VERSION ""

NS_ :

BS_:

BU_: PowertrainControlModule AtmosphericSensor SafetyRestraintSystem2 Aftertreatment_2_GasOutlet Aftertreatment_2_GasIntake DieselParticulateFilterControl Turbocharger SafetyRestraintSystem1 CabDisplay2 Aftertreatment_1_GasOutlet Aftertreatment_1_GasIntake OnBoardDataLogger OffBoardDiagnosticTool2 OffBoardDiagnosticTool1 FileServer ParkingBrakeController SeatController2 FanDriveController SteeringColumnUnit CommunicationUnitRadio CommunicationUnitSatellite CommunicationUnitCellular PropulsionBatteryCharger ChassisController2 ChassisController1 EngineValveControl AuxiliaryHeater2 AuxiliaryHeater1 ClutchUnit RampControl InformationSystem1 SuspensionSystemController2 OilSensor VehicleDynamicStability ExhaustEmissionController TransmissionDisplay2 TransmissionDisplay1 ClimateControl2 WaterPumpController RearAxleSteeringController LightingOperatorControl SeatController1 IgnitionController2 IgnitionController1 TirePressureController CabController2 CabController1 PneumaticSystemController SuspensionSystemController1 HydraulicPumpController EnduranceBrakingSystem RetarderExhaustEngine2 OnBoardDiagnosticUnit HeadwayController RetarderExhaustEngine1 CabDisplay1 ManagementComputer VirtualTerminal OffVehicleGateway PowerTakeOffFront HitchControl AuxiliaryValveControl BodyController TractorTrailerBridge1 StarterSystem ElectricalSystem VehicleSecurity VehicleNavigation AerodynamicControl ElectricalChargingSystem ClimateControl1 TripRecorder InstrumentCluster SuspensionDriveAxle2 SuspensionDriveAxle1 SuspensionSteerAxle SteeringController FuelSystem CruiseControl RetarderDriveline RetarderEngine BrakesDriveAxle2 BrakesDriveAxle1 BrakesSystemController BrakesSteerAxle AxleDrive2 AxleDrive1 AxleSteering PowerTakeOff ShiftConsoleSecondary ShiftConsolePrimary Transmission2 Transmission1 Engine2 Engine1

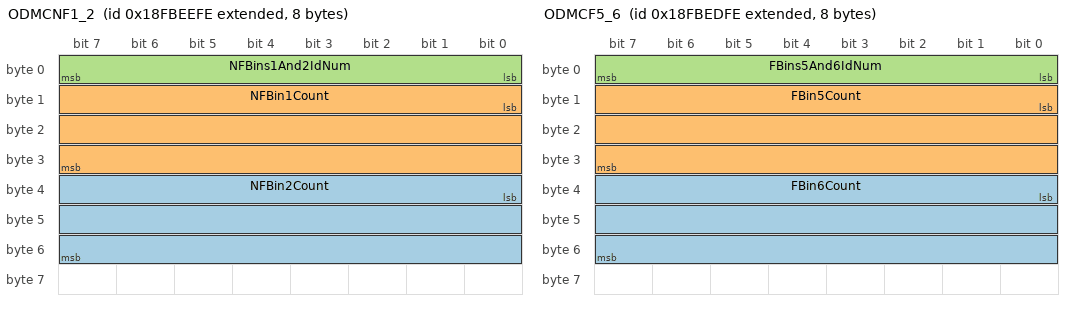
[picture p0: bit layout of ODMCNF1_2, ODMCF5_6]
BO_ 2566647550 ODMCNF1_2: 8 Vector__XXX
 SG_ NFBin2Count : 32|24@1+ (1,0) [0|16449535] "" Vector__XXX
 SG_ NFBin1Count : 8|24@1+ (1,0) [0|16449535] "" Vector__XXX
 SG_ NFBins1And2IdNum : 0|8@1+ (1,0) [0|250] "" Vector__XXX

BO_ 2566647294 ODMCF5_6: 8 Vector__XXX
 SG_ FBin6Count : 32|24@1+ (1,0) [0|16449535] "" Vector__XXX
 SG_ FBin5Count : 8|24@1+ (1,0) [0|16449535] "" Vector__XXX
 SG_ FBins5And6IdNum : 0|8@1+ (1,0) [0|250] "" Vector__XXX

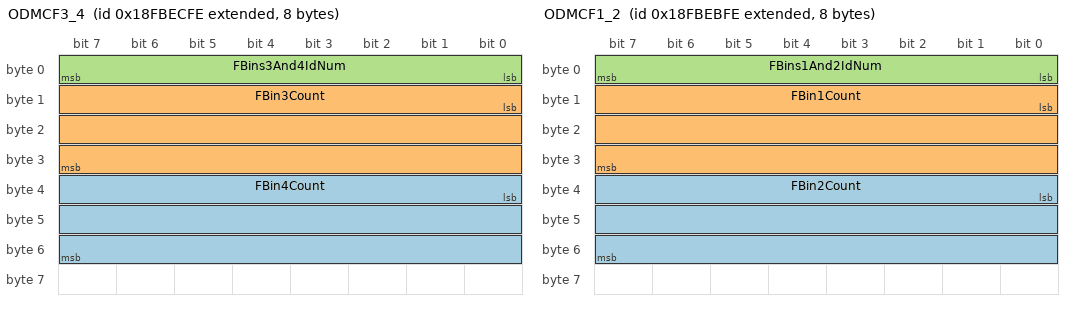
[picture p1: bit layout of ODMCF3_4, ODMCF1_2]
BO_ 2566647038 ODMCF3_4: 8 Vector__XXX
 SG_ FBin4Count : 32|24@1+ (1,0) [0|16449535] "" Vector__XXX
 SG_ FBin3Count : 8|24@1+ (1,0) [0|16449535] "" Vector__XXX
 SG_ FBins3And4IdNum : 0|8@1+ (1,0) [0|250] "" Vector__XXX

BO_ 2566646782 ODMCF1_2: 8 Vector__XXX
 SG_ FBin2Count : 32|24@1+ (1,0) [0|16449535] "" Vector__XXX
 SG_ FBin1Count : 8|24@1+ (1,0) [0|16449535] "" Vector__XXX
 SG_ FBins1And2IdNum : 0|8@1+ (1,0) [0|250] "" Vector__XXX

BO_ 2633755390 E1NET1: 8 Vector__XXX
 SG_ MACAddressOctet6 : 144|8@1+ (1,0) [0|255] "" Vector__XXX
 SG_ MACAddressOctet5 : 136|8@1+ (1,0) [0|255] "" Vector__XXX
 SG_ MACAddressOctet4 : 128|8@1+ (1,0) [0|255] "" Vector__XXX
 SG_ MACAddressOctet3 : 120|8@1+ (1,0) [0|255] "" Vector__XXX
 SG_ MACAddressOctet2 : 112|8@1+ (1,0) [0|255] "" Vector__XXX
 SG_ MACAddressOctet1 : 104|8@1+ (1,0) [0|255] "" Vector__XXX
 SG_ DefaultGatewayOctet4 : 96|8@1+ (1,0) [0|255] "" Vector__XXX
 SG_ DefaultGatewayOctet3 : 88|8@1+ (1,0) [0|255] "" Vector__XXX
 SG_ DefaultGatewayOctet2 : 80|8@1+ (1,0) [0|255] "" Vector__XXX
 SG_ DefaultGatewayOctet1 : 72|8@1+ (1,0) [0|255] "" Vector__XXX
 SG_ SubnetMaskOctet4 : 64|8@1+ (1,0) [0|255] "" Vector__XXX
 SG_ SubnetMaskOctet3 : 56|8@1+ (1,0) [0|255] "" Vector__XXX
 SG_ SubnetMaskOctet2 : 48|8@1+ (1,0) [0|255] "" Vector__XXX
 SG_ SubnetMaskOctet1 : 40|8@1+ (1,0) [0|255] "" Vector__XXX
 SG_ IPv4AddressOctet4 : 32|8@1+ (1,0) [0|255] "" Vector__XXX
 SG_ IPv4AddressOctet3 : 24|8@1+ (1,0) [0|255] "" Vector__XXX
 SG_ IPv4AddressOctet2 : 16|8@1+ (1,0) [0|255] "" Vector__XXX
 SG_ IPv4AddressOctet1 : 8|8@1+ (1,0) [0|255] "" Vector__XXX
 SG_ LinkStatus : 4|2@1+ (1,0) [0|3] "" Vector__XXX
 SG_ DHCPStatus : 0|4@1+ (1,0) [0|15] "" Vector__XXX

BO_ 2633755134 E1NET2: 8 Vector__XXX
 SG_ HostName : 0|8@1+ (1,0) [0|255] "" Vector__XXX

BO_ 2633754878 ASI2: 8 Vector__XXX
 SG_ TotalDEFUsed : 0|32@1+ (0.5,0) [0|2105540607.5] "l" Vector__XXX

BO_ 2633754622 SCROII5: 8 Vector__XXX
 SG_ EmergOvrdTotalActivationTime : 32|32@1+ (1,0) [0|4211081215] "s" Vector__XXX
 SG_ AFT1SCRInHiTempTime : 0|32@1+ (1,0) [0|4211081215] "s" Vector__XXX

BO_ 2365318910 HVESFC: 8 Vector__XXX
 SG_ HVESFanInstance15 : 46|1@1+ (1,0) [0|1] "" Vector__XXX
 SG_ HVESFanInstance14 : 45|1@1+ (1,0) [0|1] "" Vector__XXX
 SG_ HVESFanInstance13 : 44|1@1+ (1,0) [0|1] "" Vector__XXX
 SG_ HVESFanInstance12 : 43|1@1+ (1,0) [0|1] "" Vector__XXX
 SG_ HVESFanInstance11 : 42|1@1+ (1,0) [0|1] "" Vector__XXX
 SG_ HVESFanInstance10 : 41|1@1+ (1,0) [0|1] "" Vector__XXX
 SG_ HVESFanInstance9 : 40|1@1+ (1,0) [0|1] "" Vector__XXX
 SG_ HVESFanInstance8 : 39|1@1+ (1,0) [0|1] "" Vector__XXX
 SG_ HVESFanInstance7 : 38|1@1+ (1,0) [0|1] "" Vector__XXX
 SG_ HVESFanInstance6 : 37|1@1+ (1,0) [0|1] "" Vector__XXX
 SG_ HVESFanInstance5 : 36|1@1+ (1,0) [0|1] "" Vector__XXX
 SG_ HVESFanInstance4 : 35|1@1+ (1,0) [0|1] "" Vector__XXX
 SG_ HVESFanInstance3 : 34|1@1+ (1,0) [0|1] "" Vector__XXX
 SG_ HVESFanInstance2 : 33|1@1+ (1,0) [0|1] "" Vector__XXX
 SG_ HVESFanInstance1 : 32|1@1+ (1,0) [0|1] "" Vector__XXX
 SG_ HVESFanPercentSpdCmd : 24|8@1+ (0.4,0) [0|100] "%" Vector__XXX
 SG_ HVESFanSpdCmd : 8|16@1+ (0.5,0) [0|32127.5] "rpm" Vector__XXX
 SG_ HVESFanPwrHold : 2|2@1+ (1,0) [0|3] "" Vector__XXX
 SG_ HVESFanEnableCmd : 0|2@1+ (1,0) [0|3] "" Vector__XXX

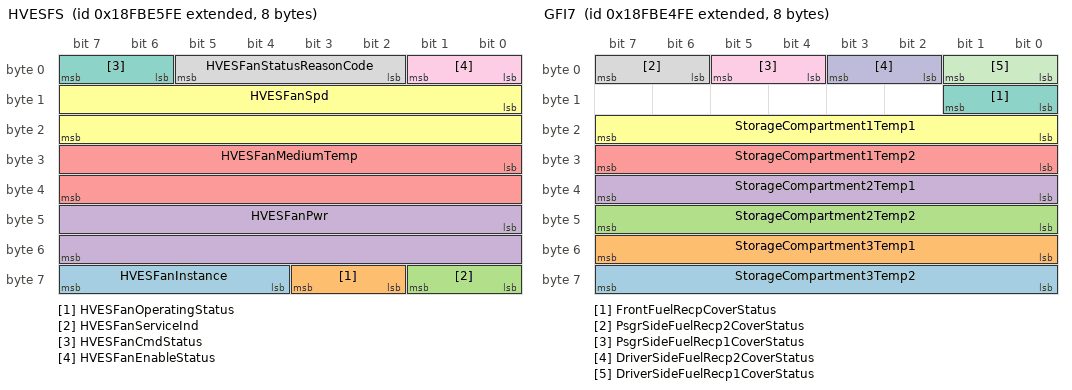
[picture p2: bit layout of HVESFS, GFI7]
BO_ 2566645246 HVESFS: 8 Vector__XXX
 SG_ HVESFanInstance : 60|4@1+ (1,0) [0|15] "" Vector__XXX
 SG_ HVESFanOperatingStatus : 58|2@1+ (1,0) [0|3] "" Vector__XXX
 SG_ HVESFanServiceInd : 56|2@1+ (1,0) [0|3] "" Vector__XXX
 SG_ HVESFanPwr : 40|16@1+ (0.5,0) [0|32127.5] "W" Vector__XXX
 SG_ HVESFanMediumTemp : 24|16@1+ (0.03125,-273) [-273|1734.96875] "캜" Vector__XXX
 SG_ HVESFanSpd : 8|16@1+ (0.5,0) [0|32127.5] "rpm" Vector__XXX
 SG_ HVESFanCmdStatus : 6|2@1+ (1,0) [0|3] "" Vector__XXX
 SG_ HVESFanStatusReasonCode : 2|4@1+ (1,0) [0|15] "" Vector__XXX
 SG_ HVESFanEnableStatus : 0|2@1+ (1,0) [0|3] "" Vector__XXX

BO_ 2566644990 GFI7: 8 Vector__XXX
 SG_ StorageCompartment3Temp2 : 56|8@1+ (1,-40) [-40|210] "캜" Vector__XXX
 SG_ StorageCompartment3Temp1 : 48|8@1+ (1,-40) [-40|210] "캜" Vector__XXX
 SG_ StorageCompartment2Temp2 : 40|8@1+ (1,-40) [-40|210] "캜" Vector__XXX
 SG_ StorageCompartment2Temp1 : 32|8@1+ (1,-40) [-40|210] "캜" Vector__XXX
 SG_ StorageCompartment1Temp2 : 24|8@1+ (1,-40) [-40|210] "캜" Vector__XXX
 SG_ StorageCompartment1Temp1 : 16|8@1+ (1,-40) [-40|210] "캜" Vector__XXX
 SG_ FrontFuelRecpCoverStatus : 8|2@1+ (1,0) [0|3] "" Vector__XXX
 SG_ PsgrSideFuelRecp2CoverStatus : 6|2@1+ (1,0) [0|3] "" Vector__XXX
 SG_ PsgrSideFuelRecp1CoverStatus : 4|2@1+ (1,0) [0|3] "" Vector__XXX
 SG_ DriverSideFuelRecp2CoverStatus : 2|2@1+ (1,0) [0|3] "" Vector__XXX
 SG_ DriverSideFuelRecp1CoverStatus : 0|2@1+ (1,0) [0|3] "" Vector__XXX

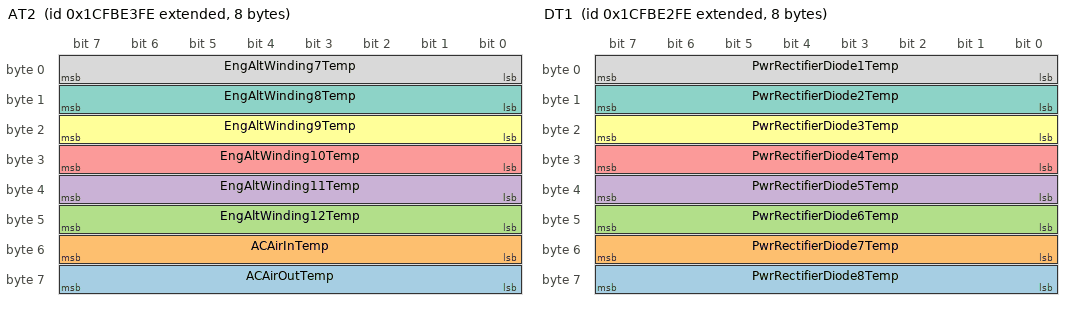
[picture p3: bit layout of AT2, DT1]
BO_ 2633753598 AT2: 8 Vector__XXX
 SG_ ACAirOutTemp : 56|8@1+ (1,-40) [-40|210] "캜" Vector__XXX
 SG_ ACAirInTemp : 48|8@1+ (1,-40) [-40|210] "캜" Vector__XXX
 SG_ EngAltWinding12Temp : 40|8@1+ (1,-40) [-40|210] "캜" Vector__XXX
 SG_ EngAltWinding11Temp : 32|8@1+ (1,-40) [-40|210] "캜" Vector__XXX
 SG_ EngAltWinding10Temp : 24|8@1+ (1,-40) [-40|210] "캜" Vector__XXX
 SG_ EngAltWinding9Temp : 16|8@1+ (1,-40) [-40|210] "캜" Vector__XXX
 SG_ EngAltWinding8Temp : 8|8@1+ (1,-40) [-40|210] "캜" Vector__XXX
 SG_ EngAltWinding7Temp : 0|8@1+ (1,-40) [-40|210] "캜" Vector__XXX

BO_ 2633753342 DT1: 8 Vector__XXX
 SG_ PwrRectifierDiode8Temp : 56|8@1+ (1,-40) [-40|210] "캜" Vector__XXX
 SG_ PwrRectifierDiode7Temp : 48|8@1+ (1,-40) [-40|210] "캜" Vector__XXX
 SG_ PwrRectifierDiode6Temp : 40|8@1+ (1,-40) [-40|210] "캜" Vector__XXX
 SG_ PwrRectifierDiode5Temp : 32|8@1+ (1,-40) [-40|210] "캜" Vector__XXX
 SG_ PwrRectifierDiode4Temp : 24|8@1+ (1,-40) [-40|210] "캜" Vector__XXX
 SG_ PwrRectifierDiode3Temp : 16|8@1+ (1,-40) [-40|210] "캜" Vector__XXX
 SG_ PwrRectifierDiode2Temp : 8|8@1+ (1,-40) [-40|210] "캜" Vector__XXX
 SG_ PwrRectifierDiode1Temp : 0|8@1+ (1,-40) [-40|210] "캜" Vector__XXX

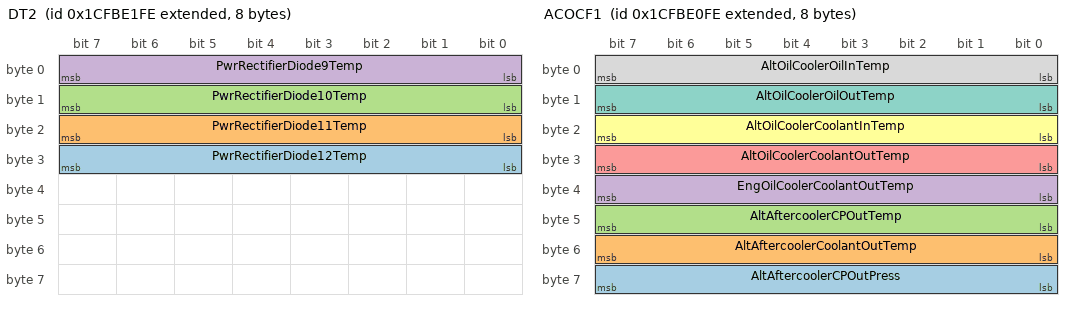
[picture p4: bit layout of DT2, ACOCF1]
BO_ 2633753086 DT2: 8 Vector__XXX
 SG_ PwrRectifierDiode12Temp : 24|8@1+ (1,-40) [-40|210] "캜" Vector__XXX
 SG_ PwrRectifierDiode11Temp : 16|8@1+ (1,-40) [-40|210] "캜" Vector__XXX
 SG_ PwrRectifierDiode10Temp : 8|8@1+ (1,-40) [-40|210] "캜" Vector__XXX
 SG_ PwrRectifierDiode9Temp : 0|8@1+ (1,-40) [-40|210] "캜" Vector__XXX

BO_ 2633752830 ACOCF1: 8 Vector__XXX
 SG_ AltAftercoolerCPOutPress : 56|8@1+ (2,0) [0|500] "kPa" Vector__XXX
 SG_ AltAftercoolerCoolantOutTemp : 48|8@1+ (1,-40) [-40|210] "캜" Vector__XXX
 SG_ AltAftercoolerCPOutTemp : 40|8@1+ (1,-40) [-40|210] "캜" Vector__XXX
 SG_ EngOilCoolerCoolantOutTemp : 32|8@1+ (1,-40) [-40|210] "캜" Vector__XXX
 SG_ AltOilCoolerCoolantOutTemp : 24|8@1+ (1,-40) [-40|210] "캜" Vector__XXX
 SG_ AltOilCoolerCoolantInTemp : 16|8@1+ (1,-40) [-40|210] "캜" Vector__XXX
 SG_ AltOilCoolerOilOutTemp : 8|8@1+ (1,-40) [-40|210] "캜" Vector__XXX
 SG_ AltOilCoolerOilInTemp : 0|8@1+ (1,-40) [-40|210] "캜" Vector__XXX

BO_ 2566643710 IC3: 8 Vector__XXX
 SG_ EngMixer2InPress : 16|16@1+ (0.1,0) [0|6425.5] "kPa" Vector__XXX
 SG_ EngMixer1InPress : 0|16@1+ (0.1,0) [0|6425.5] "kPa" Vector__XXX

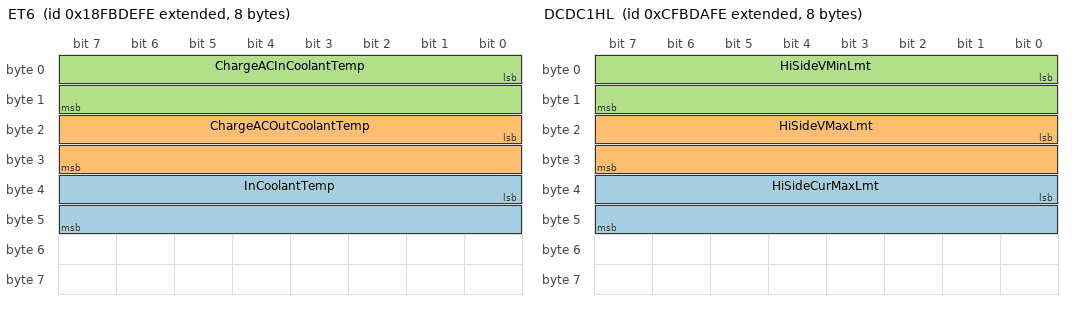
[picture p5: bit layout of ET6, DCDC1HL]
BO_ 2566643454 ET6: 8 Vector__XXX
 SG_ InCoolantTemp : 32|16@1+ (0.03125,-273) [-273|1734.96875] "캜" Vector__XXX
 SG_ ChargeACOutCoolantTemp : 16|16@1+ (0.03125,-273) [-273|1734.96875] "캜" Vector__XXX
 SG_ ChargeACInCoolantTemp : 0|16@1+ (0.03125,-273) [-273|1734.96875] "캜" Vector__XXX

BO_ 2566643198 DC3: 8 Vector__XXX
 SG_ EnableStatusOfDoor20 : 58|2@1+ (1,0) [0|3] "" Vector__XXX
 SG_ OpenStatusOfDoor20 : 56|2@1+ (1,0) [0|3] "" Vector__XXX
 SG_ LockStatusOfDoor20 : 54|2@1+ (1,0) [0|3] "" Vector__XXX
 SG_ EnableStatusOfDoor19 : 52|2@1+ (1,0) [0|3] "" Vector__XXX
 SG_ OpenStatusOfDoor19 : 50|2@1+ (1,0) [0|3] "" Vector__XXX
 SG_ LockStatusOfDoor19 : 48|2@1+ (1,0) [0|3] "" Vector__XXX
 SG_ EnableStatusOfDoor18 : 46|2@1+ (1,0) [0|3] "" Vector__XXX
 SG_ OpenStatusOfDoor18 : 44|2@1+ (1,0) [0|3] "" Vector__XXX
 SG_ LockStatusOfDoor18 : 42|2@1+ (1,0) [0|3] "" Vector__XXX
 SG_ EnableStatusOfDoor17 : 40|2@1+ (1,0) [0|3] "" Vector__XXX
 SG_ OpenStatusOfDoor17 : 38|2@1+ (1,0) [0|3] "" Vector__XXX
 SG_ LockStatusOfDoor17 : 36|2@1+ (1,0) [0|3] "" Vector__XXX
 SG_ EnableStatusOfDoor16 : 34|2@1+ (1,0) [0|3] "" Vector__XXX
 SG_ OpenStatusOfDoor16 : 32|2@1+ (1,0) [0|3] "" Vector__XXX
 SG_ LockStatusOfDoor16 : 30|2@1+ (1,0) [0|3] "" Vector__XXX
 SG_ EnableStatusOfDoor15 : 28|2@1+ (1,0) [0|3] "" Vector__XXX
 SG_ OpenStatusOfDoor15 : 26|2@1+ (1,0) [0|3] "" Vector__XXX
 SG_ LockStatusOfDoor15 : 24|2@1+ (1,0) [0|3] "" Vector__XXX
 SG_ EnableStatusOfDoor14 : 22|2@1+ (1,0) [0|3] "" Vector__XXX
 SG_ OpenStatusOfDoor14 : 20|2@1+ (1,0) [0|3] "" Vector__XXX
 SG_ LockStatusOfDoor14 : 18|2@1+ (1,0) [0|3] "" Vector__XXX
 SG_ EnableStatusOfDoor13 : 16|2@1+ (1,0) [0|3] "" Vector__XXX
 SG_ OpenStatusOfDoor13 : 14|2@1+ (1,0) [0|3] "" Vector__XXX
 SG_ LockStatusOfDoor13 : 12|2@1+ (1,0) [0|3] "" Vector__XXX
 SG_ EnableStatusOfDoor12 : 10|2@1+ (1,0) [0|3] "" Vector__XXX
 SG_ OpenStatusOfDoor12 : 8|2@1+ (1,0) [0|3] "" Vector__XXX
 SG_ LockStatusOfDoor12 : 6|2@1+ (1,0) [0|3] "" Vector__XXX
 SG_ EnableStatusOfDoor11 : 4|2@1+ (1,0) [0|3] "" Vector__XXX
 SG_ OpenStatusOfDoor11 : 2|2@1+ (1,0) [0|3] "" Vector__XXX
 SG_ LockStatusOfDoor11 : 0|2@1+ (1,0) [0|3] "" Vector__XXX

BO_ 2566642942 DC4: 8 Vector__XXX
 SG_ EnableStatusOfDoor30 : 58|2@1+ (1,0) [0|3] "" Vector__XXX
 SG_ OpenStatusOfDoor30 : 56|2@1+ (1,0) [0|3] "" Vector__XXX
 SG_ LockStatusOfDoor30 : 54|2@1+ (1,0) [0|3] "" Vector__XXX
 SG_ EnableStatusOfDoor29 : 52|2@1+ (1,0) [0|3] "" Vector__XXX
 SG_ OpenStatusOfDoor29 : 50|2@1+ (1,0) [0|3] "" Vector__XXX
 SG_ LockStatusOfDoor29 : 48|2@1+ (1,0) [0|3] "" Vector__XXX
 SG_ EnableStatusOfDoor28 : 46|2@1+ (1,0) [0|3] "" Vector__XXX
 SG_ OpenStatusOfDoor28 : 44|2@1+ (1,0) [0|3] "" Vector__XXX
 SG_ LockStatusOfDoor28 : 42|2@1+ (1,0) [0|3] "" Vector__XXX
 SG_ EnableStatusOfDoor27 : 40|2@1+ (1,0) [0|3] "" Vector__XXX
 SG_ OpenStatusOfDoor27 : 38|2@1+ (1,0) [0|3] "" Vector__XXX
 SG_ LockStatusOfDoor27 : 36|2@1+ (1,0) [0|3] "" Vector__XXX
 SG_ EnableStatusOfDoor26 : 34|2@1+ (1,0) [0|3] "" Vector__XXX
 SG_ OpenStatusOfDoor26 : 32|2@1+ (1,0) [0|3] "" Vector__XXX
 SG_ LockStatusOfDoor26 : 30|2@1+ (1,0) [0|3] "" Vector__XXX
 SG_ EnableStatusOfDoor25 : 28|2@1+ (1,0) [0|3] "" Vector__XXX
 SG_ OpenStatusOfDoor25 : 26|2@1+ (1,0) [0|3] "" Vector__XXX
 SG_ LockStatusOfDoor25 : 24|2@1+ (1,0) [0|3] "" Vector__XXX
 SG_ EnableStatusOfDoor24 : 22|2@1+ (1,0) [0|3] "" Vector__XXX
 SG_ OpenStatusOfDoor24 : 20|2@1+ (1,0) [0|3] "" Vector__XXX
 SG_ LockStatusOfDoor24 : 18|2@1+ (1,0) [0|3] "" Vector__XXX
 SG_ EnableStatusOfDoor23 : 16|2@1+ (1,0) [0|3] "" Vector__XXX
 SG_ OpenStatusOfDoor23 : 14|2@1+ (1,0) [0|3] "" Vector__XXX
 SG_ LockStatusOfDoor23 : 12|2@1+ (1,0) [0|3] "" Vector__XXX
 SG_ EnableStatusOfDoor22 : 10|2@1+ (1,0) [0|3] "" Vector__XXX
 SG_ OpenStatusOfDoor22 : 8|2@1+ (1,0) [0|3] "" Vector__XXX
 SG_ LockStatusOfDoor22 : 6|2@1+ (1,0) [0|3] "" Vector__XXX
 SG_ EnableStatusOfDoor21 : 4|2@1+ (1,0) [0|3] "" Vector__XXX
 SG_ OpenStatusOfDoor21 : 2|2@1+ (1,0) [0|3] "" Vector__XXX
 SG_ LockStatusOfDoor21 : 0|2@1+ (1,0) [0|3] "" Vector__XXX

BO_ 2365315838 DCDC1HL: 8 Vector__XXX
 SG_ HiSideCurMaxLmt : 32|16@1+ (0.05,0) [0|3212.75] "A" Vector__XXX
 SG_ HiSideVMaxLmt : 16|16@1+ (0.05,0) [0|3212.75] "V" Vector__XXX
 SG_ HiSideVMinLmt : 0|16@1+ (0.05,0) [0|3212.75] "V" Vector__XXX

BO_ 2365315582 DCDC1LL: 8 Vector__XXX
 SG_ LowSideCurMaxLmt : 32|16@1+ (0.05,0) [0|3212.75] "A" Vector__XXX
 SG_ LowSideVMaxLmt : 16|16@1+ (0.01,0) [0|642.55] "V" Vector__XXX
 SG_ LowSideVMinLmt : 0|16@1+ (0.01,0) [0|642.55] "V" Vector__XXX

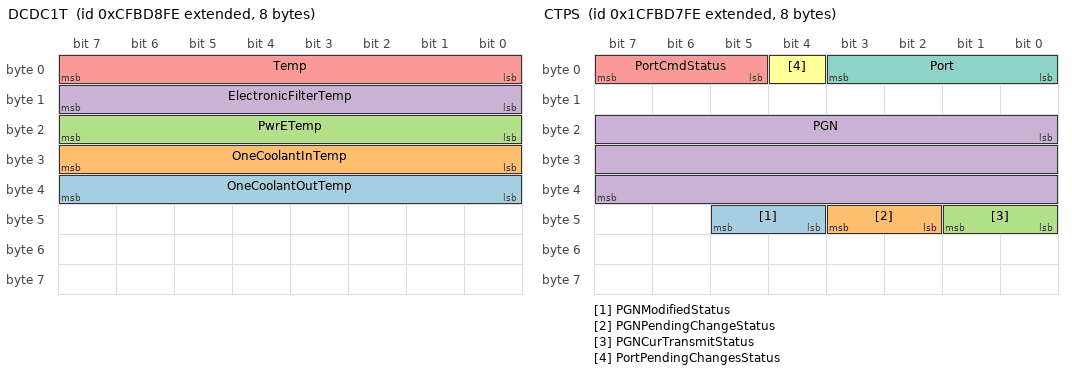
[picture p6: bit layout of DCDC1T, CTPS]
BO_ 2365315326 DCDC1T: 8 Vector__XXX
 SG_ OneCoolantOutTemp : 32|8@1+ (1,-40) [-40|210] "캜" Vector__XXX
 SG_ OneCoolantInTemp : 24|8@1+ (1,-40) [-40|210] "캜" Vector__XXX
 SG_ PwrETemp : 16|8@1+ (1,-40) [-40|210] "캜" Vector__XXX
 SG_ ElectronicFilterTemp : 8|8@1+ (1,-40) [-40|210] "캜" Vector__XXX
 SG_ Temp : 0|8@1+ (1,-40) [-40|210] "캜" Vector__XXX

BO_ 2633750526 CTPS: 8 Vector__XXX
 SG_ PGNModifiedStatus : 44|2@1+ (1,0) [0|3] "" Vector__XXX
 SG_ PGNPendingChangeStatus : 42|2@1+ (1,0) [0|3] "" Vector__XXX
 SG_ PGNCurTransmitStatus : 40|2@1+ (1,0) [0|3] "" Vector__XXX
 SG_ PGN : 16|24@1+ (1,0) [0|16777215] "" Vector__XXX
 SG_ PortCmdStatus : 5|3@1+ (1,0) [0|7] "" Vector__XXX
 SG_ PortPendingChangesStatus : 4|1@1+ (1,0) [0|1] "" Vector__XXX
 SG_ Port : 0|4@1+ (1,0) [0|15] "" Vector__XXX

BO_ 2566641406 EEC21: 8 Vector__XXX
 SG_ ExhManifoldPress2 : 16|16@1+ (0.1,0) [0|6425.5] "kPa" Vector__XXX
 SG_ ExhManifoldPress1 : 0|16@1+ (0.1,0) [0|6425.5] "kPa" Vector__XXX

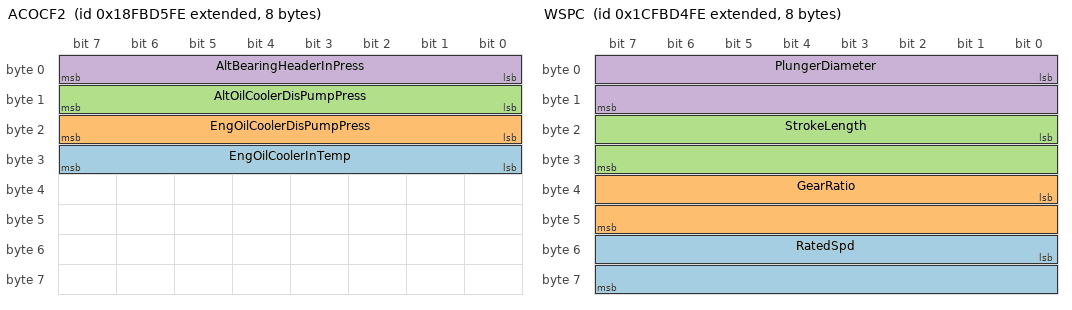
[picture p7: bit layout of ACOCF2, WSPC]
BO_ 2566641150 ACOCF2: 8 Vector__XXX
 SG_ EngOilCoolerInTemp : 24|8@1+ (1,-40) [-40|210] "캜" Vector__XXX
 SG_ EngOilCoolerDisPumpPress : 16|8@1+ (2,0) [0|500] "kPa" Vector__XXX
 SG_ AltOilCoolerDisPumpPress : 8|8@1+ (2,0) [0|500] "kPa" Vector__XXX
 SG_ AltBearingHeaderInPress : 0|8@1+ (2,0) [0|500] "kPa" Vector__XXX

BO_ 2633749758 WSPC: 8 Vector__XXX
 SG_ RatedSpd : 48|16@1+ (0.125,0) [0|8031.875] "rpm" Vector__XXX
 SG_ GearRatio : 32|16@1+ (0.001,0) [0|64.255] "" Vector__XXX
 SG_ StrokeLength : 16|16@1+ (1,0) [0|64255] "mm" Vector__XXX
 SG_ PlungerDiameter : 0|16@1+ (1,0) [0|64255] "mm" Vector__XXX

BO_ 2633749502 WSPT: 8 Vector__XXX
 SG_ CycleCount : 96|32@1+ (1,0) [0|4211081215] "" Vector__XXX
 SG_ WorkingHours : 64|32@1+ (1,0) [0|4211081215] "s" Vector__XXX
 SG_ PwrEndWorkingHours : 32|32@1+ (1,0) [0|4211081215] "s" Vector__XXX
 SG_ FluidEndWorkingHours : 0|32@1+ (1,0) [0|4211081215] "s" Vector__XXX

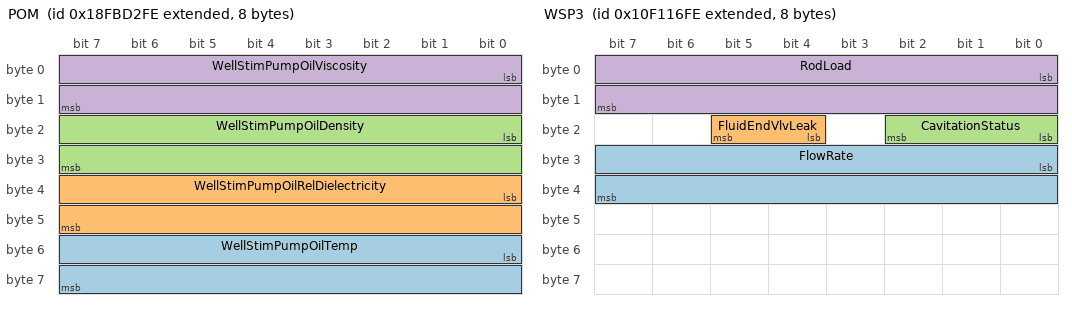
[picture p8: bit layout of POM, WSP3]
BO_ 2566640382 POM: 8 Vector__XXX
 SG_ WellStimPumpOilTemp : 48|16@1+ (0.03125,-273) [-273|1734.96875] "캜" Vector__XXX
 SG_ WellStimPumpOilRelDielectricity : 32|16@1+ (0.0001220703125,0) [0|7.844] "" Vector__XXX
 SG_ WellStimPumpOilDensity : 16|16@1+ (3.052E-005,0) [0|1.961] "g/cc" Vector__XXX
 SG_ WellStimPumpOilViscosity : 0|16@1+ (0.015625,0) [0|1003.984375] "Cp" Vector__XXX

BO_ 2431719166 WSP3: 8 Vector__XXX
 SG_ FlowRate : 24|16@1+ (0.5,0) [0|32127.5] "l/min" Vector__XXX
 SG_ FluidEndVlvLeak : 20|2@1+ (1,0) [0|3] "" Vector__XXX
 SG_ CavitationStatus : 16|3@1+ (1,0) [0|7] "" Vector__XXX
 SG_ RodLoad : 0|16@1+ (5,0) [0|321275] "kN" Vector__XXX

BO_ 2364610046 DCDC1SBS: 8 Vector__XXX
 SG_ SLIBatTermTemp : 32|8@1+ (1,-40) [-40|210] "캜" Vector__XXX
 SG_ SLIBatTermCur : 16|16@1+ (0.1,-3212.7) [-3212.7|3212.8] "A" Vector__XXX
 SG_ SLIBatTermV : 0|16@1+ (0.01,0) [0|642.55] "V" Vector__XXX

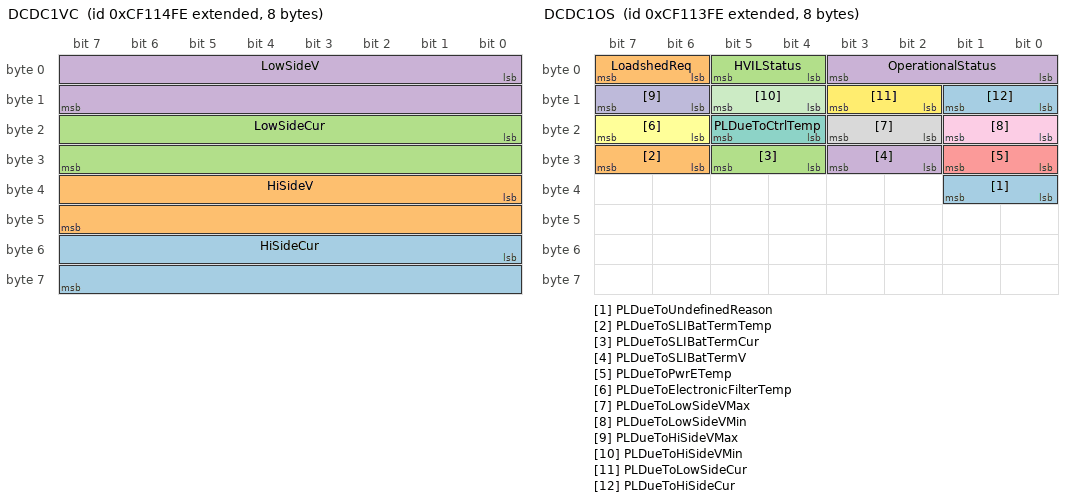
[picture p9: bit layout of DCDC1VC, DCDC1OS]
BO_ 2364609790 DCDC1VC: 8 Vector__XXX
 SG_ HiSideCur : 48|16@1+ (0.1,-3212.7) [-3212.7|3212.8] "A" Vector__XXX
 SG_ HiSideV : 32|16@1+ (0.05,0) [0|3212.75] "V" Vector__XXX
 SG_ LowSideCur : 16|16@1+ (0.1,-3212.7) [-3212.7|3212.8] "A" Vector__XXX
 SG_ LowSideV : 0|16@1+ (0.01,0) [0|642.55] "V" Vector__XXX

BO_ 2364609534 DCDC1OS: 8 Vector__XXX
 SG_ PLDueToUndefinedReason : 32|2@1+ (1,0) [0|3] "" Vector__XXX
 SG_ PLDueToSLIBatTermTemp : 30|2@1+ (1,0) [0|3] "" Vector__XXX
 SG_ PLDueToSLIBatTermCur : 28|2@1+ (1,0) [0|3] "" Vector__XXX
 SG_ PLDueToSLIBatTermV : 26|2@1+ (1,0) [0|3] "" Vector__XXX
 SG_ PLDueToPwrETemp : 24|2@1+ (1,0) [0|3] "" Vector__XXX
 SG_ PLDueToElectronicFilterTemp : 22|2@1+ (1,0) [0|3] "" Vector__XXX
 SG_ PLDueToCtrlTemp : 20|2@1+ (1,0) [0|3] "" Vector__XXX
 SG_ PLDueToLowSideVMax : 18|2@1+ (1,0) [0|3] "" Vector__XXX
 SG_ PLDueToLowSideVMin : 16|2@1+ (1,0) [0|3] "" Vector__XXX
 SG_ PLDueToHiSideVMax : 14|2@1+ (1,0) [0|3] "" Vector__XXX
 SG_ PLDueToHiSideVMin : 12|2@1+ (1,0) [0|3] "" Vector__XXX
 SG_ PLDueToLowSideCur : 10|2@1+ (1,0) [0|3] "" Vector__XXX
 SG_ PLDueToHiSideCur : 8|2@1+ (1,0) [0|3] "" Vector__XXX
 SG_ LoadshedReq : 6|2@1+ (1,0) [0|3] "" Vector__XXX
 SG_ HVILStatus : 4|2@1+ (1,0) [0|3] "" Vector__XXX
 SG_ OperationalStatus : 0|4@1+ (1,0) [0|15] "" Vector__XXX

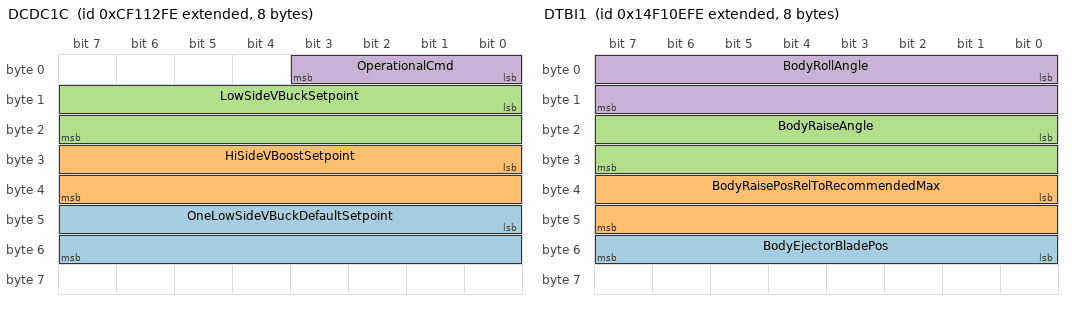
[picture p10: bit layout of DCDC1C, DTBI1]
BO_ 2364609278 DCDC1C: 8 Vector__XXX
 SG_ OneLowSideVBuckDefaultSetpoint : 40|16@1+ (0.01,0) [0|642.55] "V" Vector__XXX
 SG_ HiSideVBoostSetpoint : 24|16@1+ (0.05,0) [0|3212.75] "V" Vector__XXX
 SG_ LowSideVBuckSetpoint : 8|16@1+ (0.01,0) [0|642.55] "V" Vector__XXX
 SG_ OperationalCmd : 0|4@1+ (1,0) [0|15] "" Vector__XXX

BO_ 2431717886 GFP3: 8 Vector__XXX
 SG_ EngFuelVlv1DiffPress : 0|16@1+ (0.0078125,-100) [-100|401.99] "kPa" Vector__XXX

BO_ 2297499902 B2: 8 Vector__XXX
 SG_ BrkPedalSw2 : 16|2@1+ (1,0) [0|3] "" Vector__XXX
 SG_ DemandedBrkAppPress : 0|16@1+ (0.1,0) [0|6425.5] "kPa" Vector__XXX

BO_ 2364608510 EOI2: 8 Vector__XXX
 SG_ PwrDerateReq : 16|16@1+ (0.5,0) [0|32127.5] "kW" Vector__XXX
 SG_ SelfInducedDerateLoad : 0|16@1+ (0.5,0) [0|32127.5] "kW" Vector__XXX

BO_ 2498825982 DTBI1: 8 Vector__XXX
 SG_ BodyEjectorBladePos : 48|8@1+ (0.4,0) [0|100] "%" Vector__XXX
 SG_ BodyRaisePosRelToRecommendedMax : 32|16@1+ (0.005,-150) [-150|171.275] "%" Vector__XXX
 SG_ BodyRaiseAngle : 16|16@1+ (0.0078125,-200) [-200|301.99] "deg" Vector__XXX
 SG_ BodyRollAngle : 0|16@1+ (0.0078125,-200) [-200|301.99] "deg" Vector__XXX

BO_ 2565934590 GFI6: 8 Vector__XXX
 SG_ EngFuelVlv2DiffPress : 0|16@1+ (0.1,0) [0|6425.5] "kPa" Vector__XXX

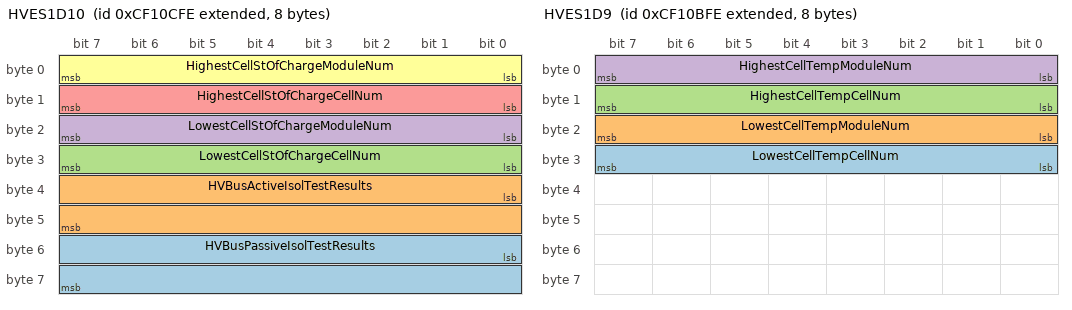
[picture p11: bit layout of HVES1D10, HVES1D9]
BO_ 2364607742 HVES1D10: 8 Vector__XXX
 SG_ HVBusPassiveIsolTestResults : 48|16@1+ (0.1,0) [0|6425.5] "ohm/V" Vector__XXX
 SG_ HVBusActiveIsolTestResults : 32|16@1+ (0.1,0) [0|6425.5] "ohm/V" Vector__XXX
 SG_ LowestCellStOfChargeCellNum : 24|8@1+ (1,0) [0|250] "" Vector__XXX
 SG_ LowestCellStOfChargeModuleNum : 16|8@1+ (1,0) [0|250] "" Vector__XXX
 SG_ HighestCellStOfChargeCellNum : 8|8@1+ (1,0) [0|250] "" Vector__XXX
 SG_ HighestCellStOfChargeModuleNum : 0|8@1+ (1,0) [0|250] "" Vector__XXX

BO_ 2364607486 HVES1D9: 8 Vector__XXX
 SG_ LowestCellTempCellNum : 24|8@1+ (1,0) [0|250] "" Vector__XXX
 SG_ LowestCellTempModuleNum : 16|8@1+ (1,0) [0|250] "" Vector__XXX
 SG_ HighestCellTempCellNum : 8|8@1+ (1,0) [0|250] "" Vector__XXX
 SG_ HighestCellTempModuleNum : 0|8@1+ (1,0) [0|250] "" Vector__XXX

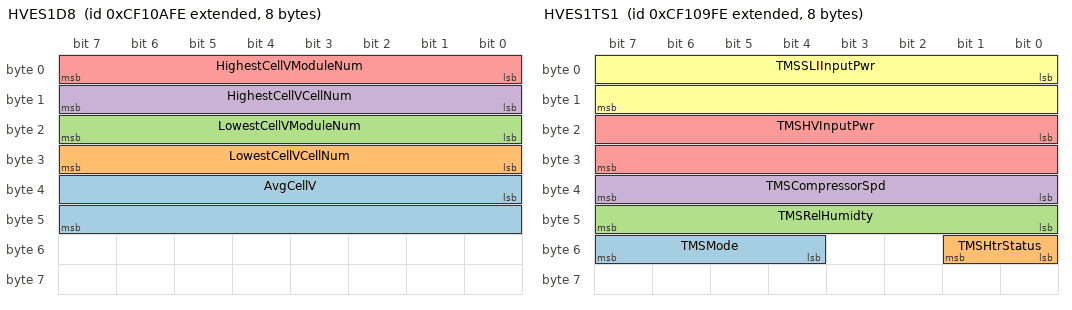
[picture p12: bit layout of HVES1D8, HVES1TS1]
BO_ 2364607230 HVES1D8: 8 Vector__XXX
 SG_ AvgCellV : 32|16@1+ (0.001,0) [0|64.255] "V" Vector__XXX
 SG_ LowestCellVCellNum : 24|8@1+ (1,0) [0|250] "" Vector__XXX
 SG_ LowestCellVModuleNum : 16|8@1+ (1,0) [0|250] "" Vector__XXX
 SG_ HighestCellVCellNum : 8|8@1+ (1,0) [0|250] "" Vector__XXX
 SG_ HighestCellVModuleNum : 0|8@1+ (1,0) [0|250] "" Vector__XXX

BO_ 2364606974 HVES1TS1: 8 Vector__XXX
 SG_ TMSMode : 52|4@1+ (1,0) [0|15] "" Vector__XXX
 SG_ TMSHtrStatus : 48|2@1+ (1,0) [0|3] "" Vector__XXX
 SG_ TMSRelHumidty : 40|8@1+ (0.4,0) [0|100] "%" Vector__XXX
 SG_ TMSCompressorSpd : 32|8@1+ (32,0) [0|8000] "rpm" Vector__XXX
 SG_ TMSHVInputPwr : 16|16@1+ (0.5,0) [0|32127.5] "W" Vector__XXX
 SG_ TMSSLIInputPwr : 0|16@1+ (0.5,0) [0|32127.5] "W" Vector__XXX

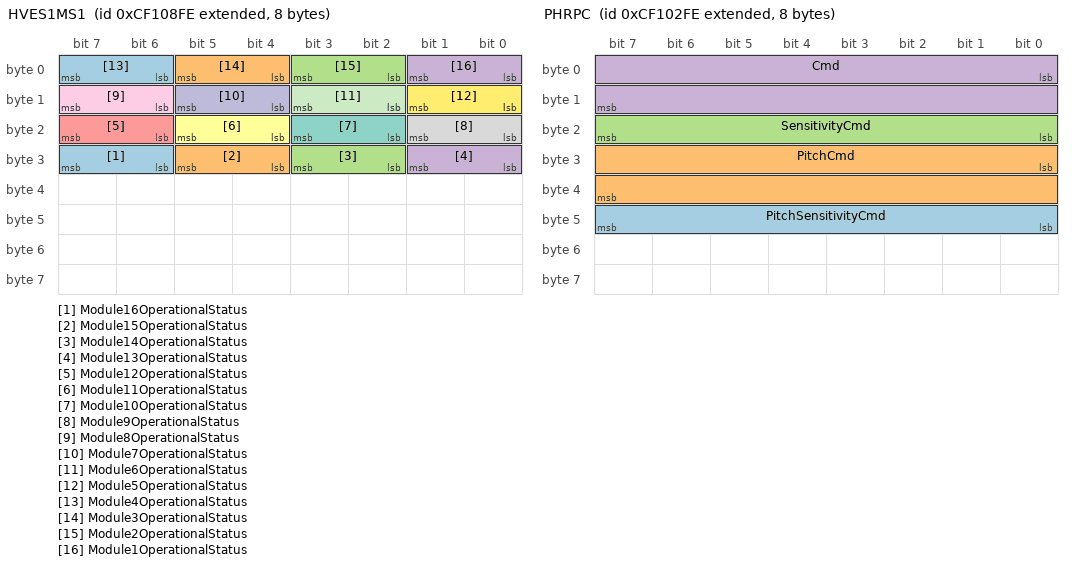
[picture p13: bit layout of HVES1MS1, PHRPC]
BO_ 2364606718 HVES1MS1: 8 Vector__XXX
 SG_ Module16OperationalStatus : 30|2@1+ (1,0) [0|3] "" Vector__XXX
 SG_ Module15OperationalStatus : 28|2@1+ (1,0) [0|3] "" Vector__XXX
 SG_ Module14OperationalStatus : 26|2@1+ (1,0) [0|3] "" Vector__XXX
 SG_ Module13OperationalStatus : 24|2@1+ (1,0) [0|3] "" Vector__XXX
 SG_ Module12OperationalStatus : 22|2@1+ (1,0) [0|3] "" Vector__XXX
 SG_ Module11OperationalStatus : 20|2@1+ (1,0) [0|3] "" Vector__XXX
 SG_ Module10OperationalStatus : 18|2@1+ (1,0) [0|3] "" Vector__XXX
 SG_ Module9OperationalStatus : 16|2@1+ (1,0) [0|3] "" Vector__XXX
 SG_ Module8OperationalStatus : 14|2@1+ (1,0) [0|3] "" Vector__XXX
 SG_ Module7OperationalStatus : 12|2@1+ (1,0) [0|3] "" Vector__XXX
 SG_ Module6OperationalStatus : 10|2@1+ (1,0) [0|3] "" Vector__XXX
 SG_ Module5OperationalStatus : 8|2@1+ (1,0) [0|3] "" Vector__XXX
 SG_ Module4OperationalStatus : 6|2@1+ (1,0) [0|3] "" Vector__XXX
 SG_ Module3OperationalStatus : 4|2@1+ (1,0) [0|3] "" Vector__XXX
 SG_ Module2OperationalStatus : 2|2@1+ (1,0) [0|3] "" Vector__XXX
 SG_ Module1OperationalStatus : 0|2@1+ (1,0) [0|3] "" Vector__XXX

BO_ 2565933054 WSP2: 8 Vector__XXX
 SG_ Spd : 24|16@1+ (0.125,0) [0|8031.875] "rpm" Vector__XXX
 SG_ GearBoxOilTemp : 16|8@1+ (1,-40) [-40|210] "캜" Vector__XXX
 SG_ GearBoxOilPress : 0|16@1+ (0.1,0) [0|6425.5] "kPa" Vector__XXX

BO_ 2565932798 WSP1: 8 Vector__XXX
 SG_ DisPress : 16|16@1+ (5,0) [0|321275] "kPa" Vector__XXX
 SG_ SuctionPress : 0|16@1+ (0.1,-3212.7) [-3212.7|3212.8] "kPa" Vector__XXX

BO_ 2364605950 HPD: 8 Vector__XXX
 SG_ MechMovementAngle : 16|16@1+ (0.0078125,0) [0|359.99] "deg" Vector__XXX
 SG_ LinePress : 0|16@1+ (1,0) [0|64255] "kPa" Vector__XXX

BO_ 2565932286 ESSI2: 8 Vector__XXX
 SG_ Vour : 0|16@1+ (0.5,0) [0|32127.5] "rpm" Vector__XXX

BO_ 2364605438 GTRACE: 8 Vector__XXX
 SG_ KVArHoursExport : 32|32@1+ (1,0) [0|4211081215] "kVArh" Vector__XXX
 SG_ KWHoursExport : 0|32@1+ (1,0) [0|4211081215] "kWh" Vector__XXX

BO_ 2364605182 PHRPC: 8 Vector__XXX
 SG_ PitchSensitivityCmd : 40|8@1+ (0.4,0) [0|100] "%" Vector__XXX
 SG_ PitchCmd : 24|16@1+ (0.002,-64) [-64|64.51] "deg" Vector__XXX
 SG_ SensitivityCmd : 16|8@1+ (0.4,0) [0|100] "%" Vector__XXX
 SG_ Cmd : 0|16@1+ (0.002,-64) [-64|64.51] "deg" Vector__XXX

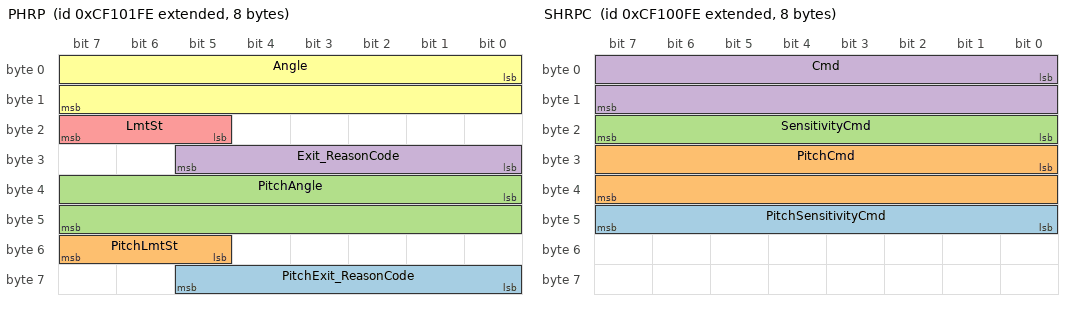
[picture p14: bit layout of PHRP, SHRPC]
BO_ 2364604926 PHRP: 8 Vector__XXX
 SG_ PitchExit_ReasonCode : 56|6@1+ (1,0) [0|63] "" Vector__XXX
 SG_ PitchLmtSt : 53|3@1+ (1,0) [0|7] "" Vector__XXX
 SG_ PitchAngle : 32|16@1+ (0.002,-64) [-64|64.51] "deg" Vector__XXX
 SG_ Exit_ReasonCode : 24|6@1+ (1,0) [0|63] "" Vector__XXX
 SG_ LmtSt : 21|3@1+ (1,0) [0|7] "" Vector__XXX
 SG_ Angle : 0|16@1+ (0.002,-64) [-64|64.51] "deg" Vector__XXX

BO_ 2364604670 SHRPC: 8 Vector__XXX
 SG_ PitchSensitivityCmd : 40|8@1+ (0.4,0) [0|100] "%" Vector__XXX
 SG_ PitchCmd : 24|16@1+ (0.002,-64) [-64|64.51] "deg" Vector__XXX
 SG_ SensitivityCmd : 16|8@1+ (0.4,0) [0|100] "%" Vector__XXX
 SG_ Cmd : 0|16@1+ (0.002,-64) [-64|64.51] "deg" Vector__XXX

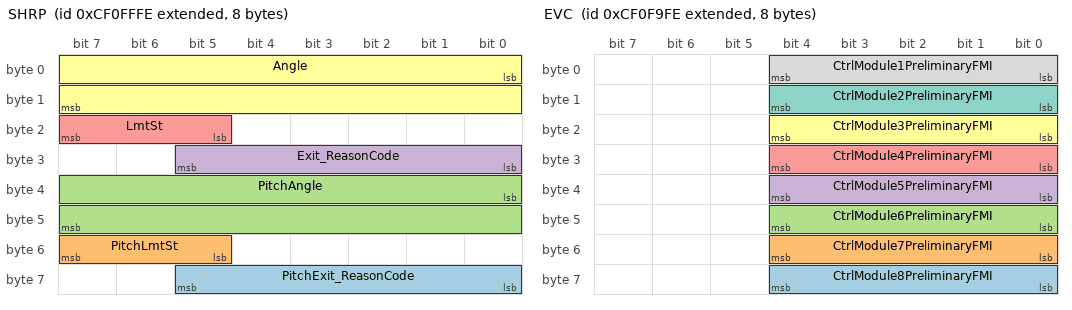
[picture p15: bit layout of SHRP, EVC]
BO_ 2364604414 SHRP: 8 Vector__XXX
 SG_ PitchExit_ReasonCode : 56|6@1+ (1,0) [0|63] "" Vector__XXX
 SG_ PitchLmtSt : 53|3@1+ (1,0) [0|7] "" Vector__XXX
 SG_ PitchAngle : 32|16@1+ (0.002,-64) [-64|64.51] "deg" Vector__XXX
 SG_ Exit_ReasonCode : 24|6@1+ (1,0) [0|63] "" Vector__XXX
 SG_ LmtSt : 21|3@1+ (1,0) [0|7] "" Vector__XXX
 SG_ Angle : 0|16@1+ (0.002,-64) [-64|64.51] "deg" Vector__XXX

BO_ 2364604158 A2SCRDSI4: 8 Vector__XXX
 SG_ DEFActualQuantityOfIntegrator : 0|16@1+ (0.001,0) [0|64.255] "g" Vector__XXX

BO_ 2364603902 A1SCRDSI4: 8 Vector__XXX
 SG_ DEFActualQuantityOfIntegrator : 0|16@1+ (0.001,0) [0|64.255] "g" Vector__XXX

BO_ 2364603646 A2SCRDSR3: 8 Vector__XXX
 SG_ DEFReqQuantityOfIntegrator : 0|16@1+ (0.001,0) [0|64.255] "g" Vector__XXX

BO_ 2364603390 A1SCRDSR3: 8 Vector__XXX
 SG_ DEFDoserVlv1Cmd : 16|16@1+ (0.0025,0) [0|100] "%" Vector__XXX
 SG_ DEFReqQuantityOfIntegrator : 0|16@1+ (0.001,0) [0|64.255] "g" Vector__XXX

BO_ 2364603134 ETC13: 8 Vector__XXX
 SG_ SAOfActiveOrPendingTransReqGear : 32|8@1+ (1,0) [0|253] "" Vector__XXX
 SG_ MaxReverseTransOSS : 16|16@1+ (0.125,0) [0|8031.875] "rpm" Vector__XXX
 SG_ MaxForwardTransOSS : 0|16@1+ (0.125,0) [0|8031.875] "rpm" Vector__XXX

BO_ 2364602878 EVC: 8 Vector__XXX
 SG_ CtrlModule8PreliminaryFMI : 56|5@1+ (1,0) [0|31] "" Vector__XXX
 SG_ CtrlModule7PreliminaryFMI : 48|5@1+ (1,0) [0|31] "" Vector__XXX
 SG_ CtrlModule6PreliminaryFMI : 40|5@1+ (1,0) [0|31] "" Vector__XXX
 SG_ CtrlModule5PreliminaryFMI : 32|5@1+ (1,0) [0|31] "" Vector__XXX
 SG_ CtrlModule4PreliminaryFMI : 24|5@1+ (1,0) [0|31] "" Vector__XXX
 SG_ CtrlModule3PreliminaryFMI : 16|5@1+ (1,0) [0|31] "" Vector__XXX
 SG_ CtrlModule2PreliminaryFMI : 8|5@1+ (1,0) [0|31] "" Vector__XXX
 SG_ CtrlModule1PreliminaryFMI : 0|5@1+ (1,0) [0|31] "" Vector__XXX

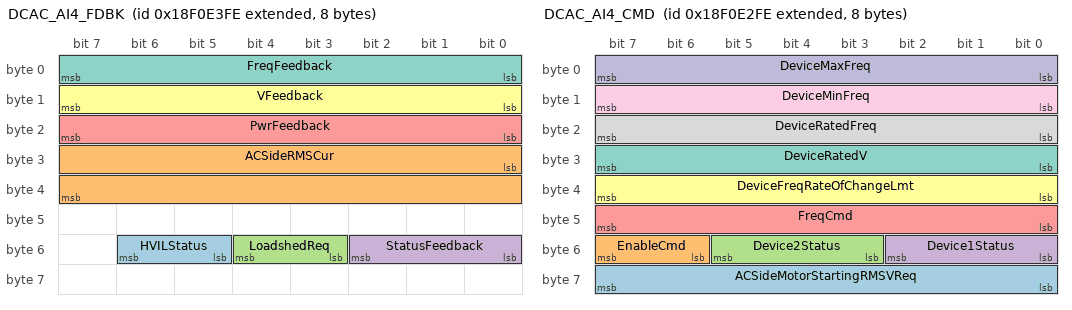
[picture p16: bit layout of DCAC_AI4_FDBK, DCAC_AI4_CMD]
BO_ 2565923838 DCAC_AI4_FDBK: 8 Vector__XXX
 SG_ HVILStatus : 53|2@1+ (1,0) [0|3] "" Vector__XXX
 SG_ ACSideRMSCur : 24|16@1+ (0.03125,0) [0|2007.96875] "Arms" Vector__XXX
 SG_ LoadshedReq : 51|2@1+ (1,0) [0|3] "" Vector__XXX
 SG_ StatusFeedback : 48|3@1+ (1,0) [0|7] "" Vector__XXX
 SG_ PwrFeedback : 16|8@1+ (0.1,0) [0|25] "kW" Vector__XXX
 SG_ VFeedback : 8|8@1+ (2,0) [0|500] "Vrms" Vector__XXX
 SG_ FreqFeedback : 0|8@1+ (1,0) [0|250] "Hz" Vector__XXX

BO_ 2565923582 DCAC_AI4_CMD: 8 Vector__XXX
 SG_ ACSideMotorStartingRMSVReq : 56|8@1+ (2,0) [0|500] "Vrms" Vector__XXX
 SG_ EnableCmd : 54|2@1+ (1,0) [0|3] "" Vector__XXX
 SG_ Device2Status : 51|3@1+ (1,0) [0|7] "" Vector__XXX
 SG_ Device1Status : 48|3@1+ (1,0) [0|7] "" Vector__XXX
 SG_ FreqCmd : 40|8@1+ (1,0) [0|250] "Hz" Vector__XXX
 SG_ DeviceFreqRateOfChangeLmt : 32|8@1+ (2,0) [0|500] "Hz/s" Vector__XXX
 SG_ DeviceRatedV : 24|8@1+ (2,0) [0|500] "Vrms" Vector__XXX
 SG_ DeviceRatedFreq : 16|8@1+ (1,0) [0|250] "Hz" Vector__XXX
 SG_ DeviceMinFreq : 8|8@1+ (1,0) [0|250] "Hz" Vector__XXX
 SG_ DeviceMaxFreq : 0|8@1+ (1,0) [0|250] "Hz" Vector__XXX

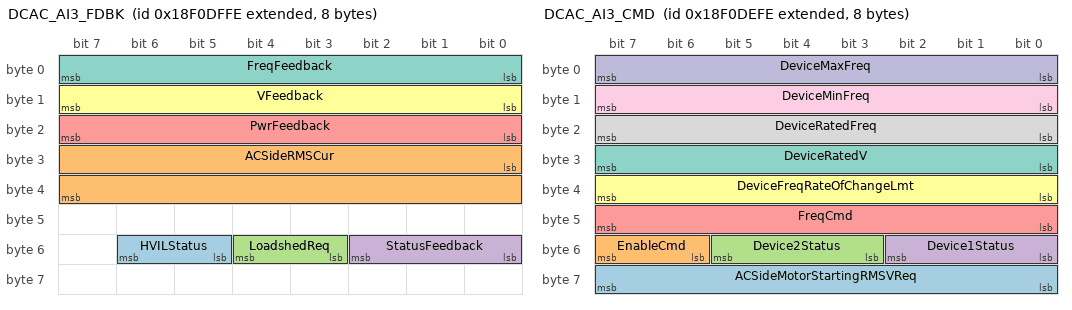
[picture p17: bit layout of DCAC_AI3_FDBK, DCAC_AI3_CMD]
BO_ 2565922814 DCAC_AI3_FDBK: 8 Vector__XXX
 SG_ HVILStatus : 53|2@1+ (1,0) [0|3] "" Vector__XXX
 SG_ ACSideRMSCur : 24|16@1+ (0.03125,0) [0|2007.96875] "Arms" Vector__XXX
 SG_ LoadshedReq : 51|2@1+ (1,0) [0|3] "" Vector__XXX
 SG_ StatusFeedback : 48|3@1+ (1,0) [0|7] "" Vector__XXX
 SG_ PwrFeedback : 16|8@1+ (0.1,0) [0|25] "kW" Vector__XXX
 SG_ VFeedback : 8|8@1+ (2,0) [0|500] "Vrms" Vector__XXX
 SG_ FreqFeedback : 0|8@1+ (1,0) [0|250] "Hz" Vector__XXX

BO_ 2565922558 DCAC_AI3_CMD: 8 Vector__XXX
 SG_ ACSideMotorStartingRMSVReq : 56|8@1+ (2,0) [0|500] "Vrms" Vector__XXX
 SG_ EnableCmd : 54|2@1+ (1,0) [0|3] "" Vector__XXX
 SG_ Device2Status : 51|3@1+ (1,0) [0|7] "" Vector__XXX
 SG_ Device1Status : 48|3@1+ (1,0) [0|7] "" Vector__XXX
 SG_ FreqCmd : 40|8@1+ (1,0) [0|250] "Hz" Vector__XXX
 SG_ DeviceFreqRateOfChangeLmt : 32|8@1+ (2,0) [0|500] "Hz/s" Vector__XXX
 SG_ DeviceRatedV : 24|8@1+ (2,0) [0|500] "Vrms" Vector__XXX
 SG_ DeviceRatedFreq : 16|8@1+ (1,0) [0|250] "Hz" Vector__XXX
 SG_ DeviceMinFreq : 8|8@1+ (1,0) [0|250] "Hz" Vector__XXX
 SG_ DeviceMaxFreq : 0|8@1+ (1,0) [0|250] "Hz" Vector__XXX

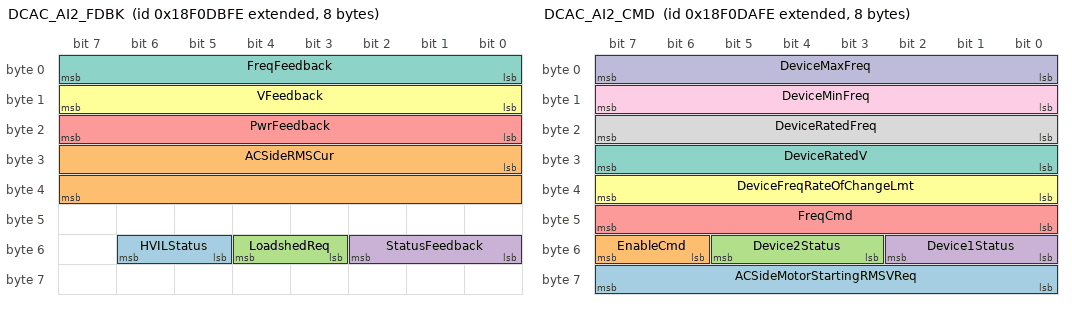
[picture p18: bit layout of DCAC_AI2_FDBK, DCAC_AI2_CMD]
BO_ 2565921790 DCAC_AI2_FDBK: 8 Vector__XXX
 SG_ HVILStatus : 53|2@1+ (1,0) [0|3] "" Vector__XXX
 SG_ ACSideRMSCur : 24|16@1+ (0.03125,0) [0|2007.96875] "Arms" Vector__XXX
 SG_ LoadshedReq : 51|2@1+ (1,0) [0|3] "" Vector__XXX
 SG_ StatusFeedback : 48|3@1+ (1,0) [0|7] "" Vector__XXX
 SG_ PwrFeedback : 16|8@1+ (0.1,0) [0|25] "kW" Vector__XXX
 SG_ VFeedback : 8|8@1+ (2,0) [0|500] "Vrms" Vector__XXX
 SG_ FreqFeedback : 0|8@1+ (1,0) [0|250] "Hz" Vector__XXX

BO_ 2565921534 DCAC_AI2_CMD: 8 Vector__XXX
 SG_ ACSideMotorStartingRMSVReq : 56|8@1+ (2,0) [0|500] "Vrms" Vector__XXX
 SG_ EnableCmd : 54|2@1+ (1,0) [0|3] "" Vector__XXX
 SG_ Device2Status : 51|3@1+ (1,0) [0|7] "" Vector__XXX
 SG_ Device1Status : 48|3@1+ (1,0) [0|7] "" Vector__XXX
 SG_ FreqCmd : 40|8@1+ (1,0) [0|250] "Hz" Vector__XXX
 SG_ DeviceFreqRateOfChangeLmt : 32|8@1+ (2,0) [0|500] "Hz/s" Vector__XXX
 SG_ DeviceRatedV : 24|8@1+ (2,0) [0|500] "Vrms" Vector__XXX
 SG_ DeviceRatedFreq : 16|8@1+ (1,0) [0|250] "Hz" Vector__XXX
 SG_ DeviceMinFreq : 8|8@1+ (1,0) [0|250] "Hz" Vector__XXX
 SG_ DeviceMaxFreq : 0|8@1+ (1,0) [0|250] "Hz" Vector__XXX

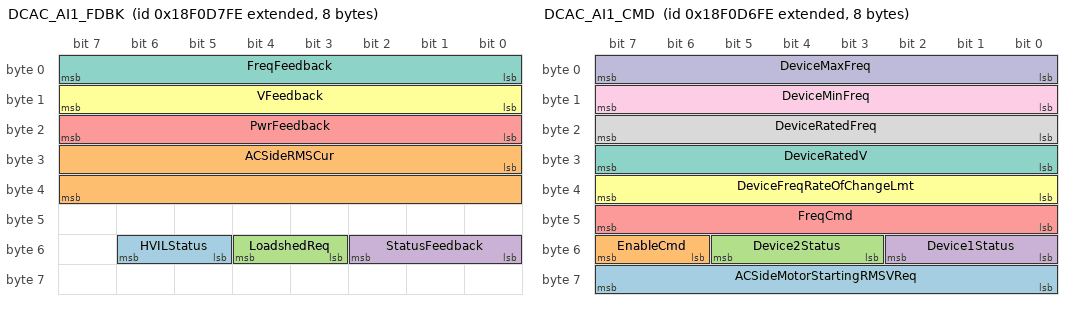
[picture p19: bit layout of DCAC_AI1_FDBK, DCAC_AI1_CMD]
BO_ 2565920766 DCAC_AI1_FDBK: 8 Vector__XXX
 SG_ HVILStatus : 53|2@1+ (1,0) [0|3] "" Vector__XXX
 SG_ ACSideRMSCur : 24|16@1+ (0.03125,0) [0|2007.96875] "Arms" Vector__XXX
 SG_ LoadshedReq : 51|2@1+ (1,0) [0|3] "" Vector__XXX
 SG_ StatusFeedback : 48|3@1+ (1,0) [0|7] "" Vector__XXX
 SG_ PwrFeedback : 16|8@1+ (0.1,0) [0|25] "kW" Vector__XXX
 SG_ VFeedback : 8|8@1+ (2,0) [0|500] "Vrms" Vector__XXX
 SG_ FreqFeedback : 0|8@1+ (1,0) [0|250] "Hz" Vector__XXX

BO_ 2565920510 DCAC_AI1_CMD: 8 Vector__XXX
 SG_ ACSideMotorStartingRMSVReq : 56|8@1+ (2,0) [0|500] "Vrms" Vector__XXX
 SG_ EnableCmd : 54|2@1+ (1,0) [0|3] "" Vector__XXX
 SG_ Device2Status : 51|3@1+ (1,0) [0|7] "" Vector__XXX
 SG_ Device1Status : 48|3@1+ (1,0) [0|7] "" Vector__XXX
 SG_ FreqCmd : 40|8@1+ (1,0) [0|250] "Hz" Vector__XXX
 SG_ DeviceFreqRateOfChangeLmt : 32|8@1+ (2,0) [0|500] "Hz/s" Vector__XXX
 SG_ DeviceRatedV : 24|8@1+ (2,0) [0|500] "Vrms" Vector__XXX
 SG_ DeviceRatedFreq : 16|8@1+ (1,0) [0|250] "Hz" Vector__XXX
 SG_ DeviceMinFreq : 8|8@1+ (1,0) [0|250] "Hz" Vector__XXX
 SG_ DeviceMaxFreq : 0|8@1+ (1,0) [0|250] "Hz" Vector__XXX

BO_ 2364580094 HVES1D7: 8 Vector__XXX
 SG_ MaxChargeVLmt : 48|16@1+ (0.05,0) [0|3212.75] "V" Vector__XXX
 SG_ ChargeEnergyCapacity : 24|24@1+ (0.001,0) [0|16449.535] "kWh" Vector__XXX
 SG_ DisEnergyCapacity : 0|24@1+ (0.001,0) [0|16449.535] "kWh" Vector__XXX

CM_ BO_ 2566647550 "Oil Debris Monitor Counts Non-Ferrous Bins 1 & 2
Reports the Oil Debris Monitor counts in non-ferrous bins 1 & 2 measured by one oil debris sensor within the Oil Debris Monitoring (ODM) system.
In oil debris monitoring, bins are count accumulators ...";
CM_ SG_ 2566647550 NFBin2Count "Total number of particles detected in Non-Ferrous bin 2. Bin sizes are application specific.";
CM_ SG_ 2566647550 NFBin1Count "Total number of particles detected in Non-Ferrous bin 1. Bin sizes are application specific.";
CM_ SG_ 2566647550 NFBins1And2IdNum "Identification number of the Oil Debris Monitoring (ODM) sensor being reported for Non-Ferrous bins 1 and 2.  Identification numbers are application specific.";
CM_ BO_ 2566647294 "Oil Debris Monitor Counts Ferrous Bins 5 & 6
Reports the Oil Debris Monitor counts in ferrous bins 5 & 6 measured by one oil debris sensor within the Oil Debris Monitoring (ODM) system.
In oil debris monitoring, bins are count accumulators for the ...";
CM_ SG_ 2566647294 FBin6Count "Total number of particles detected in Ferrous bin 6. Bin sizes are application specific.";
CM_ SG_ 2566647294 FBin5Count "Total number of particles detected in Ferrous bin 5. Bin sizes are application specific.";
CM_ SG_ 2566647294 FBins5And6IdNum "Identification number of the Oil Debris Monitoring (ODM) sensor being reported for Ferrous bins 5 and 6. Identification numbers are application specific.";
CM_ BO_ 2566647038 "Oil Debris Monitor Counts Ferrous Bins 3 & 4
Reports the Oil Debris Monitor counts in ferrous bins 3 & 4 measured by one oil debris sensor within the Oil Debris Monitoring (ODM) system.
In oil debris monitoring, bins are count accumulators for the ...";
CM_ SG_ 2566647038 FBin4Count "Total number of particles detected in Ferrous bin 4. Bin sizes are application specific.";
CM_ SG_ 2566647038 FBin3Count "Total number of particles detected in Ferrous bin 3. Bin sizes are application specific.";
CM_ SG_ 2566647038 FBins3And4IdNum "Identification number of the Oil Debris Monitoring (ODM) sensor being reported for Ferrous bins 3 and 4. Identification numbers are application specific.";
CM_ BO_ 2566646782 "Oil Debris Monitor Counts Ferrous Bins 1 & 2
Reports the Oil Debris Monitor counts in ferrous bins 1 & 2 measured by one oil debris sensor within the Oil Debris Monitoring (ODM) system.
In oil debris monitoring, bins are count accumulators for the ...";
CM_ SG_ 2566646782 FBin2Count "Total number of particles detected in Ferrous bin 2. Bin sizes are application specific.";
CM_ SG_ 2566646782 FBin1Count "Total number of particles detected in Ferrous bin 1. Bin sizes are application specific.";
CM_ SG_ 2566646782 FBins1And2IdNum "Identification number of the Oil Debris Monitoring (ODM) sensor being reported for Ferrous bins 1 and 2. Identification numbers are application specific.";
CM_ BO_ 2633755390 "Ethernet 1 Connection Information 1
Includes information helpful to facilitate connecting to the sending ECU via the first instance of an embedded Ethernet link.

As a minimum, the first 19 bytes are expected to be broadcast.";
CM_ SG_ 2633755390 MACAddressOctet6 "This value is the sixth of 6 octets in the ECU's assigned MAC address. The address is separated into 6 bytes, 1 per octet of the address. Byte 1 is the first octet of the address. Byte 2 is the second and so forth. If the MAC address is not ...";
CM_ SG_ 2633755390 MACAddressOctet5 "This value is the fifth of 6 octets in the ECU's assigned MAC address. The address is separated into 6 bytes, 1 per octet of the address. Byte 1 is the first octet of the address. Byte 2 is the second and so forth. If the MAC address is not ...";
CM_ SG_ 2633755390 MACAddressOctet4 "This value is the fourth of 6 octets in the ECU's assigned MAC address. The address is separated into 6 bytes, 1 per octet of the address. Byte 1 is the first octet of the address. Byte 2 is the second and so forth. If the MAC address is not ...";
CM_ SG_ 2633755390 MACAddressOctet3 "This value is the third of 6 octets in the ECU's assigned MAC address. The address is separated into 6 bytes, 1 per octet of the address. Byte 1 is the first octet of the address. Byte 2 is the second and so forth. If the MAC address is not ...";
CM_ SG_ 2633755390 MACAddressOctet2 "This value is the second of 6 octets in the ECU's assigned MAC address. The address is separated into 6 bytes, 1 per octet of the address. Byte 1 is the first octet of the address. Byte 2 is the second and so forth. If the MAC address is not ...";
CM_ SG_ 2633755390 MACAddressOctet1 "This value is the first of 6 octets in the ECU's assigned MAC address. The address is separated into 6 bytes, 1 per octet of the address. Byte 1 is the first octet of the address. Byte 2 is the second and so forth. If the MAC address is not ...";
CM_ SG_ 2633755390 DefaultGatewayOctet4 "This value is the fourth of 4 octets in the ECU's configured or assigned Default Gateway IP address.  The Default Gateway IP address is separated into 4 bytes, 1 per octet of the address Byte 1 is the first octet of the address Byte 2 is the second ...";
CM_ SG_ 2633755390 DefaultGatewayOctet3 "This value is the third of 4 octets in the ECU's configured or assigned Default Gateway IP address.  The Default Gateway IP address is separated into 4 bytes, 1 per octet of the address Byte 1 is the first octet of the address Byte 2 is the second ...";
CM_ SG_ 2633755390 DefaultGatewayOctet2 "This value is the second of 4 octets in the ECU's configured or assigned Default Gateway IP address.  The Default Gateway IP address is separated into 4 bytes, 1 per octet of the address Byte 1 is the first octet of the address Byte 2 is the second ...";
CM_ SG_ 2633755390 DefaultGatewayOctet1 "This value is the first of 4 octets in the ECU's configured or assigned Default Gateway IP address.  The Default Gateway IP address is separated into 4 bytes, 1 per octet of the address Byte 1 is the first octet of the address Byte 2 is the second ...";
CM_ SG_ 2633755390 SubnetMaskOctet4 "This value is the fourth of 4 octets in the ECU's configured Subnet mask. The subnet mask is separated into 4 bytes, 1 per octet of the mask. Byte 1 is the first octet of the mask. Byte 2 is the second and so forth. If the Subnet mask is not ...";
CM_ SG_ 2633755390 SubnetMaskOctet3 "This value is the third of 4 octets in the ECU's configured Subnet mask. The subnet mask is separated into 4 bytes, 1 per octet of the mask. Byte 1 is the first octet of the mask. Byte 2 is the second and so forth. If the Subnet mask is not ...";
CM_ SG_ 2633755390 SubnetMaskOctet2 "This value is the second of 4 octets in the ECU's configured Subnet mask. The subnet mask is separated into 4 bytes, 1 per octet of the mask. Byte 1 is the first octet of the mask. Byte 2 is the second and so forth. If the Subnet mask is not ...";
CM_ SG_ 2633755390 SubnetMaskOctet1 "This value is the first of 4 octets in the ECU's configured Subnet mask. The subnet mask is separated into 4 bytes, 1 per octet of the mask. Byte 1 is the first octet of the mask. Byte 2 is the second and so forth. If the Subnet mask is not ...";
CM_ SG_ 2633755390 IPv4AddressOctet4 "This value is the fourth of 4 octets in the ECU's assigned Internet Protocol (IP) address. The address is separated into 4 bytes, 1 per octet of the address. Byte 1 is the first octet of the address. Byte 2 is the second and so forth. If the IP ...";
CM_ SG_ 2633755390 IPv4AddressOctet3 "This value is the third of 4 octets in the ECU's assigned Internet Protocol (IP) address. The address is separated into 4 bytes, 1 per octet of the address. Byte 1 is the first octet of the address. Byte 2 is the second and so forth. If the IP ...";
CM_ SG_ 2633755390 IPv4AddressOctet2 "This value is the second of 4 octets in the ECU's assigned Internet Protocol (IP) address. The address is separated into 4 bytes, 1 per octet of the address. Byte 1 is the first octet of the address. Byte 2 is the second and so forth. If the IP ...";
CM_ SG_ 2633755390 IPv4AddressOctet1 "This value is the first of 4 octets in the ECU's assigned Internet Protocol (IP) address. The address is separated into 4 bytes, 1 per octet of the address. Byte 1 is the first octet of the address. Byte 2 is the second and so forth. If the IP ...";
CM_ SG_ 2633755390 LinkStatus "Ethernet Link Status. When there is no physical connection, the status shall report 00. 

00 - Ethernet Link Down
01 - Ethernet Link Up
10 - Error
11 - Not Supported";
CM_ SG_ 2633755390 DHCPStatus "DHCP Client Status. This parameter is intended to provide feedback on the status of obtaining an IP address. When no physical link is available and DHCP is enabled, an Error response is appropriate.
0000 - Not Configured (static IP)
0001 - ...";
CM_ BO_ 2633755134 "Ethernet 1 Connection Information 2
Provides the Host Name used by the sending ECU of the first instance of an embedded Ethernet link. This information can be used to aid locating the ECU on a network.";
CM_ SG_ 2633755134 HostName "The Host Name of the sending ECU for its embedded Ethernet port.  Host Names can be up to 63 characters in length.";
CM_ BO_ 2633754878 "Aftertreatment System Information 2
The state of the aftertreatment system.";
CM_ SG_ 2633754878 TotalDEFUsed "Total amount of DEF used by aftertreatment device 1 and aftertreatment device 2 over the lifetime of the system.

See SPNs 5963 and 5964 for individual device accumulation.";
CM_ BO_ 2633754622 "SCR Operator Inducement Information 5
Contains parameters that are related to SCR inducement.";
CM_ SG_ 2633754622 EmergOvrdTotalActivationTime "The total time duration the SCR Operator Inducement Override Mode (SPN 7342) has been active.

Note:  Euro Stage V states this timer can not be reset.";
CM_ SG_ 2633754622 AFT1SCRInHiTempTime "Indicates the time the aftertreatment 1 SCR intake temperature is above a manufacturer specified threshold. This is the temperature of engine combustion byproducts entering the SCR in exhaust bank 1. This will accumulate over the life of the product ...";
CM_ BO_ 2365318910 "High Voltage Energy Storage Fan Commands
Commands to 1 or more fans in an HVES pack or system.  See PGN 64485 for the corresponding feedback message.
This command may be used to control fans in (a) individual, stand-alone packs, (b) packs that are ...";
CM_ SG_ 2365318910 HVESFanInstance15 "Indicates the HVES Fan Instance that is being commanded.  Multiple instances can be controlled with the same command PGN by setting each unique instance parameter to 0x0.
0 - Command applied to this Fan Instance
1 - No Command applied to this Fan ...";
CM_ SG_ 2365318910 HVESFanInstance14 "Indicates the HVES Fan Instance that is being commanded.  Multiple instances can be controlled with the same command PGN by setting each unique instance parameter to 0x0.
0 - Command applied to this Fan Instance
1 - No Command applied to this Fan ...";
CM_ SG_ 2365318910 HVESFanInstance13 "Indicates the HVES Fan Instance that is being commanded.  Multiple instances can be controlled with the same command PGN by setting each unique instance parameter to 0x0.
0 - Command applied to this Fan Instance
1 - No Command applied to this Fan ...";
CM_ SG_ 2365318910 HVESFanInstance12 "Indicates the HVES Fan Instance that is being commanded.  Multiple instances can be controlled with the same command PGN by setting each unique instance parameter to 0x0.
0 - Command applied to this Fan Instance
1 - No Command applied to this Fan ...";
CM_ SG_ 2365318910 HVESFanInstance11 "Indicates the HVES Fan Instance that is being commanded.  Multiple instances can be controlled with the same command PGN by setting each unique instance parameter to 0x0.
0 - Command applied to this Fan Instance
1 - No Command applied to this Fan ...";
CM_ SG_ 2365318910 HVESFanInstance10 "Indicates the HVES Fan Instance that is being commanded.  Multiple instances can be controlled with the same command PGN by setting each unique instance parameter to 0x0.
0 - Command applied to this Fan Instance
1 - No Command applied to this Fan ...";
CM_ SG_ 2365318910 HVESFanInstance9 "Indicates the HVES Fan Instance that is being commanded.  Multiple instances can be controlled with the same command PGN by setting each unique instance parameter to 0x0.
0 - Command applied to this Fan Instance
1 - No Command applied to this Fan ...";
CM_ SG_ 2365318910 HVESFanInstance8 "Indicates the HVES Fan Instance that is being commanded.  Multiple instances can be controlled with the same command PGN by setting each unique instance parameter to 0x0.
0 - Command applied to this Fan Instance
1 - No Command applied to this Fan ...";
CM_ SG_ 2365318910 HVESFanInstance7 "Indicates the HVES Fan Instance that is being commanded.  Multiple instances can be controlled with the same command PGN by setting each unique instance parameter to 0x0.
0 - Command applied to this Fan Instance
1 - No Command applied to this Fan ...";
CM_ SG_ 2365318910 HVESFanInstance6 "Indicates the HVES Fan Instance that is being commanded.  Multiple instances can be controlled with the same command PGN by setting each unique instance parameter to 0x0.
0 - Command applied to this Fan Instance
1 - No Command applied to this Fan ...";
CM_ SG_ 2365318910 HVESFanInstance5 "Indicates the HVES Fan Instance that is being commanded.  Multiple instances can be controlled with the same command PGN by setting each unique instance parameter to 0x0.
0 - Command applied to this Fan Instance
1 - No Command applied to this Fan ...";
CM_ SG_ 2365318910 HVESFanInstance4 "Indicates the HVES Fan Instance that is being commanded.  Multiple instances can be controlled with the same command PGN by setting each unique instance parameter to 0x0.
0 - Command applied to this Fan Instance
1 - No Command applied to this Fan ...";
CM_ SG_ 2365318910 HVESFanInstance3 "Indicates the HVES Fan Instance that is being commanded.  Multiple instances can be controlled with the same command PGN by setting each unique instance parameter to 0x0.
0 - Command applied to this Fan Instance
1 - No Command applied to this Fan ...";
CM_ SG_ 2365318910 HVESFanInstance2 "Indicates the HVES Fan Instance that is being commanded.  Multiple instances can be controlled with the same command PGN by setting each unique instance parameter to 0x0.
0 - Command applied to this Fan Instance
1 - No Command applied to this Fan ...";
CM_ SG_ 2365318910 HVESFanInstance1 "Indicates the HVES Fan Instance that is being commanded.  Multiple instances can be controlled with the same command PGN by setting each unique instance parameter to 0x0.
0 - Command applied to this Fan Instance
1 - No Command applied to this Fan ...";
CM_ SG_ 2365318910 HVESFanPercentSpdCmd "Speed command to this HVES fan in percentage of maximum speed.
Note: Both Speed Command (SPN 8386) and Percent Speed Command cannot be used at the same time.  Always set the unused speed command to Not Available.  If both commands are set to Not ...";
CM_ SG_ 2365318910 HVESFanSpdCmd "Speed command to this HVES fan.
Note: Both Speed Command and Percent Speed Command (SPN 8387) cannot be used at the same time.  Always set the unused speed command to Not Available.  If both commands are set to Not Available, a preprogrammed ...";
CM_ SG_ 2365318910 HVESFanPwrHold "Command to allow this HVES fan to remain alive independently of the electrical enable input to the fan.  For example, this could allow continued device operation after the keyswitch has turned off.
00 - Power Hold Disabled
01 - Power Hold Enabled
 ...";
CM_ SG_ 2365318910 HVESFanEnableCmd "Enable and direction command to this HVES fan.

00 - Fan Off
01 - Fan On Normal/Default Direction
10 - Fan On Reverse Direction
11 - Don't Care/Take no action";
CM_ BO_ 2566645246 "High Voltage Energy Storage Fan Status
The status of HVES fan(s).   See PGN 64486 for the corresponding command message.
If a single controller application broadcasts multiple instances of this message, a 10ms spacing between broadcasts of this ...";
CM_ SG_ 2566645246 HVESFanInstance "Indicates the instance of the HVES fan that is providing status in systems controlled by a master ECU.
0000 - Instance 1
0001 - Instance 2
0010 - Instance 3
0011 - Instance 4
0100 - Instance 5
0101 - Instance 6
0110 - Instance 7
0111 - ...";
CM_ SG_ 2566645246 HVESFanOperatingStatus "Indicates the operating status of this HVES fan.  This parameter is used to inform other devices that this system or component is no longer performing to its operational capacity and that reduced, or no flow of the medium (e.g. coolant, oil, air, ...";
CM_ SG_ 2566645246 HVESFanServiceInd "Indicates that service is required for this HVES fan.  An active indication may convey a need for component replacement or periodic service.  The HVES Fan Status Reason Code (SPN 8404) may provide additional detail as to the nature of the system ...";
CM_ SG_ 2566645246 HVESFanPwr "Calculated electrical power consumed by this HVES fan.";
CM_ SG_ 2566645246 HVESFanMediumTemp "A temperature measured and reported by the device.  It may be used for direct or remote (e.g. by another controller) control of the pump.  For example, this may be the temperature of the fluid flowing through the pump, or some other temperature ...";
CM_ SG_ 2566645246 HVESFanSpd "Speed of this HVES fan.";
CM_ SG_ 2566645246 HVESFanCmdStatus "Indicates the source of the speed command to this HVES fan.

00 - Internal Command
01 - External Command
10 - Default Command
11 - Not Available";
CM_ SG_ 2566645246 HVESFanStatusReasonCode "Provides the reason code describing the unique failure of this HVES fan.  If a detailed reason code is not used by the supporting application, or this reason code is Not Available, the HVES Fan Service Indicator (SPN 8409) and HVES fan Operating ...";
CM_ SG_ 2566645246 HVESFanEnableStatus "Enable and direction status of this HVES fan.

00 - Fan Off
01 - Fan On - Normal, Forward, or Default Direction
10 - Fan On - Reverse Direction
11 - Not available";
CM_ BO_ 2566644990 "Fuel Information 7 (Gaseous)
Gaseous fuel information 7";
CM_ SG_ 2566644990 StorageCompartment3Temp2 "The ambient temperature as measured by the second temperature sensor in the third fuel storage compartment. Note that this is not the temperature of the fuel in the fuel tank.";
CM_ SG_ 2566644990 StorageCompartment3Temp1 "The ambient temperature in the third fuel storage compartment.  If there is more than 1 sensor, then this is the first sensor. Note that this is not the temperature of the fuel in the fuel tank.";
CM_ SG_ 2566644990 StorageCompartment2Temp2 "The ambient temperature as measured by the second temperature sensor in the second fuel storage compartment. Note that this is not the temperature of the fuel in the fuel tank.";
CM_ SG_ 2566644990 StorageCompartment2Temp1 "The ambient temperature in the second fuel storage compartment.  If there is more than 1 sensor, then this is the first sensor. Note that this is not the temperature of the fuel in the fuel tank.";
CM_ SG_ 2566644990 StorageCompartment1Temp2 "The ambient temperature as measured by the second temperature sensor in the first fuel storage compartment. Note that this is not the temperature of the fuel in the fuel tank.";
CM_ SG_ 2566644990 StorageCompartment1Temp1 "The ambient temperature in the first fuel storage compartment.  If there is more than 1 sensor, then this is the first sensor. Note that this is not the temperature of the fuel in the fuel tank.";
CM_ SG_ 2566644990 FrontFuelRecpCoverStatus "Indicates if the cover for the fuel receptacle at the front of the vehicle is attached or detached.

00 - Receptacle cover is detached
01 - Receptacle cover is attached
10 - Error
11 - Not available";
CM_ SG_ 2566644990 PsgrSideFuelRecp2CoverStatus "Indicates if the cover for the second fuel receptacle on the passenger side is attached or detached.

00 - Receptacle cover is detached
01 - Receptacle cover is attached
10 - Error
11 - Not available";
CM_ SG_ 2566644990 PsgrSideFuelRecp1CoverStatus "Indicates if the cover for the first fuel receptacle on the passenger side is attached or detached.

00 - Receptacle cover is detached
01 - Receptacle cover is attached
10 - Error
11 - Not available";
CM_ SG_ 2566644990 DriverSideFuelRecp2CoverStatus "Indicates if the cover for the second fuel receptacle on the driver side is attached or detached.

00 - Receptacle cover is detached
01 - Receptacle cover is attached
10 - Error
11 - Not available";
CM_ SG_ 2566644990 DriverSideFuelRecp1CoverStatus "Indicates if the cover for the first fuel receptacle on the driver side is attached or detached.

00 - Receptacle cover is detached
01 - Receptacle cover is attached
10 - Error
11 - Not available";
CM_ BO_ 2633753598 "Alternator Temperature 2
Temperature of the alternator windings";
CM_ SG_ 2633753598 ACAirOutTemp "Temperature of air after it exits from the air cooler in an alternator.";
CM_ SG_ 2633753598 ACAirInTemp "Temperature of air entering the air cooler in an alternator";
CM_ SG_ 2633753598 EngAltWinding12Temp "Temperature of this winding inside the alternator.";
CM_ SG_ 2633753598 EngAltWinding11Temp "Temperature of this winding inside the alternator.";
CM_ SG_ 2633753598 EngAltWinding10Temp "Temperature of this winding inside the alternator.";
CM_ SG_ 2633753598 EngAltWinding9Temp "Temperature of this winding inside the alternator.";
CM_ SG_ 2633753598 EngAltWinding8Temp "Temperature of this winding inside the alternator.";
CM_ SG_ 2633753598 EngAltWinding7Temp "Temperature of this winding inside the alternator.";
CM_ BO_ 2633753342 "Diode Temperature 1
Temperature of the diodes in a power rectifier.";
CM_ SG_ 2633753342 PwrRectifierDiode8Temp "Temperature of this diode used in power rectifier.";
CM_ SG_ 2633753342 PwrRectifierDiode7Temp "Temperature of this diode used in power rectifier.";
CM_ SG_ 2633753342 PwrRectifierDiode6Temp "Temperature of this diode used in power rectifier.";
CM_ SG_ 2633753342 PwrRectifierDiode5Temp "Temperature of this diode used in power rectifier.";
CM_ SG_ 2633753342 PwrRectifierDiode4Temp "Temperature of this diode used in power rectifier.";
CM_ SG_ 2633753342 PwrRectifierDiode3Temp "Temperature of this diode used in power rectifier.";
CM_ SG_ 2633753342 PwrRectifierDiode2Temp "Temperature of this diode used in power rectifier.";
CM_ SG_ 2633753342 PwrRectifierDiode1Temp "Temperature of this diode used in power rectifier.";
CM_ BO_ 2633753086 "Diode Temperature 2
Temperature of the diodes in a power rectifier.";
CM_ SG_ 2633753086 PwrRectifierDiode12Temp "Temperature of this diode used in power rectifier.";
CM_ SG_ 2633753086 PwrRectifierDiode11Temp "Temperature of this diode used in power rectifier.";
CM_ SG_ 2633753086 PwrRectifierDiode10Temp "Temperature of this diode used in power rectifier.";
CM_ SG_ 2633753086 PwrRectifierDiode9Temp "Temperature of this diode used in power rectifier.";
CM_ BO_ 2633752830 "Aftercooler and Oil Cooler Fluids 1
Temperature and pressures for the aftercooler and oil cooler.";
CM_ SG_ 2633752830 AltAftercoolerCPOutPress "Pressure of liquid at the aftercooler pump outlet";
CM_ SG_ 2633752830 AltAftercoolerCoolantOutTemp "Temperature of liquid at the aftercooler outlet.";
CM_ SG_ 2633752830 AltAftercoolerCPOutTemp "Temperature of liquid at the aftercooler coolant pump outlet.";
CM_ SG_ 2633752830 EngOilCoolerCoolantOutTemp "Temperature of liquid after it exits the engine oil cooler.";
CM_ SG_ 2633752830 AltOilCoolerCoolantOutTemp "Temperature of liquid after it exits the oil cooler of an alternator.";
CM_ SG_ 2633752830 AltOilCoolerCoolantInTemp "Temperature of liquid as it enters the oil cooler of an alternator.";
CM_ SG_ 2633752830 AltOilCoolerOilOutTemp "Temperature of lubricant after it exits the oil cooler of an alternator.";
CM_ SG_ 2633752830 AltOilCoolerOilInTemp "Temperature of lubricant as it enters the oil cooler of an alternator.";
CM_ BO_ 2566643710 "Intake/Exhaust Conditions 3
Intake/Exhaust Conditions 3 is a second PGN conveying this type of engine information. Also see PGNs 64976 and 65270.";
CM_ SG_ 2566643710 EngMixer2InPress "The pressure at the intake of the second air and fuel mixer.";
CM_ SG_ 2566643710 EngMixer1InPress "The pressure at the intake of the air and fuel mixer.";
CM_ BO_ 2566643454 "Engine Temperature 6
Engine related parameters";
CM_ SG_ 2566643454 InCoolantTemp "Temperature of the coolant at the intake of the engine block.";
CM_ SG_ 2566643454 ChargeACOutCoolantTemp "Temperature of the fluid in the low temperature circuit measured at the fluid outlet of the charge air cooler.";
CM_ SG_ 2566643454 ChargeACInCoolantTemp "Temperature of the fluid in the low temperature circuit measured at the fluid intake of the charge air cooler.";
CM_ BO_ 2566643198 "Door Control 3
Used for door information.";
CM_ SG_ 2566643198 EnableStatusOfDoor20 "Enable status of bus door 20.  Enabled means the bus doors are able to be automatically opened or closed.

00 - Door disabled
01 - Door enabled
10 - Error
11 - Not available";
CM_ SG_ 2566643198 OpenStatusOfDoor20 "Open status of bus door 20

00 - Door closed
01 - Door opened
10 - Error
11 - Not available";
CM_ SG_ 2566643198 LockStatusOfDoor20 "Lock status of bus door 20

00 - Unlocked
01 - Locked
10 - Error
11 - Not available";
CM_ SG_ 2566643198 EnableStatusOfDoor19 "Enable status of bus door 19.  Enabled means the bus doors are able to be automatically opened or closed.

00 - Door disabled
01 - Door enabled
10 - Error
11 - Not available";
CM_ SG_ 2566643198 OpenStatusOfDoor19 "Open status of bus door 19

00 - Door closed
01 - Door opened
10 - Error
11 - Not available";
CM_ SG_ 2566643198 LockStatusOfDoor19 "Lock status of bus door 19

00 - Unlocked
01 - Locked
10 - Error
11 - Not available";
CM_ SG_ 2566643198 EnableStatusOfDoor18 "Enable status of bus door 18.  Enabled means the bus doors are able to be automatically opened or closed.

00 - Door disabled
01 - Door enabled
10 - Error
11 - Not available";
CM_ SG_ 2566643198 OpenStatusOfDoor18 "Open status of bus door 18

00 - Door closed
01 - Door opened
10 - Error
11 - Not available";
CM_ SG_ 2566643198 LockStatusOfDoor18 "Lock status of bus door 18

00 - Unlocked
01 - Locked
10 - Error
11 - Not available";
CM_ SG_ 2566643198 EnableStatusOfDoor17 "Enable status of bus door 17.  Enabled means the bus doors are able to be automatically opened or closed.

00 - Door disabled
01 - Door enabled
10 - Error
11 - Not available";
CM_ SG_ 2566643198 OpenStatusOfDoor17 "Open status of bus door 17

00 - Door closed
01 - Door opened
10 - Error
11 - Not available";
CM_ SG_ 2566643198 LockStatusOfDoor17 "Lock status of bus door 17

00 - Unlocked
01 - Locked
10 - Error
11 - Not available";
CM_ SG_ 2566643198 EnableStatusOfDoor16 "Enable status of bus door 16.  Enabled means the bus doors are able to be automatically opened or closed.

00 - Door disabled
01 - Door enabled
10 - Error
11 - Not available";
CM_ SG_ 2566643198 OpenStatusOfDoor16 "Open status of bus door 16

00 - Door closed
01 - Door opened
10 - Error
11 - Not available";
CM_ SG_ 2566643198 LockStatusOfDoor16 "Lock status of bus door 16

00 - Unlocked
01 - Locked
10 - Error
11 - Not available";
CM_ SG_ 2566643198 EnableStatusOfDoor15 "Enable status of bus door 15.  Enabled means the bus doors are able to be automatically opened or closed.

00 - Door disabled
01 - Door enabled
10 - Error
11 - Not available";
CM_ SG_ 2566643198 OpenStatusOfDoor15 "Open status of bus door 15

00 - Door closed
01 - Door opened
10 - Error
11 - Not available";
CM_ SG_ 2566643198 LockStatusOfDoor15 "Lock status of bus door 15

00 - Unlocked
01 - Locked
10 - Error
11 - Not available";
CM_ SG_ 2566643198 EnableStatusOfDoor14 "Enable status of bus door 14.  Enabled means the bus doors are able to be automatically opened or closed.

00 - Door disabled
01 - Door enabled
10 - Error
11 - Not available";
CM_ SG_ 2566643198 OpenStatusOfDoor14 "Open status of bus door 14

00 - Door closed
01 - Door opened
10 - Error
11 - Not available";
CM_ SG_ 2566643198 LockStatusOfDoor14 "Lock status of bus door 14

00 - Unlocked
01 - Locked
10 - Error
11 - Not available";
CM_ SG_ 2566643198 EnableStatusOfDoor13 "Enable status of bus door 13.  Enabled means the bus doors are able to be automatically opened or closed.

00 - Door disabled
01 - Door enabled
10 - Error
11 - Not available";
CM_ SG_ 2566643198 OpenStatusOfDoor13 "Open status of bus door 13

00 - Door closed
01 - Door opened
10 - Error
11 - Not available";
CM_ SG_ 2566643198 LockStatusOfDoor13 "Lock status of bus door 13

00 - Unlocked
01 - Locked
10 - Error
11 - Not available";
CM_ SG_ 2566643198 EnableStatusOfDoor12 "Enable status of bus door 12.  Enabled means the bus doors are able to be automatically opened or closed.

00 - Door disabled
01 - Door enabled
10 - Error
11 - Not available";
CM_ SG_ 2566643198 OpenStatusOfDoor12 "Open status of bus door 12

00 - Door closed
01 - Door opened
10 - Error
11 - Not available";
CM_ SG_ 2566643198 LockStatusOfDoor12 "Lock status of bus door 12


00 - Unlocked
01 - Locked
10 - Error
11 - Not available";
CM_ SG_ 2566643198 EnableStatusOfDoor11 "Enable status of bus door 11.  Enabled means the bus doors are able to be automatically opened or closed.

00 - Door disabled
01 - Door enabled
10 - Error
11 - Not available";
CM_ SG_ 2566643198 OpenStatusOfDoor11 "Open status of bus door 11

00 - Door closed
01 - Door opened
10 - Error
11 - Not available";
CM_ SG_ 2566643198 LockStatusOfDoor11 "Lock status of bus door 11

00 - Unlocked 
01 - Locked
10 - Error
11 - Not available";
CM_ BO_ 2566642942 "Door Control 4
Used for door information.";
CM_ SG_ 2566642942 EnableStatusOfDoor30 "Enable status of bus door 30.  Enabled means the bus doors are able to be automatically opened or closed.

00 - Door disabled
01 - Door enabled
10 - Error
11 - Not available";
CM_ SG_ 2566642942 OpenStatusOfDoor30 "Open status of bus door 30

00 - Door closed
01 - Door opened
10 - Error
11 - Not available";
CM_ SG_ 2566642942 LockStatusOfDoor30 "Lock status of bus door 30

00 - Unlocked
01 - Locked
10 - Error
11 - Not available";
CM_ SG_ 2566642942 EnableStatusOfDoor29 "Enable status of bus door 29.  Enabled means the bus doors are able to be automatically opened or closed.

00 - Door disabled
01 - Door enabled
10 - Error
11 - Not available";
CM_ SG_ 2566642942 OpenStatusOfDoor29 "Open status of bus door 29

00 - Door closed
01 - Door opened
10 - Error
11 - Not available";
CM_ SG_ 2566642942 LockStatusOfDoor29 "Lock status of bus door 29

00 - Unlocked
01 - Locked
10 - Error
11 - Not available";
CM_ SG_ 2566642942 EnableStatusOfDoor28 "Enable status of bus door 28.  Enabled means the bus doors are able to be automatically opened or closed.

00 - Door disabled
01 - Door enabled
10 - Error
11 - Not available";
CM_ SG_ 2566642942 OpenStatusOfDoor28 "Open status of bus door 28

00 - Door closed
01 - Door opened
10 - Error
11 - Not available";
CM_ SG_ 2566642942 LockStatusOfDoor28 "Lock status of bus door 28

00 - Unlocked
01 - Locked
10 - Error
11 - Not available";
CM_ SG_ 2566642942 EnableStatusOfDoor27 "Enable status of bus door 27.  Enabled means the bus doors are able to be automatically opened or closed.

00 - Door disabled
01 - Door enabled
10 - Error
11 - Not available";
CM_ SG_ 2566642942 OpenStatusOfDoor27 "Open status of bus door 27

00 - Door closed
01 - Door opened
10 - Error
11 - Not available";
CM_ SG_ 2566642942 LockStatusOfDoor27 "Lock status of bus door 27

00 - Unlocked
01 - Locked
10 - Error
11 - Not available";
CM_ SG_ 2566642942 EnableStatusOfDoor26 "Enable status of bus door 26.  Enabled means the bus doors are able to be automatically opened or closed.

00 - Door disabled
01 - Door enabled
10 - Error
11 - Not available";
CM_ SG_ 2566642942 OpenStatusOfDoor26 "Open status of bus door 26

00 - Door closed
01 - Door opened
10 - Error
11 - Not available";
CM_ SG_ 2566642942 LockStatusOfDoor26 "Lock status of bus door 26

00 - Unlocked
01 - Locked
10 - Error
11 - Not available";
CM_ SG_ 2566642942 EnableStatusOfDoor25 "Enable status of bus door 25.  Enabled means the bus doors are able to be automatically opened or closed.

00 - Door disabled
01 - Door enabled
10 - Error
11 - Not available";
CM_ SG_ 2566642942 OpenStatusOfDoor25 "Open status of bus door 25

00 - Door closed
01 - Door opened
10 - Error
11 - Not available";
CM_ SG_ 2566642942 LockStatusOfDoor25 "Lock status of bus door 25

00 - Unlocked
01 - Locked
10 - Error
11 - Not available";
CM_ SG_ 2566642942 EnableStatusOfDoor24 "Enable status of bus door 24.  Enabled means the bus doors are able to be automatically opened or closed.

00 - Door disabled
01 - Door enabled
10 - Error
11 - Not available";
CM_ SG_ 2566642942 OpenStatusOfDoor24 "Open status of bus door 24

00 - Door closed
01 - Door opened
10 - Error
11 - Not available";
CM_ SG_ 2566642942 LockStatusOfDoor24 "Lock status of bus door 24

00 - Unlocked
01 - Locked
10 - Error
11 - Not available";
CM_ SG_ 2566642942 EnableStatusOfDoor23 "Enable status of bus door 23.  Enabled means the bus doors are able to be automatically opened or closed.

00 - Door disabled
01 - Door enabled
10 - Error
11 - Not available";
CM_ SG_ 2566642942 OpenStatusOfDoor23 "Open status of bus door 23

00 - Door closed
01 - Door opened
10 - Error
11 - Not available";
CM_ SG_ 2566642942 LockStatusOfDoor23 "Lock status of bus door 23

00 - Unlocked
01 - Locked
10 - Error
11 - Not available";
CM_ SG_ 2566642942 EnableStatusOfDoor22 "Enable status of bus door 22.  Enabled means the bus doors are able to be automatically opened or closed.

00 - Door disabled
01 - Door enabled
10 - Error
11 - Not available";
CM_ SG_ 2566642942 OpenStatusOfDoor22 "Open status of bus door 22

00 - Door closed
01 - Door opened
10 - Error
11 - Not available";
CM_ SG_ 2566642942 LockStatusOfDoor22 "Lock status of bus door 22

00 - Unlocked
01 - Locked
10 - Error
11 - Not available";
CM_ SG_ 2566642942 EnableStatusOfDoor21 "Enable status of bus door 21.  Enabled means the bus doors are able to be automatically opened or closed.

00 - Door disabled
01 - Door enabled
10 - Error
11 - Not available";
CM_ SG_ 2566642942 OpenStatusOfDoor21 "Open status of bus door 21

00 - Door closed
01 - Door opened
10 - Error
11 - Not available";
CM_ SG_ 2566642942 LockStatusOfDoor21 "Lock status of bus door 21

00 - Unlocked
01 - Locked
10 - Error
11 - Not available";
CM_ BO_ 2365315838 "DC/DC Converter 1 High Side Limits
Sets the HVES or High Voltage system limits for the transfer of energy between the high voltage system (i.e. high side) and the SLI battery or low voltage system (i.e. low side) using a DC/DC converter.
One ...";
CM_ SG_ 2365315838 HiSideCurMaxLmt "The maximum allowed high side current requested by a separate device.   Under normal conditions this requested limit would be reflected in SPN 8826.";
CM_ SG_ 2365315838 HiSideVMaxLmt "The maximum allowed high side voltage requested by a separate device.   Under normal conditions this requested limit would be reflected in SPN 8825.";
CM_ SG_ 2365315838 HiSideVMinLmt "The minimum allowed high side voltage requested by a separate device.   Under normal conditions this requested limit would be reflected in SPN 8824.";
CM_ BO_ 2365315582 "DC/DC Converter 1 Low Side Limits
Sets the SLI or Low Voltage system limits for the transfer of energy between the HVES or high voltage system (i.e. high side) and the SLI battery or low voltage system (i.e. low side) in a DC/DC Converter.";
CM_ SG_ 2365315582 LowSideCurMaxLmt "The maximum allowed low side current requested by a separate device.   Under normal conditions this requested limit would be reflected in SPN 8829.";
CM_ SG_ 2365315582 LowSideVMaxLmt "The maximum allowed low side voltage requested by a separate device.   Under normal conditions this requested limit would be reflected in SPN 8828.";
CM_ SG_ 2365315582 LowSideVMinLmt "The minimum allowed low side voltage requested by a separate device.   Under normal conditions this requested limit would be reflected in SPN 8827.";
CM_ BO_ 2365315326 "DC/DC Converter 1 Temperatures
DC/DC Converter measured temperature data.

One intended use of this message is for a conventional engine mounted alternator replacement.";
CM_ SG_ 2365315326 OneCoolantOutTemp "Parameter indicating the temperature of the DC/DC Converter Coolant measured at the output of the converter";
CM_ SG_ 2365315326 OneCoolantInTemp "Parameter indicating the temperature of the DC/DC Converter Coolant measured at the input of the converter";
CM_ SG_ 2365315326 PwrETemp "Parameter indicating the temperature of the DC/DC Converter power electronics components (e.g, switch or heatsink).";
CM_ SG_ 2365315326 ElectronicFilterTemp "Parameter indicating the temperature of the electronic components that make up the DC/DC Converter filter.";
CM_ SG_ 2365315326 Temp "Parameter indicating the temperature of the DC/DC Converter (e.g, controller, circuit board, enclosure).";
CM_ BO_ 2633750526 "Configurable Transmit PGNs Status
PGN 28928 and PGN 64471 are used to manage and report messages that are transmitted by a Configurable ECU. PGN 64471 is the response to PGN 28928. This message includes the PGNs and their transmit status that can ...";
CM_ SG_ 2633750526 PGNModifiedStatus "Indicates if able to honor the transmit status change request issued in the triggering PGN 28928 message for the associated PGN on the port identified in SPN 8595.  This parameter is reported as '0' only if the received PGN 28928 requested a ...";
CM_ SG_ 2633750526 PGNPendingChangeStatus "Indicates if there is a pending change to the transmit capability of the associated PGN on the port identified in SPN 8599.
00 - Pending transmit change to disable for the port identified in SPN 8599.
01 - Pending transmit change to enable for the ...";
CM_ SG_ 2633750526 PGNCurTransmitStatus "Indicates the current transmit status of the associated PGN on the port identified in SPN 8599.
00 - PGN is currently configured for transmit on the port identified in SPN 8599.
01 - PGN is not currently configured for transmit on the port ...";
CM_ SG_ 2633750526 PGN "Identifies the PGN for which the associated SPNs 8603, 8604, & 8605 apply.";
CM_ SG_ 2633750526 PortCmdStatus "Indicates the overall success in performing the commanded transaction in PGN 28928.
000 - Positive Acknowledgment - PGN 28928 commanded transaction was processed without issue.
001 - 	Negative Acknowledgment - PGN 28928 command was received but ...";
CM_ SG_ 2633750526 PortPendingChangesStatus "Indicates if there are any pending transmit changes for the specified ECU communication port.
0 - No pending changes to the transmit status for any supported PGNs for the port identified in SPN 8599.
1 - Transmit changes are pending for one or ...";
CM_ SG_ 2633750526 Port "Identifies the ECU communications port of the responding Configurable ECU that is in context for this instance of PGN 64471.  If changes are accepted by the Configurable ECU, then this is the port affected.  The identification of each ECU ...";
CM_ BO_ 2566641406 "Electronic Engine Controller 21
Engine exhaust related parameters";
CM_ SG_ 2566641406 ExhManifoldPress2 "Absolute pressure of the exhaust gasses as measured at the engine exhaust manifold, location 2.";
CM_ SG_ 2566641406 ExhManifoldPress1 "Absolute pressure of the exhaust gasses as measured at the engine exhaust manifold, location 1.";
CM_ BO_ 2566641150 "Aftercooler and Oil Cooler Fluids 2
Temperature and pressures for the aftercooler and oil cooler.";
CM_ SG_ 2566641150 EngOilCoolerInTemp "Temperature of lube oil at engine cooler intake.";
CM_ SG_ 2566641150 EngOilCoolerDisPumpPress "Pressure of the lube oil at engine oil cooler discharge pump.";
CM_ SG_ 2566641150 AltOilCoolerDisPumpPress "Pressure of the lube oil at the alternator oil cooler discharge pump.";
CM_ SG_ 2566641150 AltBearingHeaderInPress "Pressure of the lube oil at the intake of alternator bearing header.";
CM_ BO_ 2633749758 "Well Stimulation Pump System Configuration
Communicates the configuration parameters of a well stimulation pump used in oil and gas drilling applications.
A well stimulation pump is a pump used to flow hydrocarbons from the drainage area into the ...";
CM_ SG_ 2633749758 RatedSpd "The rated speed of the well stimulation pump.";
CM_ SG_ 2633749758 GearRatio "Actual ratio of input shaft speed to output shaft speed.";
CM_ SG_ 2633749758 StrokeLength "The stroke length of the plunger in a well stimulation pump.";
CM_ SG_ 2633749758 PlungerDiameter "The diameter of the well stimulation pump plungers";
CM_ BO_ 2633749502 "Well Stimulation Pump System Lifetime Totals
Communicates the configuration parameters of a well stimulation pump used in oil and gas drilling applications.
A well stimulation pump is a pump used to flow hydrocarbons from the drainage area into ...";
CM_ SG_ 2633749502 CycleCount "The total number of cycles on the well stimulation pump. A cycle is defined as a working stage from start to finish.";
CM_ SG_ 2633749502 WorkingHours "The accumulated amount of time the Well Stimulation Pump has spent working.";
CM_ SG_ 2633749502 PwrEndWorkingHours "The accumulated time of operation of the power end of the pump while under operating conditions.";
CM_ SG_ 2633749502 FluidEndWorkingHours "The accumulated time of operation of the fluid end of the pump while under operating conditions.";
CM_ BO_ 2566640382 "Pump Oil Message
Pump oil related parameters.

.";
CM_ SG_ 2566640382 WellStimPumpOilTemp "Temperature of the well stimulation pump lubricant.";
CM_ SG_ 2566640382 WellStimPumpOilRelDielectricity "Well stimulation pump oil relative dielectricity used to describe the well stimulation pump oil quality.";
CM_ SG_ 2566640382 WellStimPumpOilDensity "Density of the well stimulation pump oil.";
CM_ SG_ 2566640382 WellStimPumpOilViscosity "Dynamic viscosity of the well stimulation pump oil.";
CM_ BO_ 2431719166 "Well Stimulation Pump System 3
Communicates operating parameters of a well stimulation pump used in oil and gas drilling applications.
A well stimulation pump is a pump used to flow hydrocarbons from the drainage area into the well bore of a oil ...";
CM_ SG_ 2431719166 FlowRate "The amount of fluid that is being pumped by the well stimulation pump.";
CM_ SG_ 2431719166 FluidEndVlvLeak "Indicates the leakage detected in the well stimulation pump fluid end.

00 - No Leak Detected
01 - Leak Detected
10 - Error
11 - Not Available";
CM_ SG_ 2431719166 CavitationStatus "Indicates the level of cavitation detected on the well stimulation pump.

000 - No Cavitation
001 - Low
010 - Medium
011 - High
100 - Reserved
101 - Reserved
110 - Error
111 - Not Available";
CM_ SG_ 2431719166 RodLoad "The load on the plungers of the well stimulation pump.";
CM_ BO_ 2364610046 "DC/DC Converter 1 SLI Battery Status
Status of the SLI battery measured at the SLI battery terminals.

One intended use of this message is for a conventional engine mounted alternator replacement.";
CM_ SG_ 2364610046 SLIBatTermTemp "Parameter indicating the SLI battery terminal temperature for control use by the DC/DC converter.";
CM_ SG_ 2364610046 SLIBatTermCur "Parameter indicating the SLI battery terminal current for control use by the DC/DC converter.  The current is positive if the SLI battery or low side voltage source is being charged from the HVES.";
CM_ SG_ 2364610046 SLIBatTermV "Parameter indicating the SLI battery terminal voltage for control use by the DC/DC converter.";
CM_ BO_ 2364609790 "DC/DC Converter 1 Voltage and Current
Voltage and current data from a DC/DC Converter.

One intended use of this message is for a conventional engine mounted alternator replacement.";
CM_ SG_ 2364609790 HiSideCur "Indicates the measured HVES or high side current measured at the point of control inside the DC/DC Converter.  The current is negative if the converter is charging the SLI battery from the hybrid battery.";
CM_ SG_ 2364609790 HiSideV "Indicates the measured HVES or high side voltage measured at the point of control inside the DC/DC Converter.";
CM_ SG_ 2364609790 LowSideCur "Indicates the measured SLI battery or low side current measured at the point of control inside the DC/DC Converter.  The current is positive if the converter is charging the SLI battery from the hybrid battery.";
CM_ SG_ 2364609790 LowSideV "Indicates the measured SLI battery or low side voltage measured at the point of control inside the DC/DC Converter.";
CM_ BO_ 2364609534 "DC/DC Converter 1 Operating Status
Contains information on the operating status of a DC/DC Converter.

One intended use of this message is for a conventional engine mounted alternator replacement.";
CM_ SG_ 2364609534 PLDueToUndefinedReason "Indicates whether or not output power is being limited due to an undefined reason.

00 - No power limit for this reason
01 - Power limited for this reason
10 - Error
11 - Not Available";
CM_ SG_ 2364609534 PLDueToSLIBatTermTemp "Indicates whether or not output power is being limited due to the SLI battery terminal temperature (see SPN 8591) approaching or exceeding limits (see SPN 8819).
00 - No power limit for this reason
01 - Power limited for this reason
10 - Error
 ...";
CM_ SG_ 2364609534 PLDueToSLIBatTermCur "Indicates whether or not output power is being limited due to the SLI battery terminal current (see SPN 8590) approaching or exceeding limits (see SPN 8818).
00 - No power limit for this reason
01 - Power limited for this reason
10 - Error
11 - ...";
CM_ SG_ 2364609534 PLDueToSLIBatTermV "Indicates whether or not output power is being limited due to the SLI battery terminal voltage (see SPN 8589) approaching or exceeding limits (see SPN 8817).
00 - No power limit for this reason
01 - Power limited for this reason
10 - Error
11 - ...";
CM_ SG_ 2364609534 PLDueToPwrETemp "Indicates whether or not output power is being limited due to Power Electronics Temperature (see SPN 8594) approaching or exceeding the maximum limit.
00 - No power limit for this reason
01 - Power limited for this reason
10 - Error
11 - Not ...";
CM_ SG_ 2364609534 PLDueToElectronicFilterTemp "Indicates whether or not output power is being limited due to Output Electronic Filter Temperature (see SPN 8693) approaching or exceeding the maximum limit.
00 - No power limit for this reason
01 - Power limited for this reason
10 - Error
11 - ...";
CM_ SG_ 2364609534 PLDueToCtrlTemp "Indicates whether or not output power is being limited due to Converter Temperature (see SPN 8592) approaching or exceeding the maximum limit.

00 - No power limit for this reason
01 - Power limited for this reason
10 - Error
11 - Not Available";
CM_ SG_ 2364609534 PLDueToLowSideVMax "Indicates whether or not output power is being limited due to low side voltage (see SPN 8585) approaching or exceeding the maximum limit (see SPN 8567).
00 - No power limit for this reason
01 - Power limited for this reason
10 - Error
11 - Not ...";
CM_ SG_ 2364609534 PLDueToLowSideVMin "Indicates whether or not output power is being limited due to low side voltage (see SPN 8585) approaching or falling below the minimum limit (see SPN 8566).
00 - No power limit for this reason
01 - Power limited for this reason
10 - Error
11 - ...";
CM_ SG_ 2364609534 PLDueToHiSideVMax "Indicates whether or not output power is being limited due to high side voltage (see SPN 8587) approaching or exceeding the maximum limit (see SPN 8564).
00 - No power limit for this reason
01 - Power limited for this reason
10 - Error
11 - Not ...";
CM_ SG_ 2364609534 PLDueToHiSideVMin "Indicates whether or not output power is being limited due to high side voltage (see SPN 8587) approaching or falling below the minimum limit (see SPN 8563).
00 - No power limit for this reason
01 - Power limited for this reason
10 - Error
11 - ...";
CM_ SG_ 2364609534 PLDueToLowSideCur "Indicates whether or not output power is being limited due to low side current (see SPN 8586) approaching or exceeding the maximum limit (see SPN 8568).
00 - No power limit for this reason
01 - Power limited for this reason
10 - Error
11 - Not ...";
CM_ SG_ 2364609534 PLDueToHiSideCur "Indicates whether or not output power is being limited due to high side current (see SPN 8588) approaching or exceeding the maximum limit (see SPN 8565).
00 - No power limit for this reason
01 - Power limited for this reason
10 - Error
11 - Not ...";
CM_ SG_ 2364609534 LoadshedReq "The loadshed request is a request to the controlling device to reduce the DC/DC Converter loads.  The Loadshed Requested state is an indication that this DC/DC Converter has a malfunction or is in a limit condition and if the load of the output is ...";
CM_ SG_ 2364609534 HVILStatus "High Voltage Interlock Loop (HVIL) state of the DC/DC Converter.

00 - HVIL Closed
01 - HVIL Open
10 - Error
11 - Not Available";
CM_ SG_ 2364609534 OperationalStatus "Operating state of the DC/DC Converter
0000 - Disabled
0001 - Initialization in process.  The device is powering up.  This process may include both internal checks, as well as system checks being run by the DC/DC Converter.
0010 - Operational - ...";
CM_ BO_ 2364609278 "DC/DC Converter 1 Control
Controls the transfer of energy between the HVES or high voltage system (i.e. high side) and the SLI battery or low voltage system (i.e. low side).  Provides a function to either charge the SLI Battery from the HVES (Buck) ...";
CM_ SG_ 2364609278 OneLowSideVBuckDefaultSetpoint "The set point for the converter default low side voltage during buck mode.   This setting may be used for when communication has been lost with the controlling device.  When set to Not Available (FFFFh), no default setting is provided and the system ...";
CM_ SG_ 2364609278 HiSideVBoostSetpoint "The set point for regulating the high side voltage during boost mode.";
CM_ SG_ 2364609278 LowSideVBuckSetpoint "The set point for regulating the low side voltage during buck mode.";
CM_ SG_ 2364609278 OperationalCmd "Command to enable or disable operation.
0000 - Disable - in this mode all high voltage switching is disabled
0001 - Operate in standby mode; system is waiting for command to enter buck or boost mode
0010 - Operate in buck mode; energy flows from ...";
CM_ BO_ 2431717886 "Gaseous Fuel Pressure 3";
CM_ SG_ 2431717886 EngFuelVlv1DiffPress "The differential pressure between the intake and the outlet of the first or only gaseous fuel valve.

See SPN 1391 for alternate range and resolution.";
CM_ BO_ 2297499902 "Brakes 2
Contains information on brake control.";
CM_ SG_ 2297499902 BrkPedalSw2 "Second switch signal instance which indicates that the driver operated brake foot pedal is being pressed. This parameter is functionally equivalent to SPN 597, but derived from a second, independent sensor and may be used where redundancy is ...";
CM_ SG_ 2297499902 DemandedBrkAppPress "Gage pressure of the compressed air or fluid in the vehicle braking system that is used to apply brake shoes (or pads) against the brake drums (or discs). This is the brake application pressure demanded by the vehicle operator and / or another ...";
CM_ BO_ 2364608510 "Engine Operating Information 2
Contains engine parameters related to operation.";
CM_ SG_ 2364608510 PwrDerateReq "Derate request made from the engine control system to an external system, where the engine is requesting an external device to reduce the load being applied. A zero value indicates no derate, while any other value indicates the amount of load (in ...";
CM_ SG_ 2364608510 SelfInducedDerateLoad "The self-induced derate load that the Engine Control Module is trying to achieve.  A value of 0% means there is no active derate.";
CM_ BO_ 2498825982 "Dump Truck Body Information
Communicates the status and position of the dump body of an earth moving vehicle.";
CM_ SG_ 2498825982 BodyEjectorBladePos "The dump body ejector blade is used to push material out of the dump body of a dump truck. 0% represents the fully retracted position and 100% represents the fully extended position.";
CM_ SG_ 2498825982 BodyRaisePosRelToRecommendedMax "The angular position of the dump body expressed as a percentage of the maximum recommended body raised position. 100% represents the maximum default raised position of the dump body and is measured related to level ground.
Note:  Depending on the ...";
CM_ SG_ 2498825982 BodyRaiseAngle "The angular position of the dump body referenced to the vehicle chassis. 0 degrees represents the body in its resting position.";
CM_ SG_ 2498825982 BodyRollAngle "The angle between the dump body y-axis and the ground plane (i.e. rotation about the X-axis). The roll angle for a roll to the right is reported with a positive value. Roll angle is the same for both Z-Down and Z-Up axis systems, since both systems ...";
CM_ BO_ 2565934590 "Fuel Information 6 (Gaseous)
Gaseous fuel information 6";
CM_ SG_ 2565934590 EngFuelVlv2DiffPress "The differential pressure between the intake and the outlet of the second gaseous fuel valve.";
CM_ BO_ 2364607742 "High Voltage Energy Storage 1 Data 10
Data set 10 (electrical) for High Voltage Energy Storage pack (or system) 1.";
CM_ SG_ 2364607742 HVBusPassiveIsolTestResults "The isolation resistance expressed in Ohms per Volt that resulted from the High-Voltage Bus Passive Isolation Test.
See HVES1 High-Voltage Bus Passive Isolation Test Status (SPN 8097) for test status and HVES1 High-Voltage Bus Active Isolation Test ...";
CM_ SG_ 2364607742 HVBusActiveIsolTestResults "The isolation resistance expressed in Ohms per Volt that resulted from the High-Voltage Bus Active Isolation Test.
See HVES1 High-Voltage Bus Active Isolation Test Status (SPN 8096) for test status and HVES1 High-Voltage Bus Active Isolation Test ...";
CM_ SG_ 2364607742 LowestCellStOfChargeCellNum "Identifies the location of the HVES1 Lowest Cell State of Charge (SPN 8084) within the HVES1 Lowest Cell State of Charge Module Number (SPN 8247).";
CM_ SG_ 2364607742 LowestCellStOfChargeModuleNum "Identifies the location of the module containing the HVES1 Lowest Cell State of Charge (SPN 8084).";
CM_ SG_ 2364607742 HighestCellStOfChargeCellNum "Identifies the location of the HVES1 Highest Cell State of Charge (SPN 8085) within the HVES1 Highest Cell State of Charge Module Number (SPN 8245).";
CM_ SG_ 2364607742 HighestCellStOfChargeModuleNum "Identifies the location of the module containing the HVES1 Highest Cell State of Charge (SPN 8085).";
CM_ BO_ 2364607486 "High Voltage Energy Storage 1 Data 9
Data set 9 (thermal) for High Voltage Energy Storage pack (or system) 1.";
CM_ SG_ 2364607486 LowestCellTempCellNum "Identifies the location of the HVES1 Lowest Cell Temperature (SPN 8076) within the HVES1 Lowest Cell Temperature Module Number (SPN 8243).";
CM_ SG_ 2364607486 LowestCellTempModuleNum "Identifies the location of the module containing the HVES1 Lowest Cell Temperature (SPN 8076).";
CM_ SG_ 2364607486 HighestCellTempCellNum "Identifies the location of the HVES1 Highest Cell Temperature (SPN 8075) within the HVES1 Highest Cell Temperature Module Number (SPN 8241).";
CM_ SG_ 2364607486 HighestCellTempModuleNum "Identifies the location of the module containing the HVES1 Highest Cell Temperature (SPN 8075).";
CM_ BO_ 2364607230 "High Voltage Energy Storage 1 Data 8
Data set 8 (electrical data) for High Voltage Energy Storage pack (or system) 1.";
CM_ SG_ 2364607230 AvgCellV "The average cell voltage in the High Voltage Energy Storage 1 pack (or system).";
CM_ SG_ 2364607230 LowestCellVCellNum "Identifies the location of the HVES1 Lowest Cell Voltage (SPN 5923) within the HVES1 Lowest Cell Voltage Module Number (SPN 8238).";
CM_ SG_ 2364607230 LowestCellVModuleNum "Identifies the location of the module containing the HVES1 Lowest Cell Voltage (SPN 5923).";
CM_ SG_ 2364607230 HighestCellVCellNum "Identifies the location of HVES1 Highest Cell Voltage (SPN 5922) within the HVES1 Highest Cell Voltage Module Number (SPN 8236).";
CM_ SG_ 2364607230 HighestCellVModuleNum "Identifies the location of the module containing the HVES1 Highest Cell Voltage (SPN 5922).";
CM_ BO_ 2364606974 "High Voltage Energy Storage 1 Thermal Management System Status 1
A collection of data that High Voltage Energy Storage 1 Thermal Management System sends to the Hybrid Controller.";
CM_ SG_ 2364606974 TMSMode "Indicates the operating mode of the Thermal Management System.  The heat transfer medium may be (e.g. liquid or air).  The cooling system may be fans, liquid coolant, or a combination of mediums.  The system may include an air and/or liquid ...";
CM_ SG_ 2364606974 TMSHtrStatus "This is the state of the High Voltage Energy Storage 1 heater

00 - Heater Off
01 - Heater On
10 - Error 
11 - Not Available";
CM_ SG_ 2364606974 TMSRelHumidty "When the High Voltage Energy Storage 1 Thermal Management System is equipped with a relative humidity sensor, this is the  measured Relative Humidity.";
CM_ SG_ 2364606974 TMSCompressorSpd "When the High Voltage Energy Storage 1 Thermal Management System is equipped with an active cooling system (e.g. air conditioner), this is the Compressor Speed.";
CM_ SG_ 2364606974 TMSHVInputPwr "In multiple HVES configurations, this is the high-voltage power consumed by the HVES1 Thermal Management System (TMS).   If there is only one HVES, or a single TMS for all HVES, then this represents the total high voltage power consumed.";
CM_ SG_ 2364606974 TMSSLIInputPwr "In multiple HVES configurations, this is the low-voltage power consumed by the HVES1 Thermal Management System (TMS).   If there is only one HVES, or a single TMS for all HVES, then this represents the total low-voltage power consumed.";
CM_ BO_ 2364606718 "High Voltage Energy Storage 1 Module Status 1
Module Status message 1 for High Voltage Energy Storage pack (or system) 1.";
CM_ SG_ 2364606718 Module16OperationalStatus "Operational Status of the High Voltage Energy Storage 1 Module 16.  Not Operational is used when the module is initializing or not able to function (e.g. internal module level monitors have failed).  Operational indicates that the module is fully ...";
CM_ SG_ 2364606718 Module15OperationalStatus "Operational Status of the High Voltage Energy Storage 1 Module 15.  Not Operational is used when the module is initializing or not able to function (e.g. internal module level monitors have failed).  Operational indicates that the module is fully ...";
CM_ SG_ 2364606718 Module14OperationalStatus "Operational Status of the High Voltage Energy Storage 1 Module 14.  Not Operational is used when the module is initializing or not able to function (e.g. internal module level monitors have failed).  Operational indicates that the module is fully ...";
CM_ SG_ 2364606718 Module13OperationalStatus "Operational Status of the High Voltage Energy Storage 1 Module 13.  Not Operational is used when the module is initializing or not able to function (e.g. internal module level monitors have failed).  Operational indicates that the module is fully ...";
CM_ SG_ 2364606718 Module12OperationalStatus "Operational Status of the High Voltage Energy Storage 1 Module 12.  Not Operational is used when the module is initializing or not able to function (e.g. internal module level monitors have failed).  Operational indicates that the module is fully ...";
CM_ SG_ 2364606718 Module11OperationalStatus "Operational Status of the High Voltage Energy Storage 1 Module 11.  Not Operational is used when the module is initializing or not able to function (e.g. internal module level monitors have failed).  Operational indicates that the module is fully ...";
CM_ SG_ 2364606718 Module10OperationalStatus "Operational Status of the High Voltage Energy Storage 1 Module 10.  Not Operational is used when the module is initializing or not able to function (e.g. internal module level monitors have failed).  Operational indicates that the module is fully ...";
CM_ SG_ 2364606718 Module9OperationalStatus "Operational Status of the High Voltage Energy Storage 1 Module 9.  Not Operational is used when the module is initializing or not able to function (e.g. internal module level monitors have failed).  Operational indicates that the module is fully ...";
CM_ SG_ 2364606718 Module8OperationalStatus "Operational Status of the High Voltage Energy Storage 1 Module 8.  Not Operational is used when the module is initializing or not able to function (e.g. internal module level monitors have failed).  Operational indicates that the module is fully ...";
CM_ SG_ 2364606718 Module7OperationalStatus "Operational Status of the High Voltage Energy Storage 1 Module 7.  Not Operational is used when the module is initializing or not able to function (e.g. internal module level monitors have failed).  Operational indicates that the module is fully ...";
CM_ SG_ 2364606718 Module6OperationalStatus "Operational Status of the High Voltage Energy Storage 1 Module 6.  Not Operational is used when the module is initializing or not able to function (e.g. internal module level monitors have failed).  Operational indicates that the module is fully ...";
CM_ SG_ 2364606718 Module5OperationalStatus "Operational Status of the High Voltage Energy Storage 1 Module 5.  Not Operational is used when the module is initializing or not able to function (e.g. internal module level monitors have failed).  Operational indicates that the module is fully ...";
CM_ SG_ 2364606718 Module4OperationalStatus "Operational Status of the High Voltage Energy Storage 1 Module 4.  Not Operational is used when the module is initializing or not able to function (e.g. internal module level monitors have failed).  Operational indicates that the module is fully ...";
CM_ SG_ 2364606718 Module3OperationalStatus "Operational Status of the High Voltage Energy Storage 1 Module 3.  Not Operational is used when the module is initializing or not able to function (e.g. internal module level monitors have failed).  Operational indicates that the module is fully ...";
CM_ SG_ 2364606718 Module2OperationalStatus "Operational Status of the High Voltage Energy Storage 1 Module 2.  Not Operational is used when the module is initializing or not able to function (e.g. internal module level monitors have failed).  Operational indicates that the module is fully ...";
CM_ SG_ 2364606718 Module1OperationalStatus "Operational Status of the High Voltage Energy Storage 1 Module 1.  Not Operational is used when the module is initializing or not able to function (e.g. internal module level monitors have failed).  Operational indicates that the module is fully ...";
CM_ BO_ 2565933054 "Well Stimulation Pump System 2
Communicates operating parameters of a well stimulation pump used in oil and gas drilling applications.
A well stimulation pump is a pump used to flow hydrocarbons from the drainage area into the well bore of a oil ...";
CM_ SG_ 2565933054 Spd "The operating speed of the well stimulation pump.";
CM_ SG_ 2565933054 GearBoxOilTemp "Temperature of the oil in the well stimulation pump gear box.";
CM_ SG_ 2565933054 GearBoxOilPress "The oil pressure measured in the well stimulation pump gear box.";
CM_ BO_ 2565932798 "Well Stimulation Pump System 1
Communicates operating parameters of a well stimulation pump used in oil and gas drilling applications.
A well stimulation pump is a pump used to flow hydrocarbons from the drainage area into the well bore of a oil ...";
CM_ SG_ 2565932798 DisPress "The pressure on the discharge side of the well stimulation pump.";
CM_ SG_ 2565932798 SuctionPress "The pressure on the suction side of the well stimulation pump.";
CM_ BO_ 2364605950 "Hydraulic Pressure Displacement
Sensors related to hydraulic measurement and displacement.";
CM_ SG_ 2364605950 MechMovementAngle "The angle of rotation of the mechanical component.
The increase and decrease of the value (i.e. rotation about the X-axis) is in accordance to the right-hand rule, as specified in SAE J670, with the positive X axis directed inward along the center ...";
CM_ SG_ 2364605950 LinePress "The pressure of the hydraulic fluid, measured in the hydraulic line.";
CM_ BO_ 2565932286 "Engine Speed Sensor Information 2
This PGN contains the speed information and status signal of each engine speed sensor. This message is used for service to troubleshoot no-start or hard start problems.  This message is not needed except for ...";
CM_ SG_ 2565932286 Vour "The engine speed as measured by speed sensor 4.
Notes: This is for the engine speed from the 4th engine speed sensor. This may be different than SPN 190 when used in multiple engine speed sensor configurations. In an application with multiple ...";
CM_ BO_ 2364605438 "Generator Trip Energy
This PGN contains quantities for the \"trip\" energy from the generator.

These values can be reset by the user.";
CM_ SG_ 2364605438 KVArHoursExport "The trip AC reactive energy exported by the generstor since the last reset of the trip kVArh meter.

This value will be reset by the user at will.";
CM_ SG_ 2364605438 KWHoursExport "The total kilowatt-hours that have been exported by the generator since the last reset of the trip kWh meter.

This value will be reset by the user at will.";
CM_ BO_ 2364605182 "Primary or Rear Hitch Roll and Pitch Command
Provides control of rear hitch roll and pitch.";
CM_ SG_ 2364605182 PitchSensitivityCmd "Command for setting the sensitivity of the rear hitch pitch control expressed as a percentage of the maximum gain. 0% indicates minimal gain in the control loop; 100%, the maximum gain. Values near zero may result in no reaction by the control loop.";
CM_ SG_ 2364605182 PitchCmd "Command for setting the pitch angle of the rear three-point hitch expressed in degrees from vertical alignment of the upper and lower attachment points. Positive is in the anti-clockwise direction when viewed from the left-hand side of the tractor.";
CM_ SG_ 2364605182 SensitivityCmd "Command for setting the sensitivity of the rear hitch roll control expressed as a percentage of the maximum gain. 0% indicates minimal gain in the control loop; 100%, the maximum gain. Values near zero may result in no reaction by the control loop.";
CM_ SG_ 2364605182 Cmd "Command for setting the roll angle of the rear three-point hitch expressed in degrees with 0 being horizontally aligned with the rear axle of the tractor. Facing the direction of travel, an anti-clockwise rotation would be indicated by a negative ...";
CM_ BO_ 2364604926 "Primary or Rear Hitch Roll and Pitch
Provides roll and pitch information for the rear hitch.";
CM_ SG_ 2364604926 PitchExit_ReasonCode "Used to indicate why the rear hitch cannot accept remote pitch commands or has most recently stopped accepting remote commands.
000000 = No reason/all clear
000001 = Required level of operator presence/awareness not detected
000010 = Implement ...";
CM_ SG_ 2364604926 PitchLmtSt "Used to report the Tractor ECU's present limit status associated with the rear hitch pitch commands.
000 = Not limited
001 = Operator limited/controlled (request cannot be implemented)
010 = Limited High (only lower command values result in a ...";
CM_ SG_ 2364604926 PitchAngle "Measured pitch angle of the rear three-point hitch expressed in degrees from vertical alignment of the upper and lower attachment points. Positive is in the anti-clockwise direction when viewed from the left-hand side of the tractor.";
CM_ SG_ 2364604926 Exit_ReasonCode "Used to indicate why the rear hitch cannot accept remote roll commands or has most recently stopped accepting remote commands.
000000 = No reason/all clear
000001 = Required level of operator presence/awareness not detected
000010 = Implement ...";
CM_ SG_ 2364604926 LmtSt "Used to report the Tractor ECU's present limit status associated with the rear hitch roll commands.
000 = Not limited
001 = Operator limited/controlled (request cannot be implemented)
010 = Limited High (only lower command values result in a ...";
CM_ SG_ 2364604926 Angle "Measured roll angle of the rear three-point hitch expressed in degrees from horizontal alignment with the rear axle of the tractor. Facing the direction of travel, an anti-clockwise rotation would be indicated by a negative number and a clockwise ...";
CM_ BO_ 2364604670 "Secondary or Front Hitch Roll and Pitch Command
Provides control of front hitch roll and pitch.";
CM_ SG_ 2364604670 PitchSensitivityCmd "Command for setting the sensitivity of the front hitch pitch control expressed as a percentage of the maximum gain. 0% indicates minimal gain in the control loop; 100%, the maximum gain. Values near zero may result in no reaction by the control ...";
CM_ SG_ 2364604670 PitchCmd "Command for setting the pitch angle of the front three-point hitch expressed in degrees from vertical alignment of the upper and lower attachment points. Positive is in the anti-clockwise direction when viewed from the left-hand side of the tractor.";
CM_ SG_ 2364604670 SensitivityCmd "Command for setting the sensitivity of the front hitch roll control expressed as a percentage of the maximum gain. 0% indicates minimal gain in the control loop; 100%, the maximum gain. Values near zero may result in no reaction by the control loop.";
CM_ SG_ 2364604670 Cmd "Command for setting the roll angle of the front three-point hitch expressed in degrees with 0 being horizontally aligned with the rear axle of the tractor. Facing the direction of travel, an anti-clockwise rotation would be indicated by a negative ...";
CM_ BO_ 2364604414 "Secondary or Front Hitch Roll and Pitch
Provides roll and pitch information for the front hitch.";
CM_ SG_ 2364604414 PitchExit_ReasonCode "Used to indicate why the front hitch cannot accept remote pitch commands or has most recently stopped accepting remote commands.
000000 = No reason/all clear
000001 = Required level of operator presence/awareness not detected
000010 = Implement ...";
CM_ SG_ 2364604414 PitchLmtSt "Used to report the Tractor ECU's present limit status associated with the front hitch pitch commands.
000 = Not limited
001 = Operator limited/controlled (request cannot be implemented)
010 = Limited High (only lower command values result in a ...";
CM_ SG_ 2364604414 PitchAngle "Measured pitch angle of the front three-point hitch expressed in degrees from vertical alignment of the upper and lower attachment points. Positive is in the anti-clockwise direction when viewed from the left-hand side of the tractor.";
CM_ SG_ 2364604414 Exit_ReasonCode "Used to indicate why the front hitch cannot accept remote roll commands or has most recently stopped accepting remote commands.
000000 = No reason/all clear
000001 = Required level of operator presence/awareness not detected
000010 = Implement ...";
CM_ SG_ 2364604414 LmtSt "Used to report the Tractor ECU's present limit status associated with the front hitch roll commands.
000 = Not limited
001 = Operator limited/controlled (request cannot be implemented)
010 = Limited High (only lower command values result in a ...";
CM_ SG_ 2364604414 Angle "Measured roll angle of the front three-point hitch expressed in degrees from horizontal alignment with the rear axle of the tractor. Facing the direction of travel, an anti-clockwise rotation would be indicated by a negative number and a clockwise ...";
CM_ BO_ 2364604158 "Aftertreatment 2 SCR Dosing System Information 4
This message contains SCR dosing system information for aftertreatment system 2 (or bank 2).";
CM_ SG_ 2364604158 DEFActualQuantityOfIntegrator "The SCR requested diesel exhaust fluid integrator total quantity for aftertreatment system 2 (exhaust bank 2).  See SPN 4386 for alternate resolution.";
CM_ BO_ 2364603902 "Aftertreatment 1 SCR Dosing System Information 4
This message contains SCR dosing system request information for aftertreatment system 1 (or bank 1).";
CM_ SG_ 2364603902 DEFActualQuantityOfIntegrator "The SCR requested diesel exhaust fluid integrator total quantity for aftertreatment system 1 (exhaust bank 1).  See SPN 4333 for alternate resolution.";
CM_ BO_ 2364603646 "Aftertreatment 2 SCR Dosing System Requests 3
This message contains SCR dosing system request information for aftertreatment system 2 (or bank 2).";
CM_ SG_ 2364603646 DEFReqQuantityOfIntegrator "Represents the command for the diesel exhaust fluid quantity integrator in the dosing control unit. See SPN 4403 for alternate resolution.";
CM_ BO_ 2364603390 "Aftertreatment 1 SCR Dosing System Requests 3
This message contains SCR dosing system request information for aftertreatment system 1 (or bank 1).";
CM_ SG_ 2364603390 DEFDoserVlv1Cmd "Command (in percent) sent to the diesel exhaust fluid (DEF) injector to control the amount of DEF being injected into the aftreatment exhaust stream.

0% closes the valve; 100% fully opens the valve.";
CM_ SG_ 2364603390 DEFReqQuantityOfIntegrator "Represents the command for the diesel exhaust fluid quantity integrator in the dosing control unit. See SPN 4350 for alternate resolution.";
CM_ BO_ 2364603134 "Electronic Transmission Controller 13
Electronic Transmission Controller 13";
CM_ SG_ 2364603134 SAOfActiveOrPendingTransReqGear "This parameter indicates the source address of the device whose SPN 525 [Transmission Requested Gear] request is currently being acted upon by the transmission. If transmission response to a device뭩 SPN 525 request is pending, that device뭩 source ...";
CM_ SG_ 2364603134 MaxReverseTransOSS "Maximum transmission output shaft speed that can be achieved in the reverse direction, based on current operating conditions.";
CM_ SG_ 2364603134 MaxForwardTransOSS "Maximum transmission output shaft speed that can be achieved in the forward direction, based on current operating conditions.";
CM_ BO_ 2364602878 "Engine Valve Controller
Transmits information about the engine valve control  module used to control the valves on the engine.";
CM_ SG_ 2364602878 CtrlModule8PreliminaryFMI "Used to identify the applicable J1939-73 FMI detected in Engine Valve Control Module 8 by the manufacturer's software.  When there are multiple failures, the most severe is transmitted.
A value of 31 is sent to indicate that no failure has been ...";
CM_ SG_ 2364602878 CtrlModule7PreliminaryFMI "Used to identify the applicable J1939-73 FMI detected in Engine Valve Control Module 7 by the manufacturer's software. When there are multiple failures, the most severe is transmitted.
A value of 31 is sent to indicate that no failure has been ...";
CM_ SG_ 2364602878 CtrlModule6PreliminaryFMI "Used to identify the applicable J1939-73 FMI detected in Engine Valve Control Module 6 by the manufacturer's software.  When there are multiple failures, the most severe is transmitted.
A value of 31 is sent to indicate that no failure has been ...";
CM_ SG_ 2364602878 CtrlModule5PreliminaryFMI "Used to identify the applicable J1939-73 FMI detected in Engine Valve Control Module 5 by the manufacturer's software.  When there are multiple failures, the most severe is transmitted.
A value of 31 is sent to indicate that no failure has been ...";
CM_ SG_ 2364602878 CtrlModule4PreliminaryFMI "Used to identify the applicable J1939-73 FMI detected in Engine Valve Control Module 4 by the manufacturer's software.  When there are multiple failures, the most severe is transmitted.
A value of 31 is sent to indicate that no failure has been ...";
CM_ SG_ 2364602878 CtrlModule3PreliminaryFMI "Used to identify the applicable J1939-73 FMI detected in Engine Valve Control Module 3 by the manufacturer's software.  When there are multiple failures, the most severe is transmitted.
A value of 31 is sent to indicate that no failure has been ...";
CM_ SG_ 2364602878 CtrlModule2PreliminaryFMI "Used to identify the applicable J1939-73 FMI detected in Engine Valve Control Module 2 by the manufacturer's software.  When there are multiple failures, the most severe is transmitted.
A value of 31 is sent to indicate that no failure has been ...";
CM_ SG_ 2364602878 CtrlModule1PreliminaryFMI "Used to identify the applicable J1939-73 FMI detected in Engine Valve Control Module 1 by the manufacturer's software.  When there are multiple failures, the most severe is transmitted.
A value of 31 is sent to indicate that no failure has been ...";
CM_ BO_ 2565923838 "DC/AC Accessory Inverter 4 Feedback
Sent by this DC/AC Accessory Inverter instance and contains the current operating conditions of this output of the inverter.  This message would be received by a controller application (e.g. Power System Manager) ...";
CM_ SG_ 2565923838 HVILStatus "High Voltage Interlock Loop (HVIL) state of the DC/AC Accessory Inverter 4.

00 - HVIL Closed
01 - HVIL Open
10 - Error
11 - Not Available";
CM_ SG_ 2565923838 ACSideRMSCur "Present operating AC Side output RMS line Current of this DC/AC Accessory Inverter.  When connected to a balanced three phase motor, this would be the current in each individual phase of the motor.";
CM_ SG_ 2565923838 LoadshedReq "Loadshed Request from this DC/AC Accessory Inverter output.  The Loadshed Requested state is an indication that the inverter output powering this device has a malfunction and is in a limit condition and if the load of the output is not reduced, the ...";
CM_ SG_ 2565923838 StatusFeedback "Operating Status of this DC/AC Accessory Inverter output. The Inverter Output Faulted state will be communicated when the inverter output has shutdown due to an overload condition or other fault.
000 - Output Disabled
001 - Output Enabled
010 - ...";
CM_ SG_ 2565923838 PwrFeedback "Present operating AC Side power of this DC/AC Accessory Inverter output.";
CM_ SG_ 2565923838 VFeedback "Present operating AC Side line to line RMS voltage of this DC/AC Accessory Inverter output.  In a three phase balanced motor, this is the RMS voltage across one phase of the motor.";
CM_ SG_ 2565923838 FreqFeedback "Present operating frequency of this DC/AC Accessory Inverter output.";
CM_ BO_ 2565923582 "DC/AC Accessory Inverter 4 Command
Used to command this instance of an DC/AC Accessory Inverter that uses a V/Hz algorithm.  The Inverter may have multiple outputs to power accessories on a vehicle (e.g. HVAC compressor, air compressor, power ...";
CM_ SG_ 2565923582 ACSideMotorStartingRMSVReq "Signal to the DC/AC Accessory Inverter indicating the requested AC side RMS voltage for starting the attached accessory motor.   In a V/Hz variable speed motor control application, this voltage typically may be set to a non-zero value when an ...";
CM_ SG_ 2565923582 EnableCmd "Command to the DC/AC Accessory Inverter to enable this output.  Each output may control multiple devices (e.g. electric motors) if they all operate at the same frequency.
00 - Disable DC/AC Accessory Inverter Output
01 - Enable DC/AC Accessory ...";
CM_ SG_ 2565923582 Device2Status "Signal to the DC/AC Accessory Inverter indicating the state of the device attached to the inverter output.  Each output may control multiple devices (e.g. electric motors) if they all operate at the same frequency.
The Faulted Off state will be ...";
CM_ SG_ 2565923582 Device1Status "Signal to the DC/AC Accessory Inverter indicating the state of the device attached to the inverter output.  Each output may control multiple devices (e.g. electric motors) if they all operate at the same frequency.
The Faulted Off state will be ...";
CM_ SG_ 2565923582 FreqCmd "Command to the DC/AC Accessory Inverter indicating the Inverter frequency desired for the device(s) attached to the inverter output.  Each output may control multiple devices (e.g. electric motors) if they all operate at the same frequency.";
CM_ SG_ 2565923582 DeviceFreqRateOfChangeLmt "Signal to the DC/AC Accessory Inverter indicating the frequency rate of change limit of the device(s) attached to the inverter output (Note: Increasing and decreasing rates can be controlled by the same signal).  Each output may control multiple ...";
CM_ SG_ 2565923582 DeviceRatedV "Signal to the DC/AC Accessory Inverter indicating the rated RMS voltage of the device(s) attached to the inverter output.   Each output may control multiple devices (e.g. electric motors) if they all operate at the same frequency.";
CM_ SG_ 2565923582 DeviceRatedFreq "Signal to the DC/AC Accessory Inverter indicating the rated frequency of the device(s) attached to the inverter output.  Each output may control multiple devices (e.g. electric motors) if they all operate at the same frequency.";
CM_ SG_ 2565923582 DeviceMinFreq "Signal to the DC/AC Accessory Inverter indicating the minimum frequency of the device(s) attached to the inverter output.  Each output may control multiple devices (e.g. electric motors) if they all operate at the same frequency.";
CM_ SG_ 2565923582 DeviceMaxFreq "Signal to the DC/AC Accessory Inverter indicating the maximum frequency of the devices(s) attached to the inverter output.  Each output may control multiple devices (e.g. electric motors) if they all operate at the same frequency.";
CM_ BO_ 2565922814 "DC/AC Accessory Inverter 3 Feedback
Sent by this DC/AC Accessory Inverter instance and contains the current operating conditions of this output of the inverter.  This message would be received by a controller application (e.g. Power System Manager) ...";
CM_ SG_ 2565922814 HVILStatus "High Voltage Interlock Loop (HVIL) state of the DC/AC Accessory Inverter 3.

00 - HVIL Closed
01 - HVIL Open
10 - Error
11 - Not Available";
CM_ SG_ 2565922814 ACSideRMSCur "Present operating AC Side output RMS line Current of this DC/AC Accessory Inverter.  When connected to a balanced three phase motor, this would be the current in each individual phase of the motor.";
CM_ SG_ 2565922814 LoadshedReq "Loadshed Request from this DC/AC Accessory Inverter output.  The Loadshed Requested state is an indication that the inverter output powering this device has a malfunction and is in a limit condition and if the load of the output is not reduced, the ...";
CM_ SG_ 2565922814 StatusFeedback "Operating Status of this DC/AC Accessory Inverter output. The Inverter Output Faulted state will be communicated when the inverter output has shutdown due to an overload condition or other fault.
000 - Output Disabled
001 - Output Enabled
010 - ...";
CM_ SG_ 2565922814 PwrFeedback "Present operating AC Side power of this DC/AC Accessory Inverter output.";
CM_ SG_ 2565922814 VFeedback "Present operating AC Side line to line RMS voltage of this DC/AC Accessory Inverter output.  In a three phase balanced motor, this is the RMS voltage across one phase of the motor.";
CM_ SG_ 2565922814 FreqFeedback "Present operating frequency of this DC/AC Accessory Inverter output.";
CM_ BO_ 2565922558 "DC/AC Accessory Inverter 3 Command
Used to command this instance of an DC/AC Accessory Inverter that uses a V/Hz algorithm.  The Inverter may have multiple outputs to power accessories on a vehicle (e.g. HVAC compressor, air compressor, power ...";
CM_ SG_ 2565922558 ACSideMotorStartingRMSVReq "Signal to the DC/AC Accessory Inverter indicating the requested AC side RMS voltage for starting the attached accessory motor.   In a V/Hz variable speed motor control application, this voltage typically may be set to a non-zero value when an ...";
CM_ SG_ 2565922558 EnableCmd "Command to the DC/AC Accessory Inverter to enable this output.  Each output may control multiple devices (e.g. electric motors) if they all operate at the same frequency.
00 - Disable DC/AC Accessory Inverter Output
01 - Enable DC/AC Accessory ...";
CM_ SG_ 2565922558 Device2Status "Signal to the DC/AC Accessory Inverter indicating the state of the device attached to the inverter output.  Each output may control multiple devices (e.g. electric motors) if they all operate at the same frequency.
The Faulted Off state will be ...";
CM_ SG_ 2565922558 Device1Status "Signal to the DC/AC Accessory Inverter indicating the state of the device attached to the inverter output.  Each output may control multiple devices (e.g. electric motors) if they all operate at the same frequency.
The Faulted Off state will be ...";
CM_ SG_ 2565922558 FreqCmd "Command to the DC/AC Accessory Inverter indicating the Inverter frequency desired for the device(s) attached to the inverter output.  Each output may control multiple devices (e.g. electric motors) if they all operate at the same frequency.";
CM_ SG_ 2565922558 DeviceFreqRateOfChangeLmt "Signal to the DC/AC Accessory Inverter indicating the frequency rate of change limit of the device(s) attached to the inverter output (Note: Increasing and decreasing rates can be controlled by the same signal).  Each output may control multiple ...";
CM_ SG_ 2565922558 DeviceRatedV "Signal to the DC/AC Accessory Inverter indicating the rated RMS voltage of the device(s) attached to the inverter output.   Each output may control multiple devices (e.g. electric motors) if they all operate at the same frequency.";
CM_ SG_ 2565922558 DeviceRatedFreq "Signal to the DC/AC Accessory Inverter indicating the rated frequency of the device(s) attached to the inverter output.  Each output may control multiple devices (e.g. electric motors) if they all operate at the same frequency.";
CM_ SG_ 2565922558 DeviceMinFreq "Signal to the DC/AC Accessory Inverter indicating the minimum frequency of the device(s) attached to the inverter output.  Each output may control multiple devices (e.g. electric motors) if they all operate at the same frequency.";
CM_ SG_ 2565922558 DeviceMaxFreq "Signal to the DC/AC Accessory Inverter indicating the maximum frequency of the devices(s) attached to the inverter output.  Each output may control multiple devices (e.g. electric motors) if they all operate at the same frequency.";
CM_ BO_ 2565921790 "DC/AC Accessory Inverter 2 Feedback
Sent by this DC/AC Accessory Inverter instance and contains the current operating conditions of this output of the inverter.  This message would be received by a controller application (e.g. Power System Manager) ...";
CM_ SG_ 2565921790 HVILStatus "High Voltage Interlock Loop (HVIL) state of the DC/AC Accessory Inverter 2.

00 - HVIL Closed
01 - HVIL Open
10 - Error
11 - Not Available";
CM_ SG_ 2565921790 ACSideRMSCur "Present operating AC Side output RMS line Current of this DC/AC Accessory Inverter.  When connected to a balanced three phase motor, this would be the current in each individual phase of the motor.";
CM_ SG_ 2565921790 LoadshedReq "Loadshed Request from this DC/AC Accessory Inverter output.  The Loadshed Requested state is an indication that the inverter output powering this device has a malfunction and is in a limit condition and if the load of the output is not reduced, the ...";
CM_ SG_ 2565921790 StatusFeedback "Operating Status of this DC/AC Accessory Inverter output. The Inverter Output Faulted state will be communicated when the inverter output has shutdown due to an overload condition or other fault.
000 - Output Disabled
001 - Output Enabled
010 - ...";
CM_ SG_ 2565921790 PwrFeedback "Present operating AC Side power of this DC/AC Accessory Inverter output.";
CM_ SG_ 2565921790 VFeedback "Present operating AC Side line to line RMS voltage of this DC/AC Accessory Inverter output.  In a three phase balanced motor, this is the RMS voltage across one phase of the motor.";
CM_ SG_ 2565921790 FreqFeedback "Present operating frequency of this DC/AC Accessory Inverter output.";
CM_ BO_ 2565921534 "DC/AC Accessory Inverter 2 Command
Used to command this instance of an DC/AC Accessory Inverter that uses a V/Hz algorithm.  The Inverter may have multiple outputs to power accessories on a vehicle (e.g. HVAC compressor, air compressor, power ...";
CM_ SG_ 2565921534 ACSideMotorStartingRMSVReq "Signal to the DC/AC Accessory Inverter indicating the requested AC side RMS voltage for starting the attached accessory motor.   In a V/Hz variable speed motor control application, this voltage typically may be set to a non-zero value when an ...";
CM_ SG_ 2565921534 EnableCmd "Command to the DC/AC Accessory Inverter to enable this output.  Each output may control multiple devices (e.g. electric motors) if they all operate at the same frequency.
00 - Disable DC/AC Accessory Inverter Output
01 - Enable DC/AC Accessory ...";
CM_ SG_ 2565921534 Device2Status "Signal to the DC/AC Accessory Inverter indicating the state of the device attached to the inverter output.  Each output may control multiple devices (e.g. electric motors) if they all operate at the same frequency.
The Faulted Off state will be ...";
CM_ SG_ 2565921534 Device1Status "Signal to the DC/AC Accessory Inverter indicating the state of the device attached to the inverter output.  Each output may control multiple devices (e.g. electric motors) if they all operate at the same frequency.
The Faulted Off state will be ...";
CM_ SG_ 2565921534 FreqCmd "Command to the DC/AC Accessory Inverter indicating the Inverter frequency desired for the device(s) attached to the inverter output.  Each output may control multiple devices (e.g. electric motors) if they all operate at the same frequency.";
CM_ SG_ 2565921534 DeviceFreqRateOfChangeLmt "Signal to the DC/AC Accessory Inverter indicating the frequency rate of change limit of the device(s) attached to the inverter output (Note: Increasing and decreasing rates can be controlled by the same signal).  Each output may control multiple ...";
CM_ SG_ 2565921534 DeviceRatedV "Signal to the DC/AC Accessory Inverter indicating the rated RMS voltage of the device(s) attached to the inverter output.   Each output may control multiple devices (e.g. electric motors) if they all operate at the same frequency.";
CM_ SG_ 2565921534 DeviceRatedFreq "Signal to the DC/AC Accessory Inverter indicating the rated frequency of the device(s) attached to the inverter output.  Each output may control multiple devices (e.g. electric motors) if they all operate at the same frequency.";
CM_ SG_ 2565921534 DeviceMinFreq "Signal to the DC/AC Accessory Inverter indicating the minimum frequency of the device(s) attached to the inverter output.  Each output may control multiple devices (e.g. electric motors) if they all operate at the same frequency.";
CM_ SG_ 2565921534 DeviceMaxFreq "Signal to the DC/AC Accessory Inverter indicating the maximum frequency of the devices(s) attached to the inverter output.  Each output may control multiple devices (e.g. electric motors) if they all operate at the same frequency.";
CM_ BO_ 2565920766 "DC/AC Accessory Inverter 1 Feedback
Sent by this DC/AC Accessory Inverter instance and contains the current operating conditions of this output of the inverter.  This message would be received by a controller application (e.g. Power System Manager) ...";
CM_ SG_ 2565920766 HVILStatus "High Voltage Interlock Loop (HVIL) state of the DC/AC Accessory Inverter 1.

00 - HVIL Closed
01 - HVIL Open
10 - Error
11 - Not Available";
CM_ SG_ 2565920766 ACSideRMSCur "Present operating AC Side output RMS line Current of this DC/AC Accessory Inverter.  When connected to a balanced three phase motor, this would be the current in each individual phase of the motor.";
CM_ SG_ 2565920766 LoadshedReq "Loadshed Request from this DC/AC Accessory Inverter output.  The Loadshed Requested state is an indication that the inverter output powering this device has a malfunction and is in a limit condition and if the load of the output is not reduced, the ...";
CM_ SG_ 2565920766 StatusFeedback "Operating Status of this DC/AC Accessory Inverter output. The Inverter Output Faulted state will be communicated when the inverter output has shutdown due to an overload condition or other fault.
000 - Output Disabled
001 - Output Enabled
010 - ...";
CM_ SG_ 2565920766 PwrFeedback "Present operating AC Side power of this DC/AC Accessory Inverter output.";
CM_ SG_ 2565920766 VFeedback "Present operating AC Side line to line RMS voltage of this DC/AC Accessory Inverter output.  In a three phase balanced motor, this is the RMS voltage across one phase of the motor.";
CM_ SG_ 2565920766 FreqFeedback "Present operating frequency of this DC/AC Accessory Inverter output.";
CM_ BO_ 2565920510 "DC/AC Accessory Inverter 1 Command
Used to command this instance of an DC/AC Accessory Inverter that uses a V/Hz algorithm.  The Inverter may have multiple outputs to power accessories on a vehicle (e.g. HVAC compressor, air compressor, power ...";
CM_ SG_ 2565920510 ACSideMotorStartingRMSVReq "Signal to the DC/AC Accessory Inverter indicating the requested AC side RMS voltage for starting the attached accessory motor.   In a V/Hz variable speed motor control application, this voltage typically may be set to a non-zero value when an ...";
CM_ SG_ 2565920510 EnableCmd "Command to the DC/AC Accessory Inverter to enable this output.  Each output may control multiple devices (e.g. electric motors) if they all operate at the same frequency.
00 - Disable DC/AC Accessory Inverter Output
01 - Enable DC/AC Accessory ...";
CM_ SG_ 2565920510 Device2Status "Signal to the DC/AC Accessory Inverter indicating the state of the device attached to the inverter output.  Each output may control multiple devices (e.g. electric motors) if they all operate at the same frequency.
The Faulted Off state will be ...";
CM_ SG_ 2565920510 Device1Status "Signal to the DC/AC Accessory Inverter indicating the state of the device attached to the inverter output.  Each output may control multiple devices (e.g. electric motors) if they all operate at the same frequency.
The Faulted Off state will be ...";
CM_ SG_ 2565920510 FreqCmd "Command to the DC/AC Accessory Inverter indicating the Inverter frequency desired for the device(s) attached to the inverter output.  Each output may control multiple devices (e.g. electric motors) if they all operate at the same frequency.";
CM_ SG_ 2565920510 DeviceFreqRateOfChangeLmt "Signal to the DC/AC Accessory Inverter indicating the frequency rate of change limit of the device(s) attached to the inverter output (Note: Increasing and decreasing rates can be controlled by the same signal).  Each output may control multiple ...";
CM_ SG_ 2565920510 DeviceRatedV "Signal to the DC/AC Accessory Inverter indicating the rated RMS voltage of the device(s) attached to the inverter output.   Each output may control multiple devices (e.g. electric motors) if they all operate at the same frequency.";
CM_ SG_ 2565920510 DeviceRatedFreq "Signal to the DC/AC Accessory Inverter indicating the rated frequency of the device(s) attached to the inverter output.  Each output may control multiple devices (e.g. electric motors) if they all operate at the same frequency.";
CM_ SG_ 2565920510 DeviceMinFreq "Signal to the DC/AC Accessory Inverter indicating the minimum frequency of the device(s) attached to the inverter output.  Each output may control multiple devices (e.g. electric motors) if they all operate at the same frequency.";
CM_ SG_ 2565920510 DeviceMaxFreq "Signal to the DC/AC Accessory Inverter indicating the maximum frequency of the devices(s) attached to the inverter output.  Each output may control multiple devices (e.g. electric motors) if they all operate at the same frequency.";
CM_ BO_ 2364580094 "High Voltage Energy Storage 1 Data 7
Data set 7 (electrical) for High Voltage Energy Storage pack (or system) 1.";
CM_ SG_ 2364580094 MaxChargeVLmt "The maximum voltage level not to be exceeded while charging the High Voltage Energy Storage 1 pack (or system).  If this parameter is not supported, the maximum charge voltage should be limited to SPN 8117 (HVES1 Recommended Maximum Operating ...";
CM_ SG_ 2364580094 ChargeEnergyCapacity "The amount of unused electrical energy storage available to be filled by charging High Voltage Energy Storage 1 pack (or system), i.e. 밾ow much empty space is remaining in the tank�.  See HVES1 Charge Capacity (SPN 8080) for Ampere-hours (Ah).";
CM_ SG_ 2364580094 DisEnergyCapacity "The amount of stored electrical energy in High Voltage Energy Storage 1 pack (or system) that is available for use by the hybrid system, i.e. 밾ow full is the tank�.  See HVES1 Discharge Capacity (SPN 8079) for Ampere-hours (Ah).";
BA_DEF_ SG_  "SigType" ENUM  "Default","Range","RangeSigned","ASCII","Discrete","Control","ReferencePGN","DTC","StringDelimiter","StringLength","StringLengthControl","MessageCounter","MessageChecksum";
BA_DEF_ SG_  "GenSigStartValue" INT 0 2147483647;
BA_DEF_ SG_  "GenSigSendType" ENUM  "Cyclic","OnWrite","OnWriteWithRepetition","OnChange","OnChangeWithRepetition","IfActive","IfActiveWithRepetition","NoSigSendType";
BA_DEF_ SG_  "GenSigILSupport" ENUM  "No","Yes";
BA_DEF_ SG_  "GenSigEVName" STRING ;
BA_DEF_ SG_  "SPN" INT 0 524287;
BA_DEF_ BO_  "TpJ1939VarDlc" ENUM  "No","Yes";
BA_DEF_ BO_  "GenMsgStartDelayTime" INT 0 100000;
BA_DEF_ BO_  "GenMsgILSupport" ENUM  "No","Yes";
BA_DEF_ BO_  "GenMsgDelayTime" INT 0 1000;
BA_DEF_ BO_  "GenMsgRequestable" INT 0 1;
BA_DEF_ BO_  "GenMsgSendType" ENUM  "cyclic","NotUsed","NotUsed","NotUsed","NotUsed","NotUsed","NotUsed","IfActive","noMsgSendType";
BA_DEF_ BO_  "VFrameFormat" ENUM  "StandardCAN","ExtendedCAN","reserved","J1939PG";
BA_DEF_ BO_  "GenMsgCycleTime" INT 0 3600000;
BA_DEF_ SG_  "SystemSignalLongSymbol" STRING ;
BA_DEF_DEF_  "SigType" "Default";
BA_DEF_DEF_  "GenSigStartValue" 0;
BA_DEF_DEF_  "GenSigSendType" "NoSigSendType";
BA_DEF_DEF_  "GenSigILSupport" "Yes";
BA_DEF_DEF_  "GenSigEVName" "Env@Nodename_@Signame";
BA_DEF_DEF_  "SPN" 0;
BA_DEF_DEF_  "TpJ1939VarDlc" "No";
BA_DEF_DEF_  "GenMsgStartDelayTime" 0;
BA_DEF_DEF_  "GenMsgILSupport" "Yes";
BA_DEF_DEF_  "GenMsgDelayTime" 0;
BA_DEF_DEF_  "GenMsgRequestable" 1;
BA_DEF_DEF_  "GenMsgSendType" "noMsgSendType";
BA_DEF_DEF_  "VFrameFormat" "J1939PG";
BA_DEF_DEF_  "GenMsgCycleTime" 0;
BA_DEF_DEF_  "SystemSignalLongSymbol" "";
BA_ "GenMsgCycleTime" BO_ 2566647550 10000;
BA_ "GenMsgSendType" BO_ 2566647550 0;
BA_ "GenMsgCycleTime" BO_ 2566647294 10000;
BA_ "GenMsgSendType" BO_ 2566647294 0;
BA_ "GenMsgCycleTime" BO_ 2566647038 10000;
BA_ "GenMsgSendType" BO_ 2566647038 0;
BA_ "GenMsgCycleTime" BO_ 2566646782 10000;
BA_ "GenMsgSendType" BO_ 2566646782 0;
BA_ "TpJ1939VarDlc" BO_ 2633755134 1;
BA_ "GenMsgCycleTime" BO_ 2633754622 10000;
BA_ "GenMsgSendType" BO_ 2633754622 0;
BA_ "GenMsgDelayTime" BO_ 2633754622 1000;
BA_ "GenMsgCycleTime" BO_ 2365318910 1000;
BA_ "GenMsgSendType" BO_ 2365318910 0;
BA_ "GenMsgCycleTime" BO_ 2566645246 1000;
BA_ "GenMsgSendType" BO_ 2566645246 0;
BA_ "GenMsgCycleTime" BO_ 2566644990 500;
BA_ "GenMsgSendType" BO_ 2566644990 0;
BA_ "GenMsgCycleTime" BO_ 2633753598 1000;
BA_ "GenMsgSendType" BO_ 2633753598 0;
BA_ "GenMsgCycleTime" BO_ 2633753342 1000;
BA_ "GenMsgSendType" BO_ 2633753342 0;
BA_ "GenMsgCycleTime" BO_ 2633753086 1000;
BA_ "GenMsgSendType" BO_ 2633753086 0;
BA_ "GenMsgCycleTime" BO_ 2633752830 1000;
BA_ "GenMsgSendType" BO_ 2633752830 0;
BA_ "GenMsgCycleTime" BO_ 2566643710 500;
BA_ "GenMsgSendType" BO_ 2566643710 0;
BA_ "GenMsgCycleTime" BO_ 2566643454 1000;
BA_ "GenMsgSendType" BO_ 2566643454 0;
BA_ "GenMsgCycleTime" BO_ 2566643198 1000;
BA_ "GenMsgSendType" BO_ 2566643198 0;
BA_ "GenMsgDelayTime" BO_ 2566643198 100;
BA_ "GenMsgCycleTime" BO_ 2566642942 1000;
BA_ "GenMsgSendType" BO_ 2566642942 0;
BA_ "GenMsgDelayTime" BO_ 2566642942 100;
BA_ "GenMsgCycleTime" BO_ 2365315838 1000;
BA_ "GenMsgSendType" BO_ 2365315838 0;
BA_ "GenMsgCycleTime" BO_ 2365315582 1000;
BA_ "GenMsgSendType" BO_ 2365315582 0;
BA_ "GenMsgCycleTime" BO_ 2365315326 1000;
BA_ "GenMsgSendType" BO_ 2365315326 0;
BA_ "GenMsgCycleTime" BO_ 2566641406 100;
BA_ "GenMsgSendType" BO_ 2566641406 0;
BA_ "GenMsgCycleTime" BO_ 2566641150 1000;
BA_ "GenMsgSendType" BO_ 2566641150 0;
BA_ "GenMsgCycleTime" BO_ 2431719166 50;
BA_ "GenMsgSendType" BO_ 2431719166 0;
BA_ "GenMsgCycleTime" BO_ 2364610046 100;
BA_ "GenMsgSendType" BO_ 2364610046 0;
BA_ "GenMsgCycleTime" BO_ 2364609790 100;
BA_ "GenMsgSendType" BO_ 2364609790 0;
BA_ "GenMsgCycleTime" BO_ 2364609534 100;
BA_ "GenMsgSendType" BO_ 2364609534 0;
BA_ "GenMsgCycleTime" BO_ 2364609278 100;
BA_ "GenMsgSendType" BO_ 2364609278 0;
BA_ "GenMsgCycleTime" BO_ 2431717886 100;
BA_ "GenMsgSendType" BO_ 2431717886 0;
BA_ "GenMsgCycleTime" BO_ 2297499902 1000;
BA_ "GenMsgSendType" BO_ 2297499902 0;
BA_ "GenMsgDelayTime" BO_ 2297499902 20;
BA_ "GenMsgCycleTime" BO_ 2364608510 100;
BA_ "GenMsgSendType" BO_ 2364608510 0;
BA_ "GenMsgDelayTime" BO_ 2364608510 10;
BA_ "GenMsgCycleTime" BO_ 2498825982 50;
BA_ "GenMsgSendType" BO_ 2498825982 0;
BA_ "GenMsgCycleTime" BO_ 2565934590 100;
BA_ "GenMsgSendType" BO_ 2565934590 0;
BA_ "GenMsgCycleTime" BO_ 2364607742 100;
BA_ "GenMsgSendType" BO_ 2364607742 0;
BA_ "GenMsgCycleTime" BO_ 2364607486 100;
BA_ "GenMsgSendType" BO_ 2364607486 0;
BA_ "GenMsgCycleTime" BO_ 2364607230 100;
BA_ "GenMsgSendType" BO_ 2364607230 0;
BA_ "GenMsgCycleTime" BO_ 2364606974 100;
BA_ "GenMsgSendType" BO_ 2364606974 0;
BA_ "GenMsgCycleTime" BO_ 2364606718 100;
BA_ "GenMsgSendType" BO_ 2364606718 0;
BA_ "GenMsgCycleTime" BO_ 2565933054 50;
BA_ "GenMsgSendType" BO_ 2565933054 0;
BA_ "GenMsgCycleTime" BO_ 2565932798 50;
BA_ "GenMsgSendType" BO_ 2565932798 0;
BA_ "GenMsgCycleTime" BO_ 2364605950 20;
BA_ "GenMsgSendType" BO_ 2364605950 0;
BA_ "GenMsgCycleTime" BO_ 2364605438 100;
BA_ "GenMsgSendType" BO_ 2364605438 0;
BA_ "GenMsgCycleTime" BO_ 2364605182 100;
BA_ "GenMsgSendType" BO_ 2364605182 0;
BA_ "GenMsgCycleTime" BO_ 2364604926 100;
BA_ "GenMsgSendType" BO_ 2364604926 0;
BA_ "GenMsgCycleTime" BO_ 2364604670 100;
BA_ "GenMsgSendType" BO_ 2364604670 0;
BA_ "GenMsgCycleTime" BO_ 2364604414 100;
BA_ "GenMsgSendType" BO_ 2364604414 0;
BA_ "GenMsgCycleTime" BO_ 2364604158 50;
BA_ "GenMsgSendType" BO_ 2364604158 0;
BA_ "GenMsgCycleTime" BO_ 2364603902 50;
BA_ "GenMsgSendType" BO_ 2364603902 0;
BA_ "GenMsgCycleTime" BO_ 2364603646 50;
BA_ "GenMsgSendType" BO_ 2364603646 0;
BA_ "GenMsgCycleTime" BO_ 2364603390 50;
BA_ "GenMsgSendType" BO_ 2364603390 0;
BA_ "GenMsgCycleTime" BO_ 2364603134 100;
BA_ "GenMsgSendType" BO_ 2364603134 0;
BA_ "GenMsgCycleTime" BO_ 2364602878 100;
BA_ "GenMsgSendType" BO_ 2364602878 0;
BA_ "GenMsgCycleTime" BO_ 2565923838 100;
BA_ "GenMsgSendType" BO_ 2565923838 0;
BA_ "GenMsgCycleTime" BO_ 2565923582 100;
BA_ "GenMsgSendType" BO_ 2565923582 0;
BA_ "GenMsgCycleTime" BO_ 2565922814 100;
BA_ "GenMsgSendType" BO_ 2565922814 0;
BA_ "GenMsgCycleTime" BO_ 2565922558 100;
BA_ "GenMsgSendType" BO_ 2565922558 0;
BA_ "GenMsgCycleTime" BO_ 2565921790 100;
BA_ "GenMsgSendType" BO_ 2565921790 0;
BA_ "GenMsgCycleTime" BO_ 2565921534 100;
BA_ "GenMsgSendType" BO_ 2565921534 0;
BA_ "GenMsgCycleTime" BO_ 2565920766 100;
BA_ "GenMsgSendType" BO_ 2565920766 0;
BA_ "GenMsgCycleTime" BO_ 2565920510 100;
BA_ "GenMsgSendType" BO_ 2565920510 0;
BA_ "GenMsgCycleTime" BO_ 2364580094 100;
BA_ "GenMsgSendType" BO_ 2364580094 0;
BA_ "SPN" SG_ 2566647550 NFBin2Count 8178;
BA_ "SPN" SG_ 2566647550 NFBin1Count 8177;
BA_ "SPN" SG_ 2566647550 NFBins1And2IdNum 8176;
BA_ "SigType" SG_ 2566647550 NFBins1And2IdNum 1;
BA_ "SPN" SG_ 2566647294 FBin6Count 8175;
BA_ "SPN" SG_ 2566647294 FBin5Count 8174;
BA_ "SPN" SG_ 2566647294 FBins5And6IdNum 8173;
BA_ "SigType" SG_ 2566647294 FBins5And6IdNum 1;
BA_ "SPN" SG_ 2566647038 FBin4Count 8172;
BA_ "SPN" SG_ 2566647038 FBin3Count 8171;
BA_ "SPN" SG_ 2566647038 FBins3And4IdNum 8170;
BA_ "SigType" SG_ 2566647038 FBins3And4IdNum 1;
BA_ "SPN" SG_ 2566646782 FBin2Count 8169;
BA_ "SPN" SG_ 2566646782 FBin1Count 8168;
BA_ "SPN" SG_ 2566646782 FBins1And2IdNum 8167;
BA_ "SigType" SG_ 2566646782 FBins1And2IdNum 1;
BA_ "SPN" SG_ 2633755390 MACAddressOctet6 8287;
BA_ "SPN" SG_ 2633755390 MACAddressOctet5 8286;
BA_ "SPN" SG_ 2633755390 MACAddressOctet4 8285;
BA_ "SPN" SG_ 2633755390 MACAddressOctet3 8284;
BA_ "SPN" SG_ 2633755390 MACAddressOctet2 8283;
BA_ "SPN" SG_ 2633755390 MACAddressOctet1 8282;
BA_ "SPN" SG_ 2633755390 DefaultGatewayOctet4 8281;
BA_ "SPN" SG_ 2633755390 DefaultGatewayOctet3 8280;
BA_ "SPN" SG_ 2633755390 DefaultGatewayOctet2 8279;
BA_ "SPN" SG_ 2633755390 DefaultGatewayOctet1 8278;
BA_ "SPN" SG_ 2633755390 SubnetMaskOctet4 8277;
BA_ "SPN" SG_ 2633755390 SubnetMaskOctet3 8276;
BA_ "SPN" SG_ 2633755390 SubnetMaskOctet2 8275;
BA_ "SPN" SG_ 2633755390 SubnetMaskOctet1 8274;
BA_ "SPN" SG_ 2633755390 IPv4AddressOctet4 8273;
BA_ "SPN" SG_ 2633755390 IPv4AddressOctet3 8272;
BA_ "SPN" SG_ 2633755390 IPv4AddressOctet2 8271;
BA_ "SPN" SG_ 2633755390 IPv4AddressOctet1 8270;
BA_ "SPN" SG_ 2633755390 LinkStatus 8269;
BA_ "SigType" SG_ 2633755390 LinkStatus 5;
BA_ "SPN" SG_ 2633755390 DHCPStatus 8268;
BA_ "SPN" SG_ 2633755134 HostName 8288;
BA_ "SPN" SG_ 2633754878 TotalDEFUsed 8326;
BA_ "SigType" SG_ 2633754878 TotalDEFUsed 1;
BA_ "SPN" SG_ 2633754622 EmergOvrdTotalActivationTime 9179;
BA_ "SigType" SG_ 2633754622 EmergOvrdTotalActivationTime 1;
BA_ "SPN" SG_ 2633754622 AFT1SCRInHiTempTime 8327;
BA_ "SigType" SG_ 2633754622 AFT1SCRInHiTempTime 1;
BA_ "SPN" SG_ 2365318910 HVESFanInstance15 8402;
BA_ "SPN" SG_ 2365318910 HVESFanInstance14 8401;
BA_ "SPN" SG_ 2365318910 HVESFanInstance13 8400;
BA_ "SPN" SG_ 2365318910 HVESFanInstance12 8399;
BA_ "SPN" SG_ 2365318910 HVESFanInstance11 8398;
BA_ "SPN" SG_ 2365318910 HVESFanInstance10 8397;
BA_ "SPN" SG_ 2365318910 HVESFanInstance9 8396;
BA_ "SPN" SG_ 2365318910 HVESFanInstance8 8395;
BA_ "SPN" SG_ 2365318910 HVESFanInstance7 8394;
BA_ "SPN" SG_ 2365318910 HVESFanInstance6 8393;
BA_ "SPN" SG_ 2365318910 HVESFanInstance5 8392;
BA_ "SPN" SG_ 2365318910 HVESFanInstance4 8391;
BA_ "SPN" SG_ 2365318910 HVESFanInstance3 8390;
BA_ "SPN" SG_ 2365318910 HVESFanInstance2 8389;
BA_ "SPN" SG_ 2365318910 HVESFanInstance1 8388;
BA_ "SPN" SG_ 2365318910 HVESFanPercentSpdCmd 8387;
BA_ "SigType" SG_ 2365318910 HVESFanPercentSpdCmd 1;
BA_ "SPN" SG_ 2365318910 HVESFanSpdCmd 8386;
BA_ "SigType" SG_ 2365318910 HVESFanSpdCmd 1;
BA_ "SPN" SG_ 2365318910 HVESFanPwrHold 8385;
BA_ "SigType" SG_ 2365318910 HVESFanPwrHold 5;
BA_ "SPN" SG_ 2365318910 HVESFanEnableCmd 8384;
BA_ "SigType" SG_ 2365318910 HVESFanEnableCmd 5;
BA_ "SPN" SG_ 2566645246 HVESFanInstance 8411;
BA_ "SPN" SG_ 2566645246 HVESFanOperatingStatus 8410;
BA_ "SigType" SG_ 2566645246 HVESFanOperatingStatus 4;
BA_ "SPN" SG_ 2566645246 HVESFanServiceInd 8409;
BA_ "SigType" SG_ 2566645246 HVESFanServiceInd 4;
BA_ "SPN" SG_ 2566645246 HVESFanPwr 8408;
BA_ "SigType" SG_ 2566645246 HVESFanPwr 1;
BA_ "SPN" SG_ 2566645246 HVESFanMediumTemp 8407;
BA_ "SigType" SG_ 2566645246 HVESFanMediumTemp 1;
BA_ "SPN" SG_ 2566645246 HVESFanSpd 8406;
BA_ "SigType" SG_ 2566645246 HVESFanSpd 1;
BA_ "SPN" SG_ 2566645246 HVESFanCmdStatus 8405;
BA_ "SigType" SG_ 2566645246 HVESFanCmdStatus 4;
BA_ "SPN" SG_ 2566645246 HVESFanStatusReasonCode 8404;
BA_ "SPN" SG_ 2566645246 HVESFanEnableStatus 8403;
BA_ "SigType" SG_ 2566645246 HVESFanEnableStatus 5;
BA_ "SPN" SG_ 2566644990 StorageCompartment3Temp2 8425;
BA_ "SigType" SG_ 2566644990 StorageCompartment3Temp2 1;
BA_ "SPN" SG_ 2566644990 StorageCompartment3Temp1 8424;
BA_ "SigType" SG_ 2566644990 StorageCompartment3Temp1 1;
BA_ "SPN" SG_ 2566644990 StorageCompartment2Temp2 8423;
BA_ "SigType" SG_ 2566644990 StorageCompartment2Temp2 1;
BA_ "SPN" SG_ 2566644990 StorageCompartment2Temp1 8422;
BA_ "SigType" SG_ 2566644990 StorageCompartment2Temp1 1;
BA_ "SPN" SG_ 2566644990 StorageCompartment1Temp2 8421;
BA_ "SigType" SG_ 2566644990 StorageCompartment1Temp2 1;
BA_ "SPN" SG_ 2566644990 StorageCompartment1Temp1 8420;
BA_ "SigType" SG_ 2566644990 StorageCompartment1Temp1 1;
BA_ "SPN" SG_ 2566644990 FrontFuelRecpCoverStatus 8419;
BA_ "SigType" SG_ 2566644990 FrontFuelRecpCoverStatus 4;
BA_ "SPN" SG_ 2566644990 PsgrSideFuelRecp2CoverStatus 8418;
BA_ "SigType" SG_ 2566644990 PsgrSideFuelRecp2CoverStatus 4;
BA_ "SPN" SG_ 2566644990 PsgrSideFuelRecp1CoverStatus 8417;
BA_ "SigType" SG_ 2566644990 PsgrSideFuelRecp1CoverStatus 4;
BA_ "SPN" SG_ 2566644990 DriverSideFuelRecp2CoverStatus 8416;
BA_ "SigType" SG_ 2566644990 DriverSideFuelRecp2CoverStatus 4;
BA_ "SPN" SG_ 2566644990 DriverSideFuelRecp1CoverStatus 8415;
BA_ "SigType" SG_ 2566644990 DriverSideFuelRecp1CoverStatus 4;
BA_ "SPN" SG_ 2633753598 ACAirOutTemp 8450;
BA_ "SigType" SG_ 2633753598 ACAirOutTemp 1;
BA_ "SPN" SG_ 2633753598 ACAirInTemp 8449;
BA_ "SigType" SG_ 2633753598 ACAirInTemp 1;
BA_ "SPN" SG_ 2633753598 EngAltWinding12Temp 8448;
BA_ "SigType" SG_ 2633753598 EngAltWinding12Temp 1;
BA_ "SPN" SG_ 2633753598 EngAltWinding11Temp 8447;
BA_ "SigType" SG_ 2633753598 EngAltWinding11Temp 1;
BA_ "SPN" SG_ 2633753598 EngAltWinding10Temp 8446;
BA_ "SigType" SG_ 2633753598 EngAltWinding10Temp 1;
BA_ "SPN" SG_ 2633753598 EngAltWinding9Temp 8445;
BA_ "SigType" SG_ 2633753598 EngAltWinding9Temp 1;
BA_ "SPN" SG_ 2633753598 EngAltWinding8Temp 8444;
BA_ "SigType" SG_ 2633753598 EngAltWinding8Temp 1;
BA_ "SPN" SG_ 2633753598 EngAltWinding7Temp 8443;
BA_ "SigType" SG_ 2633753598 EngAltWinding7Temp 1;
BA_ "SPN" SG_ 2633753342 PwrRectifierDiode8Temp 8458;
BA_ "SigType" SG_ 2633753342 PwrRectifierDiode8Temp 1;
BA_ "SPN" SG_ 2633753342 PwrRectifierDiode7Temp 8457;
BA_ "SigType" SG_ 2633753342 PwrRectifierDiode7Temp 1;
BA_ "SPN" SG_ 2633753342 PwrRectifierDiode6Temp 8456;
BA_ "SigType" SG_ 2633753342 PwrRectifierDiode6Temp 1;
BA_ "SPN" SG_ 2633753342 PwrRectifierDiode5Temp 8455;
BA_ "SigType" SG_ 2633753342 PwrRectifierDiode5Temp 1;
BA_ "SPN" SG_ 2633753342 PwrRectifierDiode4Temp 8454;
BA_ "SigType" SG_ 2633753342 PwrRectifierDiode4Temp 1;
BA_ "SPN" SG_ 2633753342 PwrRectifierDiode3Temp 8453;
BA_ "SigType" SG_ 2633753342 PwrRectifierDiode3Temp 1;
BA_ "SPN" SG_ 2633753342 PwrRectifierDiode2Temp 8452;
BA_ "SigType" SG_ 2633753342 PwrRectifierDiode2Temp 1;
BA_ "SPN" SG_ 2633753342 PwrRectifierDiode1Temp 8451;
BA_ "SigType" SG_ 2633753342 PwrRectifierDiode1Temp 1;
BA_ "SPN" SG_ 2633753086 PwrRectifierDiode12Temp 8462;
BA_ "SigType" SG_ 2633753086 PwrRectifierDiode12Temp 1;
BA_ "SPN" SG_ 2633753086 PwrRectifierDiode11Temp 8461;
BA_ "SigType" SG_ 2633753086 PwrRectifierDiode11Temp 1;
BA_ "SPN" SG_ 2633753086 PwrRectifierDiode10Temp 8460;
BA_ "SigType" SG_ 2633753086 PwrRectifierDiode10Temp 1;
BA_ "SPN" SG_ 2633753086 PwrRectifierDiode9Temp 8459;
BA_ "SigType" SG_ 2633753086 PwrRectifierDiode9Temp 1;
BA_ "SPN" SG_ 2633752830 AltAftercoolerCPOutPress 8472;
BA_ "SigType" SG_ 2633752830 AltAftercoolerCPOutPress 1;
BA_ "SPN" SG_ 2633752830 AltAftercoolerCoolantOutTemp 8471;
BA_ "SigType" SG_ 2633752830 AltAftercoolerCoolantOutTemp 1;
BA_ "SPN" SG_ 2633752830 AltAftercoolerCPOutTemp 8470;
BA_ "SigType" SG_ 2633752830 AltAftercoolerCPOutTemp 1;
BA_ "SPN" SG_ 2633752830 EngOilCoolerCoolantOutTemp 728;
BA_ "SigType" SG_ 2633752830 EngOilCoolerCoolantOutTemp 1;
BA_ "SPN" SG_ 2633752830 AltOilCoolerCoolantOutTemp 8469;
BA_ "SigType" SG_ 2633752830 AltOilCoolerCoolantOutTemp 1;
BA_ "SPN" SG_ 2633752830 AltOilCoolerCoolantInTemp 8468;
BA_ "SigType" SG_ 2633752830 AltOilCoolerCoolantInTemp 1;
BA_ "SPN" SG_ 2633752830 AltOilCoolerOilOutTemp 8467;
BA_ "SigType" SG_ 2633752830 AltOilCoolerOilOutTemp 1;
BA_ "SPN" SG_ 2633752830 AltOilCoolerOilInTemp 8466;
BA_ "SigType" SG_ 2633752830 AltOilCoolerOilInTemp 1;
BA_ "SPN" SG_ 2566643710 EngMixer2InPress 8607;
BA_ "SigType" SG_ 2566643710 EngMixer2InPress 1;
BA_ "SPN" SG_ 2566643710 EngMixer1InPress 8477;
BA_ "SigType" SG_ 2566643710 EngMixer1InPress 1;
BA_ "SPN" SG_ 2566643454 InCoolantTemp 8489;
BA_ "SigType" SG_ 2566643454 InCoolantTemp 1;
BA_ "SPN" SG_ 2566643454 ChargeACOutCoolantTemp 8488;
BA_ "SigType" SG_ 2566643454 ChargeACOutCoolantTemp 1;
BA_ "SPN" SG_ 2566643454 ChargeACInCoolantTemp 8487;
BA_ "SigType" SG_ 2566643454 ChargeACInCoolantTemp 1;
BA_ "SPN" SG_ 2566643198 EnableStatusOfDoor20 8524;
BA_ "SigType" SG_ 2566643198 EnableStatusOfDoor20 5;
BA_ "SPN" SG_ 2566643198 OpenStatusOfDoor20 8523;
BA_ "SigType" SG_ 2566643198 OpenStatusOfDoor20 5;
BA_ "SPN" SG_ 2566643198 LockStatusOfDoor20 8522;
BA_ "SigType" SG_ 2566643198 LockStatusOfDoor20 5;
BA_ "SPN" SG_ 2566643198 EnableStatusOfDoor19 8521;
BA_ "SigType" SG_ 2566643198 EnableStatusOfDoor19 5;
BA_ "SPN" SG_ 2566643198 OpenStatusOfDoor19 8520;
BA_ "SigType" SG_ 2566643198 OpenStatusOfDoor19 5;
BA_ "SPN" SG_ 2566643198 LockStatusOfDoor19 8519;
BA_ "SigType" SG_ 2566643198 LockStatusOfDoor19 5;
BA_ "SPN" SG_ 2566643198 EnableStatusOfDoor18 8518;
BA_ "SigType" SG_ 2566643198 EnableStatusOfDoor18 5;
BA_ "SPN" SG_ 2566643198 OpenStatusOfDoor18 8517;
BA_ "SigType" SG_ 2566643198 OpenStatusOfDoor18 5;
BA_ "SPN" SG_ 2566643198 LockStatusOfDoor18 8516;
BA_ "SigType" SG_ 2566643198 LockStatusOfDoor18 5;
BA_ "SPN" SG_ 2566643198 EnableStatusOfDoor17 8515;
BA_ "SigType" SG_ 2566643198 EnableStatusOfDoor17 5;
BA_ "SPN" SG_ 2566643198 OpenStatusOfDoor17 8514;
BA_ "SigType" SG_ 2566643198 OpenStatusOfDoor17 5;
BA_ "SPN" SG_ 2566643198 LockStatusOfDoor17 8513;
BA_ "SigType" SG_ 2566643198 LockStatusOfDoor17 5;
BA_ "SPN" SG_ 2566643198 EnableStatusOfDoor16 8512;
BA_ "SigType" SG_ 2566643198 EnableStatusOfDoor16 5;
BA_ "SPN" SG_ 2566643198 OpenStatusOfDoor16 8511;
BA_ "SigType" SG_ 2566643198 OpenStatusOfDoor16 5;
BA_ "SPN" SG_ 2566643198 LockStatusOfDoor16 8510;
BA_ "SigType" SG_ 2566643198 LockStatusOfDoor16 5;
BA_ "SPN" SG_ 2566643198 EnableStatusOfDoor15 8509;
BA_ "SigType" SG_ 2566643198 EnableStatusOfDoor15 5;
BA_ "SPN" SG_ 2566643198 OpenStatusOfDoor15 8508;
BA_ "SigType" SG_ 2566643198 OpenStatusOfDoor15 5;
BA_ "SPN" SG_ 2566643198 LockStatusOfDoor15 8507;
BA_ "SigType" SG_ 2566643198 LockStatusOfDoor15 5;
BA_ "SPN" SG_ 2566643198 EnableStatusOfDoor14 8506;
BA_ "SigType" SG_ 2566643198 EnableStatusOfDoor14 5;
BA_ "SPN" SG_ 2566643198 OpenStatusOfDoor14 8505;
BA_ "SigType" SG_ 2566643198 OpenStatusOfDoor14 5;
BA_ "SPN" SG_ 2566643198 LockStatusOfDoor14 8504;
BA_ "SigType" SG_ 2566643198 LockStatusOfDoor14 5;
BA_ "SPN" SG_ 2566643198 EnableStatusOfDoor13 8503;
BA_ "SigType" SG_ 2566643198 EnableStatusOfDoor13 5;
BA_ "SPN" SG_ 2566643198 OpenStatusOfDoor13 8502;
BA_ "SigType" SG_ 2566643198 OpenStatusOfDoor13 5;
BA_ "SPN" SG_ 2566643198 LockStatusOfDoor13 8501;
BA_ "SigType" SG_ 2566643198 LockStatusOfDoor13 5;
BA_ "SPN" SG_ 2566643198 EnableStatusOfDoor12 8500;
BA_ "SigType" SG_ 2566643198 EnableStatusOfDoor12 5;
BA_ "SPN" SG_ 2566643198 OpenStatusOfDoor12 8499;
BA_ "SigType" SG_ 2566643198 OpenStatusOfDoor12 5;
BA_ "SPN" SG_ 2566643198 LockStatusOfDoor12 8498;
BA_ "SigType" SG_ 2566643198 LockStatusOfDoor12 5;
BA_ "SPN" SG_ 2566643198 EnableStatusOfDoor11 8497;
BA_ "SigType" SG_ 2566643198 EnableStatusOfDoor11 5;
BA_ "SPN" SG_ 2566643198 OpenStatusOfDoor11 8496;
BA_ "SigType" SG_ 2566643198 OpenStatusOfDoor11 5;
BA_ "SPN" SG_ 2566643198 LockStatusOfDoor11 8495;
BA_ "SigType" SG_ 2566643198 LockStatusOfDoor11 5;
BA_ "SPN" SG_ 2566642942 EnableStatusOfDoor30 8554;
BA_ "SigType" SG_ 2566642942 EnableStatusOfDoor30 5;
BA_ "SPN" SG_ 2566642942 OpenStatusOfDoor30 8553;
BA_ "SigType" SG_ 2566642942 OpenStatusOfDoor30 5;
BA_ "SPN" SG_ 2566642942 LockStatusOfDoor30 8552;
BA_ "SigType" SG_ 2566642942 LockStatusOfDoor30 5;
BA_ "SPN" SG_ 2566642942 EnableStatusOfDoor29 8551;
BA_ "SigType" SG_ 2566642942 EnableStatusOfDoor29 5;
BA_ "SPN" SG_ 2566642942 OpenStatusOfDoor29 8550;
BA_ "SigType" SG_ 2566642942 OpenStatusOfDoor29 5;
BA_ "SPN" SG_ 2566642942 LockStatusOfDoor29 8549;
BA_ "SigType" SG_ 2566642942 LockStatusOfDoor29 5;
BA_ "SPN" SG_ 2566642942 EnableStatusOfDoor28 8548;
BA_ "SigType" SG_ 2566642942 EnableStatusOfDoor28 5;
BA_ "SPN" SG_ 2566642942 OpenStatusOfDoor28 8547;
BA_ "SigType" SG_ 2566642942 OpenStatusOfDoor28 5;
BA_ "SPN" SG_ 2566642942 LockStatusOfDoor28 8546;
BA_ "SigType" SG_ 2566642942 LockStatusOfDoor28 5;
BA_ "SPN" SG_ 2566642942 EnableStatusOfDoor27 8545;
BA_ "SigType" SG_ 2566642942 EnableStatusOfDoor27 5;
BA_ "SPN" SG_ 2566642942 OpenStatusOfDoor27 8544;
BA_ "SigType" SG_ 2566642942 OpenStatusOfDoor27 5;
BA_ "SPN" SG_ 2566642942 LockStatusOfDoor27 8543;
BA_ "SigType" SG_ 2566642942 LockStatusOfDoor27 5;
BA_ "SPN" SG_ 2566642942 EnableStatusOfDoor26 8542;
BA_ "SigType" SG_ 2566642942 EnableStatusOfDoor26 5;
BA_ "SPN" SG_ 2566642942 OpenStatusOfDoor26 8541;
BA_ "SigType" SG_ 2566642942 OpenStatusOfDoor26 5;
BA_ "SPN" SG_ 2566642942 LockStatusOfDoor26 8540;
BA_ "SigType" SG_ 2566642942 LockStatusOfDoor26 5;
BA_ "SPN" SG_ 2566642942 EnableStatusOfDoor25 8539;
BA_ "SigType" SG_ 2566642942 EnableStatusOfDoor25 5;
BA_ "SPN" SG_ 2566642942 OpenStatusOfDoor25 8538;
BA_ "SigType" SG_ 2566642942 OpenStatusOfDoor25 5;
BA_ "SPN" SG_ 2566642942 LockStatusOfDoor25 8537;
BA_ "SigType" SG_ 2566642942 LockStatusOfDoor25 5;
BA_ "SPN" SG_ 2566642942 EnableStatusOfDoor24 8536;
BA_ "SigType" SG_ 2566642942 EnableStatusOfDoor24 5;
BA_ "SPN" SG_ 2566642942 OpenStatusOfDoor24 8535;
BA_ "SigType" SG_ 2566642942 OpenStatusOfDoor24 5;
BA_ "SPN" SG_ 2566642942 LockStatusOfDoor24 8534;
BA_ "SigType" SG_ 2566642942 LockStatusOfDoor24 5;
BA_ "SPN" SG_ 2566642942 EnableStatusOfDoor23 8533;
BA_ "SigType" SG_ 2566642942 EnableStatusOfDoor23 5;
BA_ "SPN" SG_ 2566642942 OpenStatusOfDoor23 8532;
BA_ "SigType" SG_ 2566642942 OpenStatusOfDoor23 5;
BA_ "SPN" SG_ 2566642942 LockStatusOfDoor23 8531;
BA_ "SigType" SG_ 2566642942 LockStatusOfDoor23 5;
BA_ "SPN" SG_ 2566642942 EnableStatusOfDoor22 8530;
BA_ "SigType" SG_ 2566642942 EnableStatusOfDoor22 5;
BA_ "SPN" SG_ 2566642942 OpenStatusOfDoor22 8529;
BA_ "SigType" SG_ 2566642942 OpenStatusOfDoor22 5;
BA_ "SPN" SG_ 2566642942 LockStatusOfDoor22 8528;
BA_ "SigType" SG_ 2566642942 LockStatusOfDoor22 5;
BA_ "SPN" SG_ 2566642942 EnableStatusOfDoor21 8527;
BA_ "SigType" SG_ 2566642942 EnableStatusOfDoor21 5;
BA_ "SPN" SG_ 2566642942 OpenStatusOfDoor21 8526;
BA_ "SigType" SG_ 2566642942 OpenStatusOfDoor21 5;
BA_ "SPN" SG_ 2566642942 LockStatusOfDoor21 8525;
BA_ "SigType" SG_ 2566642942 LockStatusOfDoor21 5;
BA_ "SPN" SG_ 2365315838 HiSideCurMaxLmt 8565;
BA_ "SigType" SG_ 2365315838 HiSideCurMaxLmt 1;
BA_ "SPN" SG_ 2365315838 HiSideVMaxLmt 8564;
BA_ "SigType" SG_ 2365315838 HiSideVMaxLmt 1;
BA_ "SPN" SG_ 2365315838 HiSideVMinLmt 8563;
BA_ "SigType" SG_ 2365315838 HiSideVMinLmt 1;
BA_ "SPN" SG_ 2365315582 LowSideCurMaxLmt 8568;
BA_ "SigType" SG_ 2365315582 LowSideCurMaxLmt 1;
BA_ "SPN" SG_ 2365315582 LowSideVMaxLmt 8567;
BA_ "SigType" SG_ 2365315582 LowSideVMaxLmt 1;
BA_ "SPN" SG_ 2365315582 LowSideVMinLmt 8566;
BA_ "SigType" SG_ 2365315582 LowSideVMinLmt 1;
BA_ "SPN" SG_ 2365315326 OneCoolantOutTemp 8823;
BA_ "SigType" SG_ 2365315326 OneCoolantOutTemp 1;
BA_ "SPN" SG_ 2365315326 OneCoolantInTemp 8822;
BA_ "SigType" SG_ 2365315326 OneCoolantInTemp 1;
BA_ "SPN" SG_ 2365315326 PwrETemp 8594;
BA_ "SigType" SG_ 2365315326 PwrETemp 1;
BA_ "SPN" SG_ 2365315326 ElectronicFilterTemp 8593;
BA_ "SigType" SG_ 2365315326 ElectronicFilterTemp 1;
BA_ "SPN" SG_ 2365315326 Temp 8592;
BA_ "SigType" SG_ 2365315326 Temp 1;
BA_ "SPN" SG_ 2633750526 PGNModifiedStatus 8605;
BA_ "SigType" SG_ 2633750526 PGNModifiedStatus 5;
BA_ "SPN" SG_ 2633750526 PGNPendingChangeStatus 8604;
BA_ "SigType" SG_ 2633750526 PGNPendingChangeStatus 5;
BA_ "SPN" SG_ 2633750526 PGNCurTransmitStatus 8603;
BA_ "SigType" SG_ 2633750526 PGNCurTransmitStatus 5;
BA_ "SPN" SG_ 2633750526 PGN 8602;
BA_ "SPN" SG_ 2633750526 PortCmdStatus 8601;
BA_ "SPN" SG_ 2633750526 PortPendingChangesStatus 8600;
BA_ "SPN" SG_ 2633750526 Port 8599;
BA_ "SPN" SG_ 2566641406 ExhManifoldPress2 8620;
BA_ "SigType" SG_ 2566641406 ExhManifoldPress2 1;
BA_ "SPN" SG_ 2566641406 ExhManifoldPress1 8619;
BA_ "SigType" SG_ 2566641406 ExhManifoldPress1 1;
BA_ "SPN" SG_ 2566641150 EngOilCoolerInTemp 8638;
BA_ "SigType" SG_ 2566641150 EngOilCoolerInTemp 1;
BA_ "SPN" SG_ 2566641150 EngOilCoolerDisPumpPress 8637;
BA_ "SigType" SG_ 2566641150 EngOilCoolerDisPumpPress 1;
BA_ "SPN" SG_ 2566641150 AltOilCoolerDisPumpPress 8636;
BA_ "SigType" SG_ 2566641150 AltOilCoolerDisPumpPress 1;
BA_ "SPN" SG_ 2566641150 AltBearingHeaderInPress 8635;
BA_ "SigType" SG_ 2566641150 AltBearingHeaderInPress 1;
BA_ "SPN" SG_ 2633749758 RatedSpd 8655;
BA_ "SigType" SG_ 2633749758 RatedSpd 1;
BA_ "SPN" SG_ 2633749758 GearRatio 8654;
BA_ "SigType" SG_ 2633749758 GearRatio 1;
BA_ "SPN" SG_ 2633749758 StrokeLength 8653;
BA_ "SigType" SG_ 2633749758 StrokeLength 1;
BA_ "SPN" SG_ 2633749758 PlungerDiameter 8652;
BA_ "SigType" SG_ 2633749758 PlungerDiameter 1;
BA_ "SPN" SG_ 2633749502 CycleCount 8659;
BA_ "SigType" SG_ 2633749502 CycleCount 1;
BA_ "SPN" SG_ 2633749502 WorkingHours 8658;
BA_ "SigType" SG_ 2633749502 WorkingHours 1;
BA_ "SPN" SG_ 2633749502 PwrEndWorkingHours 8657;
BA_ "SigType" SG_ 2633749502 PwrEndWorkingHours 1;
BA_ "SPN" SG_ 2633749502 FluidEndWorkingHours 8656;
BA_ "SigType" SG_ 2633749502 FluidEndWorkingHours 1;
BA_ "SPN" SG_ 2566640382 WellStimPumpOilTemp 8663;
BA_ "SigType" SG_ 2566640382 WellStimPumpOilTemp 1;
BA_ "SPN" SG_ 2566640382 WellStimPumpOilRelDielectricity 8662;
BA_ "SigType" SG_ 2566640382 WellStimPumpOilRelDielectricity 1;
BA_ "SPN" SG_ 2566640382 WellStimPumpOilDensity 8661;
BA_ "SigType" SG_ 2566640382 WellStimPumpOilDensity 1;
BA_ "SPN" SG_ 2566640382 WellStimPumpOilViscosity 8660;
BA_ "SigType" SG_ 2566640382 WellStimPumpOilViscosity 1;
BA_ "SPN" SG_ 2431719166 FlowRate 8650;
BA_ "SigType" SG_ 2431719166 FlowRate 1;
BA_ "SPN" SG_ 2431719166 FluidEndVlvLeak 8651;
BA_ "SigType" SG_ 2431719166 FluidEndVlvLeak 4;
BA_ "SPN" SG_ 2431719166 CavitationStatus 8649;
BA_ "SPN" SG_ 2431719166 RodLoad 8648;
BA_ "SigType" SG_ 2431719166 RodLoad 1;
BA_ "SPN" SG_ 2364610046 SLIBatTermTemp 8591;
BA_ "SigType" SG_ 2364610046 SLIBatTermTemp 1;
BA_ "SPN" SG_ 2364610046 SLIBatTermCur 8590;
BA_ "SigType" SG_ 2364610046 SLIBatTermCur 1;
BA_ "SPN" SG_ 2364610046 SLIBatTermV 8589;
BA_ "SigType" SG_ 2364610046 SLIBatTermV 1;
BA_ "SPN" SG_ 2364609790 HiSideCur 8588;
BA_ "SigType" SG_ 2364609790 HiSideCur 1;
BA_ "SPN" SG_ 2364609790 HiSideV 8587;
BA_ "SigType" SG_ 2364609790 HiSideV 1;
BA_ "SPN" SG_ 2364609790 LowSideCur 8586;
BA_ "SigType" SG_ 2364609790 LowSideCur 1;
BA_ "SPN" SG_ 2364609790 LowSideV 8585;
BA_ "SigType" SG_ 2364609790 LowSideV 1;
BA_ "SPN" SG_ 2364609534 PLDueToUndefinedReason 8584;
BA_ "SigType" SG_ 2364609534 PLDueToUndefinedReason 4;
BA_ "SPN" SG_ 2364609534 PLDueToSLIBatTermTemp 8582;
BA_ "SigType" SG_ 2364609534 PLDueToSLIBatTermTemp 4;
BA_ "SPN" SG_ 2364609534 PLDueToSLIBatTermCur 8583;
BA_ "SigType" SG_ 2364609534 PLDueToSLIBatTermCur 4;
BA_ "SPN" SG_ 2364609534 PLDueToSLIBatTermV 8581;
BA_ "SigType" SG_ 2364609534 PLDueToSLIBatTermV 4;
BA_ "SPN" SG_ 2364609534 PLDueToPwrETemp 8580;
BA_ "SigType" SG_ 2364609534 PLDueToPwrETemp 4;
BA_ "SPN" SG_ 2364609534 PLDueToElectronicFilterTemp 8579;
BA_ "SigType" SG_ 2364609534 PLDueToElectronicFilterTemp 4;
BA_ "SPN" SG_ 2364609534 PLDueToCtrlTemp 8578;
BA_ "SigType" SG_ 2364609534 PLDueToCtrlTemp 4;
BA_ "SPN" SG_ 2364609534 PLDueToLowSideVMax 8577;
BA_ "SigType" SG_ 2364609534 PLDueToLowSideVMax 4;
BA_ "SPN" SG_ 2364609534 PLDueToLowSideVMin 8576;
BA_ "SigType" SG_ 2364609534 PLDueToLowSideVMin 4;
BA_ "SPN" SG_ 2364609534 PLDueToHiSideVMax 8575;
BA_ "SigType" SG_ 2364609534 PLDueToHiSideVMax 4;
BA_ "SPN" SG_ 2364609534 PLDueToHiSideVMin 8574;
BA_ "SigType" SG_ 2364609534 PLDueToHiSideVMin 4;
BA_ "SPN" SG_ 2364609534 PLDueToLowSideCur 8573;
BA_ "SigType" SG_ 2364609534 PLDueToLowSideCur 4;
BA_ "SPN" SG_ 2364609534 PLDueToHiSideCur 8572;
BA_ "SigType" SG_ 2364609534 PLDueToHiSideCur 4;
BA_ "SPN" SG_ 2364609534 LoadshedReq 8571;
BA_ "SigType" SG_ 2364609534 LoadshedReq 5;
BA_ "SPN" SG_ 2364609534 HVILStatus 8570;
BA_ "SigType" SG_ 2364609534 HVILStatus 4;
BA_ "SPN" SG_ 2364609534 OperationalStatus 8569;
BA_ "SPN" SG_ 2364609278 OneLowSideVBuckDefaultSetpoint 9515;
BA_ "SigType" SG_ 2364609278 OneLowSideVBuckDefaultSetpoint 1;
BA_ "SPN" SG_ 2364609278 HiSideVBoostSetpoint 8562;
BA_ "SigType" SG_ 2364609278 HiSideVBoostSetpoint 1;
BA_ "SPN" SG_ 2364609278 LowSideVBuckSetpoint 8561;
BA_ "SigType" SG_ 2364609278 LowSideVBuckSetpoint 1;
BA_ "SPN" SG_ 2364609278 OperationalCmd 8560;
BA_ "SPN" SG_ 2431717886 EngFuelVlv1DiffPress 8494;
BA_ "SigType" SG_ 2431717886 EngFuelVlv1DiffPress 1;
BA_ "SPN" SG_ 2297499902 BrkPedalSw2 603;
BA_ "SigType" SG_ 2297499902 BrkPedalSw2 4;
BA_ "SPN" SG_ 2297499902 DemandedBrkAppPress 8484;
BA_ "SigType" SG_ 2297499902 DemandedBrkAppPress 1;
BA_ "SPN" SG_ 2364608510 PwrDerateReq 8436;
BA_ "SigType" SG_ 2364608510 PwrDerateReq 1;
BA_ "SPN" SG_ 2364608510 SelfInducedDerateLoad 8435;
BA_ "SigType" SG_ 2364608510 SelfInducedDerateLoad 1;
BA_ "SPN" SG_ 2498825982 BodyEjectorBladePos 8315;
BA_ "SigType" SG_ 2498825982 BodyEjectorBladePos 1;
BA_ "SPN" SG_ 2498825982 BodyRaisePosRelToRecommendedMax 8314;
BA_ "SigType" SG_ 2498825982 BodyRaisePosRelToRecommendedMax 1;
BA_ "SPN" SG_ 2498825982 BodyRaiseAngle 8313;
BA_ "SigType" SG_ 2498825982 BodyRaiseAngle 1;
BA_ "SPN" SG_ 2498825982 BodyRollAngle 8312;
BA_ "SigType" SG_ 2498825982 BodyRollAngle 1;
BA_ "SPN" SG_ 2565934590 EngFuelVlv2DiffPress 6885;
BA_ "SigType" SG_ 2565934590 EngFuelVlv2DiffPress 1;
BA_ "SPN" SG_ 2364607742 HVBusPassiveIsolTestResults 8432;
BA_ "SigType" SG_ 2364607742 HVBusPassiveIsolTestResults 1;
BA_ "SPN" SG_ 2364607742 HVBusActiveIsolTestResults 8431;
BA_ "SigType" SG_ 2364607742 HVBusActiveIsolTestResults 1;
BA_ "SPN" SG_ 2364607742 LowestCellStOfChargeCellNum 8248;
BA_ "SigType" SG_ 2364607742 LowestCellStOfChargeCellNum 1;
BA_ "SPN" SG_ 2364607742 LowestCellStOfChargeModuleNum 8247;
BA_ "SigType" SG_ 2364607742 LowestCellStOfChargeModuleNum 1;
BA_ "SPN" SG_ 2364607742 HighestCellStOfChargeCellNum 8246;
BA_ "SigType" SG_ 2364607742 HighestCellStOfChargeCellNum 1;
BA_ "SPN" SG_ 2364607742 HighestCellStOfChargeModuleNum 8245;
BA_ "SigType" SG_ 2364607742 HighestCellStOfChargeModuleNum 1;
BA_ "SPN" SG_ 2364607486 LowestCellTempCellNum 8244;
BA_ "SigType" SG_ 2364607486 LowestCellTempCellNum 1;
BA_ "SPN" SG_ 2364607486 LowestCellTempModuleNum 8243;
BA_ "SigType" SG_ 2364607486 LowestCellTempModuleNum 1;
BA_ "SPN" SG_ 2364607486 HighestCellTempCellNum 8242;
BA_ "SigType" SG_ 2364607486 HighestCellTempCellNum 1;
BA_ "SPN" SG_ 2364607486 HighestCellTempModuleNum 8241;
BA_ "SigType" SG_ 2364607486 HighestCellTempModuleNum 1;
BA_ "SPN" SG_ 2364607230 AvgCellV 8240;
BA_ "SigType" SG_ 2364607230 AvgCellV 1;
BA_ "SPN" SG_ 2364607230 LowestCellVCellNum 8239;
BA_ "SigType" SG_ 2364607230 LowestCellVCellNum 1;
BA_ "SPN" SG_ 2364607230 LowestCellVModuleNum 8238;
BA_ "SigType" SG_ 2364607230 LowestCellVModuleNum 1;
BA_ "SPN" SG_ 2364607230 HighestCellVCellNum 8237;
BA_ "SigType" SG_ 2364607230 HighestCellVCellNum 1;
BA_ "SPN" SG_ 2364607230 HighestCellVModuleNum 8236;
BA_ "SigType" SG_ 2364607230 HighestCellVModuleNum 1;
BA_ "SPN" SG_ 2364606974 TMSMode 8235;
BA_ "SPN" SG_ 2364606974 TMSHtrStatus 8234;
BA_ "SigType" SG_ 2364606974 TMSHtrStatus 5;
BA_ "SPN" SG_ 2364606974 TMSRelHumidty 8233;
BA_ "SigType" SG_ 2364606974 TMSRelHumidty 1;
BA_ "SPN" SG_ 2364606974 TMSCompressorSpd 8232;
BA_ "SigType" SG_ 2364606974 TMSCompressorSpd 1;
BA_ "SPN" SG_ 2364606974 TMSHVInputPwr 8231;
BA_ "SigType" SG_ 2364606974 TMSHVInputPwr 1;
BA_ "SPN" SG_ 2364606974 TMSSLIInputPwr 8230;
BA_ "SigType" SG_ 2364606974 TMSSLIInputPwr 1;
BA_ "SPN" SG_ 2364606718 Module16OperationalStatus 8229;
BA_ "SigType" SG_ 2364606718 Module16OperationalStatus 5;
BA_ "SPN" SG_ 2364606718 Module15OperationalStatus 8228;
BA_ "SigType" SG_ 2364606718 Module15OperationalStatus 5;
BA_ "SPN" SG_ 2364606718 Module14OperationalStatus 8227;
BA_ "SigType" SG_ 2364606718 Module14OperationalStatus 5;
BA_ "SPN" SG_ 2364606718 Module13OperationalStatus 8226;
BA_ "SigType" SG_ 2364606718 Module13OperationalStatus 5;
BA_ "SPN" SG_ 2364606718 Module12OperationalStatus 8225;
BA_ "SigType" SG_ 2364606718 Module12OperationalStatus 5;
BA_ "SPN" SG_ 2364606718 Module11OperationalStatus 8224;
BA_ "SigType" SG_ 2364606718 Module11OperationalStatus 5;
BA_ "SPN" SG_ 2364606718 Module10OperationalStatus 8223;
BA_ "SigType" SG_ 2364606718 Module10OperationalStatus 5;
BA_ "SPN" SG_ 2364606718 Module9OperationalStatus 8222;
BA_ "SigType" SG_ 2364606718 Module9OperationalStatus 5;
BA_ "SPN" SG_ 2364606718 Module8OperationalStatus 8221;
BA_ "SigType" SG_ 2364606718 Module8OperationalStatus 5;
BA_ "SPN" SG_ 2364606718 Module7OperationalStatus 8220;
BA_ "SigType" SG_ 2364606718 Module7OperationalStatus 5;
BA_ "SPN" SG_ 2364606718 Module6OperationalStatus 8219;
BA_ "SigType" SG_ 2364606718 Module6OperationalStatus 5;
BA_ "SPN" SG_ 2364606718 Module5OperationalStatus 8218;
BA_ "SigType" SG_ 2364606718 Module5OperationalStatus 5;
BA_ "SPN" SG_ 2364606718 Module4OperationalStatus 8217;
BA_ "SigType" SG_ 2364606718 Module4OperationalStatus 5;
BA_ "SPN" SG_ 2364606718 Module3OperationalStatus 8216;
BA_ "SigType" SG_ 2364606718 Module3OperationalStatus 5;
BA_ "SPN" SG_ 2364606718 Module2OperationalStatus 8215;
BA_ "SigType" SG_ 2364606718 Module2OperationalStatus 5;
BA_ "SPN" SG_ 2364606718 Module1OperationalStatus 8214;
BA_ "SigType" SG_ 2364606718 Module1OperationalStatus 5;
BA_ "SPN" SG_ 2565933054 Spd 8158;
BA_ "SigType" SG_ 2565933054 Spd 1;
BA_ "SPN" SG_ 2565933054 GearBoxOilTemp 8157;
BA_ "SigType" SG_ 2565933054 GearBoxOilTemp 1;
BA_ "SPN" SG_ 2565933054 GearBoxOilPress 8156;
BA_ "SigType" SG_ 2565933054 GearBoxOilPress 1;
BA_ "SPN" SG_ 2565932798 DisPress 8155;
BA_ "SigType" SG_ 2565932798 DisPress 1;
BA_ "SPN" SG_ 2565932798 SuctionPress 8154;
BA_ "SigType" SG_ 2565932798 SuctionPress 1;
BA_ "SPN" SG_ 2364605950 MechMovementAngle 7940;
BA_ "SigType" SG_ 2364605950 MechMovementAngle 1;
BA_ "SPN" SG_ 2364605950 LinePress 7939;
BA_ "SigType" SG_ 2364605950 LinePress 1;
BA_ "SPN" SG_ 2565932286 Vour 7846;
BA_ "SigType" SG_ 2565932286 Vour 1;
BA_ "SPN" SG_ 2364605438 KVArHoursExport 7832;
BA_ "SigType" SG_ 2364605438 KVArHoursExport 1;
BA_ "SPN" SG_ 2364605438 KWHoursExport 7831;
BA_ "SigType" SG_ 2364605438 KWHoursExport 1;
BA_ "SPN" SG_ 2364605182 PitchSensitivityCmd 7811;
BA_ "SigType" SG_ 2364605182 PitchSensitivityCmd 1;
BA_ "SPN" SG_ 2364605182 PitchCmd 7810;
BA_ "SigType" SG_ 2364605182 PitchCmd 1;
BA_ "SPN" SG_ 2364605182 SensitivityCmd 7809;
BA_ "SigType" SG_ 2364605182 SensitivityCmd 1;
BA_ "SPN" SG_ 2364605182 Cmd 7808;
BA_ "SigType" SG_ 2364605182 Cmd 1;
BA_ "SPN" SG_ 2364604926 PitchExit_ReasonCode 7807;
BA_ "SPN" SG_ 2364604926 PitchLmtSt 7806;
BA_ "SPN" SG_ 2364604926 PitchAngle 7805;
BA_ "SigType" SG_ 2364604926 PitchAngle 1;
BA_ "SPN" SG_ 2364604926 Exit_ReasonCode 7804;
BA_ "SPN" SG_ 2364604926 LmtSt 7803;
BA_ "SPN" SG_ 2364604926 Angle 7802;
BA_ "SigType" SG_ 2364604926 Angle 1;
BA_ "SPN" SG_ 2364604670 PitchSensitivityCmd 7799;
BA_ "SigType" SG_ 2364604670 PitchSensitivityCmd 1;
BA_ "SPN" SG_ 2364604670 PitchCmd 7798;
BA_ "SigType" SG_ 2364604670 PitchCmd 1;
BA_ "SPN" SG_ 2364604670 SensitivityCmd 7797;
BA_ "SigType" SG_ 2364604670 SensitivityCmd 1;
BA_ "SPN" SG_ 2364604670 Cmd 7796;
BA_ "SigType" SG_ 2364604670 Cmd 1;
BA_ "SPN" SG_ 2364604414 PitchExit_ReasonCode 7795;
BA_ "SPN" SG_ 2364604414 PitchLmtSt 7794;
BA_ "SPN" SG_ 2364604414 PitchAngle 7793;
BA_ "SigType" SG_ 2364604414 PitchAngle 1;
BA_ "SPN" SG_ 2364604414 Exit_ReasonCode 7792;
BA_ "SPN" SG_ 2364604414 LmtSt 7791;
BA_ "SPN" SG_ 2364604414 Angle 7790;
BA_ "SigType" SG_ 2364604414 Angle 1;
BA_ "SPN" SG_ 2364604158 DEFActualQuantityOfIntegrator 7787;
BA_ "SigType" SG_ 2364604158 DEFActualQuantityOfIntegrator 1;
BA_ "SPN" SG_ 2364603902 DEFActualQuantityOfIntegrator 7786;
BA_ "SigType" SG_ 2364603902 DEFActualQuantityOfIntegrator 1;
BA_ "SPN" SG_ 2364603646 DEFReqQuantityOfIntegrator 7784;
BA_ "SigType" SG_ 2364603646 DEFReqQuantityOfIntegrator 1;
BA_ "SPN" SG_ 2364603390 DEFDoserVlv1Cmd 8442;
BA_ "SigType" SG_ 2364603390 DEFDoserVlv1Cmd 1;
BA_ "SPN" SG_ 2364603390 DEFReqQuantityOfIntegrator 7783;
BA_ "SigType" SG_ 2364603390 DEFReqQuantityOfIntegrator 1;
BA_ "SPN" SG_ 2364603134 SAOfActiveOrPendingTransReqGear 8613;
BA_ "SPN" SG_ 2364603134 MaxReverseTransOSS 7780;
BA_ "SigType" SG_ 2364603134 MaxReverseTransOSS 1;
BA_ "SPN" SG_ 2364603134 MaxForwardTransOSS 7779;
BA_ "SigType" SG_ 2364603134 MaxForwardTransOSS 1;
BA_ "SPN" SG_ 2364602878 CtrlModule8PreliminaryFMI 7777;
BA_ "SPN" SG_ 2364602878 CtrlModule7PreliminaryFMI 7776;
BA_ "SPN" SG_ 2364602878 CtrlModule6PreliminaryFMI 7775;
BA_ "SPN" SG_ 2364602878 CtrlModule5PreliminaryFMI 7774;
BA_ "SPN" SG_ 2364602878 CtrlModule4PreliminaryFMI 7773;
BA_ "SPN" SG_ 2364602878 CtrlModule3PreliminaryFMI 7772;
BA_ "SPN" SG_ 2364602878 CtrlModule2PreliminaryFMI 7771;
BA_ "SPN" SG_ 2364602878 CtrlModule1PreliminaryFMI 7770;
BA_ "SPN" SG_ 2565923838 HVILStatus 8854;
BA_ "SigType" SG_ 2565923838 HVILStatus 5;
BA_ "SPN" SG_ 2565923838 ACSideRMSCur 9203;
BA_ "SigType" SG_ 2565923838 ACSideRMSCur 1;
BA_ "SPN" SG_ 2565923838 LoadshedReq 8383;
BA_ "SigType" SG_ 2565923838 LoadshedReq 5;
BA_ "SPN" SG_ 2565923838 StatusFeedback 8382;
BA_ "SPN" SG_ 2565923838 PwrFeedback 8381;
BA_ "SigType" SG_ 2565923838 PwrFeedback 1;
BA_ "SPN" SG_ 2565923838 VFeedback 8380;
BA_ "SigType" SG_ 2565923838 VFeedback 1;
BA_ "SPN" SG_ 2565923838 FreqFeedback 8379;
BA_ "SigType" SG_ 2565923838 FreqFeedback 1;
BA_ "SPN" SG_ 2565923582 ACSideMotorStartingRMSVReq 9546;
BA_ "SigType" SG_ 2565923582 ACSideMotorStartingRMSVReq 1;
BA_ "SPN" SG_ 2565923582 EnableCmd 8378;
BA_ "SigType" SG_ 2565923582 EnableCmd 5;
BA_ "SPN" SG_ 2565923582 Device2Status 8377;
BA_ "SPN" SG_ 2565923582 Device1Status 8376;
BA_ "SPN" SG_ 2565923582 FreqCmd 8375;
BA_ "SigType" SG_ 2565923582 FreqCmd 1;
BA_ "SPN" SG_ 2565923582 DeviceFreqRateOfChangeLmt 8374;
BA_ "SigType" SG_ 2565923582 DeviceFreqRateOfChangeLmt 1;
BA_ "SPN" SG_ 2565923582 DeviceRatedV 8373;
BA_ "SigType" SG_ 2565923582 DeviceRatedV 1;
BA_ "SPN" SG_ 2565923582 DeviceRatedFreq 8372;
BA_ "SigType" SG_ 2565923582 DeviceRatedFreq 1;
BA_ "SPN" SG_ 2565923582 DeviceMinFreq 8371;
BA_ "SigType" SG_ 2565923582 DeviceMinFreq 1;
BA_ "SPN" SG_ 2565923582 DeviceMaxFreq 8370;
BA_ "SigType" SG_ 2565923582 DeviceMaxFreq 1;
BA_ "SPN" SG_ 2565922814 HVILStatus 8853;
BA_ "SigType" SG_ 2565922814 HVILStatus 5;
BA_ "SPN" SG_ 2565922814 ACSideRMSCur 9202;
BA_ "SigType" SG_ 2565922814 ACSideRMSCur 1;
BA_ "SPN" SG_ 2565922814 LoadshedReq 8369;
BA_ "SigType" SG_ 2565922814 LoadshedReq 5;
BA_ "SPN" SG_ 2565922814 StatusFeedback 8368;
BA_ "SPN" SG_ 2565922814 PwrFeedback 8367;
BA_ "SigType" SG_ 2565922814 PwrFeedback 1;
BA_ "SPN" SG_ 2565922814 VFeedback 8366;
BA_ "SigType" SG_ 2565922814 VFeedback 1;
BA_ "SPN" SG_ 2565922814 FreqFeedback 8365;
BA_ "SigType" SG_ 2565922814 FreqFeedback 1;
BA_ "SPN" SG_ 2565922558 ACSideMotorStartingRMSVReq 9540;
BA_ "SigType" SG_ 2565922558 ACSideMotorStartingRMSVReq 1;
BA_ "SPN" SG_ 2565922558 EnableCmd 8364;
BA_ "SigType" SG_ 2565922558 EnableCmd 5;
BA_ "SPN" SG_ 2565922558 Device2Status 8363;
BA_ "SPN" SG_ 2565922558 Device1Status 8362;
BA_ "SPN" SG_ 2565922558 FreqCmd 8361;
BA_ "SigType" SG_ 2565922558 FreqCmd 1;
BA_ "SPN" SG_ 2565922558 DeviceFreqRateOfChangeLmt 8360;
BA_ "SigType" SG_ 2565922558 DeviceFreqRateOfChangeLmt 1;
BA_ "SPN" SG_ 2565922558 DeviceRatedV 8359;
BA_ "SigType" SG_ 2565922558 DeviceRatedV 1;
BA_ "SPN" SG_ 2565922558 DeviceRatedFreq 8358;
BA_ "SigType" SG_ 2565922558 DeviceRatedFreq 1;
BA_ "SPN" SG_ 2565922558 DeviceMinFreq 8357;
BA_ "SigType" SG_ 2565922558 DeviceMinFreq 1;
BA_ "SPN" SG_ 2565922558 DeviceMaxFreq 8356;
BA_ "SigType" SG_ 2565922558 DeviceMaxFreq 1;
BA_ "SPN" SG_ 2565921790 HVILStatus 8852;
BA_ "SigType" SG_ 2565921790 HVILStatus 5;
BA_ "SPN" SG_ 2565921790 ACSideRMSCur 9201;
BA_ "SigType" SG_ 2565921790 ACSideRMSCur 1;
BA_ "SPN" SG_ 2565921790 LoadshedReq 8355;
BA_ "SigType" SG_ 2565921790 LoadshedReq 5;
BA_ "SPN" SG_ 2565921790 StatusFeedback 8354;
BA_ "SPN" SG_ 2565921790 PwrFeedback 8353;
BA_ "SigType" SG_ 2565921790 PwrFeedback 1;
BA_ "SPN" SG_ 2565921790 VFeedback 8352;
BA_ "SigType" SG_ 2565921790 VFeedback 1;
BA_ "SPN" SG_ 2565921790 FreqFeedback 8351;
BA_ "SigType" SG_ 2565921790 FreqFeedback 1;
BA_ "SPN" SG_ 2565921534 ACSideMotorStartingRMSVReq 9534;
BA_ "SigType" SG_ 2565921534 ACSideMotorStartingRMSVReq 1;
BA_ "SPN" SG_ 2565921534 EnableCmd 8350;
BA_ "SigType" SG_ 2565921534 EnableCmd 5;
BA_ "SPN" SG_ 2565921534 Device2Status 8349;
BA_ "SPN" SG_ 2565921534 Device1Status 8348;
BA_ "SPN" SG_ 2565921534 FreqCmd 8347;
BA_ "SigType" SG_ 2565921534 FreqCmd 1;
BA_ "SPN" SG_ 2565921534 DeviceFreqRateOfChangeLmt 8346;
BA_ "SigType" SG_ 2565921534 DeviceFreqRateOfChangeLmt 1;
BA_ "SPN" SG_ 2565921534 DeviceRatedV 8345;
BA_ "SigType" SG_ 2565921534 DeviceRatedV 1;
BA_ "SPN" SG_ 2565921534 DeviceRatedFreq 8344;
BA_ "SigType" SG_ 2565921534 DeviceRatedFreq 1;
BA_ "SPN" SG_ 2565921534 DeviceMinFreq 8343;
BA_ "SigType" SG_ 2565921534 DeviceMinFreq 1;
BA_ "SPN" SG_ 2565921534 DeviceMaxFreq 8342;
BA_ "SigType" SG_ 2565921534 DeviceMaxFreq 1;
BA_ "SPN" SG_ 2565920766 HVILStatus 8851;
BA_ "SigType" SG_ 2565920766 HVILStatus 5;
BA_ "SPN" SG_ 2565920766 ACSideRMSCur 9200;
BA_ "SigType" SG_ 2565920766 ACSideRMSCur 1;
BA_ "SPN" SG_ 2565920766 LoadshedReq 8341;
BA_ "SigType" SG_ 2565920766 LoadshedReq 5;
BA_ "SPN" SG_ 2565920766 StatusFeedback 8340;
BA_ "SPN" SG_ 2565920766 PwrFeedback 8339;
BA_ "SigType" SG_ 2565920766 PwrFeedback 1;
BA_ "SPN" SG_ 2565920766 VFeedback 8338;
BA_ "SigType" SG_ 2565920766 VFeedback 1;
BA_ "SPN" SG_ 2565920766 FreqFeedback 8337;
BA_ "SigType" SG_ 2565920766 FreqFeedback 1;
BA_ "SPN" SG_ 2565920510 ACSideMotorStartingRMSVReq 9528;
BA_ "SigType" SG_ 2565920510 ACSideMotorStartingRMSVReq 1;
BA_ "SPN" SG_ 2565920510 EnableCmd 8336;
BA_ "SigType" SG_ 2565920510 EnableCmd 5;
BA_ "SPN" SG_ 2565920510 Device2Status 8335;
BA_ "SPN" SG_ 2565920510 Device1Status 8334;
BA_ "SPN" SG_ 2565920510 FreqCmd 8333;
BA_ "SigType" SG_ 2565920510 FreqCmd 1;
BA_ "SPN" SG_ 2565920510 DeviceFreqRateOfChangeLmt 8332;
BA_ "SigType" SG_ 2565920510 DeviceFreqRateOfChangeLmt 1;
BA_ "SPN" SG_ 2565920510 DeviceRatedV 8331;
BA_ "SigType" SG_ 2565920510 DeviceRatedV 1;
BA_ "SPN" SG_ 2565920510 DeviceRatedFreq 8330;
BA_ "SigType" SG_ 2565920510 DeviceRatedFreq 1;
BA_ "SPN" SG_ 2565920510 DeviceMinFreq 8329;
BA_ "SigType" SG_ 2565920510 DeviceMinFreq 1;
BA_ "SPN" SG_ 2565920510 DeviceMaxFreq 8328;
BA_ "SigType" SG_ 2565920510 DeviceMaxFreq 1;
BA_ "SPN" SG_ 2364580094 MaxChargeVLmt 8090;
BA_ "SigType" SG_ 2364580094 MaxChargeVLmt 1;
BA_ "SPN" SG_ 2364580094 ChargeEnergyCapacity 8206;
BA_ "SPN" SG_ 2364580094 DisEnergyCapacity 8205;
VAL_ 2633755390 LinkStatus 3 "Not Supported" 2 "Error" 1 "Ethernet Link Up" 0 "Ethernet Link Down" ;
VAL_ 2633755390 DHCPStatus 15 "Not Available" 14 "Error" 13 "SAE Reserved" 12 "SAE Reserved" 11 "SAE Reserved" 10 "SAE Reserved" 9 "SAE Reserved" 8 "SAE Reserved" 7 "SAE Reserved" 6 "SAE Reserved" 5 "SAE Reserved" 4 "SAE Reserved" 3 "Contacting DHCP Server" 2 "IP Leased" 1 "Obtaining IP" 0 "Not Configured" ;
VAL_ 2365318910 HVESFanInstance15 1 "No Command applied to this Fan Instance" 0 "Command applied to this Fan Instance" ;
VAL_ 2365318910 HVESFanInstance14 1 "No Command applied to this Fan Instance" 0 "Command applied to this Fan Instance" ;
VAL_ 2365318910 HVESFanInstance13 1 "No Command applied to this Fan Instance" 0 "Command applied to this Fan Instance" ;
VAL_ 2365318910 HVESFanInstance12 1 "No Command applied to this Fan Instance" 0 "Command applied to this Fan Instance" ;
VAL_ 2365318910 HVESFanInstance11 1 "No Command applied to this Fan Instance" 0 "Command applied to this Fan Instance" ;
VAL_ 2365318910 HVESFanInstance10 1 "No Command applied to this Fan Instance" 0 "Command applied to this Fan Instance" ;
VAL_ 2365318910 HVESFanInstance9 1 "No Command applied to this Fan Instance" 0 "Command applied to this Fan Instance" ;
VAL_ 2365318910 HVESFanInstance8 1 "No Command applied to this Fan Instance" 0 "Command applied to this Fan Instance" ;
VAL_ 2365318910 HVESFanInstance7 1 "No Command applied to this Fan Instance" 0 "Command applied to this Fan Instance" ;
VAL_ 2365318910 HVESFanInstance6 1 "No Command applied to this Fan Instance" 0 "Command applied to this Fan Instance" ;
VAL_ 2365318910 HVESFanInstance5 1 "No Command applied to this Fan Instance" 0 "Command applied to this Fan Instance" ;
VAL_ 2365318910 HVESFanInstance4 1 "No Command applied to this Fan Instance" 0 "Command applied to this Fan Instance" ;
VAL_ 2365318910 HVESFanInstance3 1 "No Command applied to this Fan Instance" 0 "Command applied to this Fan Instance" ;
VAL_ 2365318910 HVESFanInstance2 1 "No Command applied to this Fan Instance" 0 "Command applied to this Fan Instance" ;
VAL_ 2365318910 HVESFanInstance1 1 "No Command applied to this Fan Instance" 0 "Command applied to this Fan Instance" ;
VAL_ 2365318910 HVESFanPwrHold 3 "Don't Care/Take no action" 2 "Reserved" 1 "Power Hold Enabled" 0 "Power Hold Disabled" ;
VAL_ 2365318910 HVESFanEnableCmd 3 "Don't Care/Take no action" 2 "Fan On Reverse Direction" 1 "Fan On Normal/Default Direction" 0 "Fan Off" ;
VAL_ 2566645246 HVESFanInstance 15 "Not available / Instance not specified" 14 "Instance 15" 13 "Instance 14" 12 "Instance 13" 11 "Instance 12" 10 "Instance 11" 9 "Instance 10" 8 "Instance 9" 7 "Instance 8" 6 "Instance 7" 5 "Instance 6" 4 "Instance 5" 3 "Instance 4" 2 "Instance 3" 1 "Instance 2" 0 "Instance 1" ;
VAL_ 2566645246 HVESFanOperatingStatus 3 "Not Available" 2 "Not Operable" 1 "Derated Operation" 0 "Normal Operation" ;
VAL_ 2566645246 HVESFanServiceInd 3 "Not Available" 2 "Reserved" 1 "Service Required" 0 "Service Not Required" ;
VAL_ 2566645246 HVESFanCmdStatus 3 "Not Available" 2 "Default Command" 1 "External Command" 0 "Internal Command" ;
VAL_ 2566645246 HVESFanStatusReasonCode 15 "Not Available" 14 "Reserved" 13 "Reserved" 12 "Reserved" 11 "Reserved" 10 "Reserved" 9 "Reserved" 8 "Reserved" 7 "Reserved" 6 "Speed limited due to maximum system design capability" 5 "Speed Limited due to current" 4 "Over-Temperature Protection Shutdown" 3 "Under-Voltage Protection Shutdown" 2 "Over-Voltage Protection Shutdown" 1 "Unable to Start" 0 "Normal Operation" ;
VAL_ 2566645246 HVESFanEnableStatus 3 "Not available" 2 "Fan On, Reverse Direction" 1 "Fan On, Normal" 0 "Fan Off" ;
VAL_ 2566644990 FrontFuelRecpCoverStatus 3 "Not available" 2 "Error" 1 "Receptacle cover is attached" 0 "Receptacle cover is detached" ;
VAL_ 2566644990 PsgrSideFuelRecp2CoverStatus 3 "Not available" 2 "Error" 1 "Receptacle cover is attached" 0 "Receptacle cover is detached" ;
VAL_ 2566644990 PsgrSideFuelRecp1CoverStatus 3 "Not available" 2 "Error" 1 "Receptacle cover is attached" 0 "Receptacle cover is detached" ;
VAL_ 2566644990 DriverSideFuelRecp2CoverStatus 3 "Not available" 2 "Error" 1 "Receptacle cover is attached" 0 "Receptacle cover is detached" ;
VAL_ 2566644990 DriverSideFuelRecp1CoverStatus 3 "Not available" 2 "Error" 1 "Receptacle cover is attached" 0 "Receptacle cover is detached" ;
VAL_ 2566643198 EnableStatusOfDoor20 3 "Not available" 2 "Error" 1 "Door enabled" 0 "Door disabled" ;
VAL_ 2566643198 OpenStatusOfDoor20 3 "Not available" 2 "Error" 1 "Door opened" 0 "Door closed" ;
VAL_ 2566643198 LockStatusOfDoor20 3 "Not available" 2 "Error" 1 "Locked" 0 "Unlocked" ;
VAL_ 2566643198 EnableStatusOfDoor19 3 "Not available" 2 "Error" 1 "Door enabled" 0 "Door disabled" ;
VAL_ 2566643198 OpenStatusOfDoor19 3 "Not available" 2 "Error" 1 "Door opened" 0 "Door closed" ;
VAL_ 2566643198 LockStatusOfDoor19 3 "Not available" 2 "Error" 1 "Locked" 0 "Unlocked" ;
VAL_ 2566643198 EnableStatusOfDoor18 3 "Not available" 2 "Error" 1 "Door enabled" 0 "Door disabled" ;
VAL_ 2566643198 OpenStatusOfDoor18 3 "Not available" 2 "Error" 1 "Door opened" 0 "Door closed" ;
VAL_ 2566643198 LockStatusOfDoor18 3 "Not available" 2 "Error" 1 "Locked" 0 "Unlocked" ;
VAL_ 2566643198 EnableStatusOfDoor17 3 "Not available" 2 "Error" 1 "Door enabled" 0 "Door disabled" ;
VAL_ 2566643198 OpenStatusOfDoor17 3 "Not available" 2 "Error" 1 "Door opened" 0 "Door closed" ;
VAL_ 2566643198 LockStatusOfDoor17 3 "Not available" 2 "Error" 1 "Locked" 0 "Unlocked" ;
VAL_ 2566643198 EnableStatusOfDoor16 3 "Not available" 2 "Error" 1 "Door enabled" 0 "Door disabled" ;
VAL_ 2566643198 OpenStatusOfDoor16 3 "Not available" 2 "Error" 1 "Door opened" 0 "Door closed" ;
VAL_ 2566643198 LockStatusOfDoor16 3 "Not available" 2 "Error" 1 "Locked" 0 "Unlocked" ;
VAL_ 2566643198 EnableStatusOfDoor15 3 "Not available" 2 "Error" 1 "Door enabled" 0 "Door disabled" ;
VAL_ 2566643198 OpenStatusOfDoor15 3 "Not available" 2 "Error" 1 "Door opened" 0 "Door closed" ;
VAL_ 2566643198 LockStatusOfDoor15 3 "Not available" 2 "Error" 1 "Locked" 0 "Unlocked" ;
VAL_ 2566643198 EnableStatusOfDoor14 3 "Not available" 2 "Error" 1 "Door enabled" 0 "Door disabled" ;
VAL_ 2566643198 OpenStatusOfDoor14 3 "Not available" 2 "Error" 1 "Door opened" 0 "Door closed" ;
VAL_ 2566643198 LockStatusOfDoor14 3 "Not available" 2 "Error" 1 "Locked" 0 "Unlocked" ;
VAL_ 2566643198 EnableStatusOfDoor13 3 "Not available" 2 "Error" 1 "Door enabled" 0 "Door disabled" ;
VAL_ 2566643198 OpenStatusOfDoor13 3 "Not available" 2 "Error" 1 "Door opened" 0 "Door closed" ;
VAL_ 2566643198 LockStatusOfDoor13 3 "Not available" 2 "Error" 1 "Locked" 0 "Unlocked" ;
VAL_ 2566643198 EnableStatusOfDoor12 3 "Not available" 2 "Error" 1 "Door enabled" 0 "Door disabled" ;
VAL_ 2566643198 OpenStatusOfDoor12 3 "Not available" 2 "Error" 1 "Door opened" 0 "Door closed" ;
VAL_ 2566643198 LockStatusOfDoor12 3 "Not available" 2 "Error" 1 "Locked" 0 "Unlocked" ;
VAL_ 2566643198 EnableStatusOfDoor11 3 "Not available" 2 "Error" 1 "Door enabled" 0 "Door disabled" ;
VAL_ 2566643198 OpenStatusOfDoor11 3 "Not available" 2 "Error" 1 "Door opened" 0 "Door closed" ;
VAL_ 2566643198 LockStatusOfDoor11 3 "Not available" 2 "Error" 1 "Locked" 0 "Unlocked" ;
VAL_ 2566642942 EnableStatusOfDoor30 3 "Not available" 2 "Error" 1 "Door enabled" 0 "Door disabled" ;
VAL_ 2566642942 OpenStatusOfDoor30 3 "Not available" 2 "Error" 1 "Door opened" 0 "Door closed" ;
VAL_ 2566642942 LockStatusOfDoor30 3 "Not available" 2 "Error" 1 "Locked" 0 "Unlocked" ;
VAL_ 2566642942 EnableStatusOfDoor29 3 "Not available" 2 "Error" 1 "Door enabled" 0 "Door disabled" ;
VAL_ 2566642942 OpenStatusOfDoor29 3 "Not available" 2 "Error" 1 "Door opened" 0 "Door closed" ;
VAL_ 2566642942 LockStatusOfDoor29 3 "Not available" 2 "Error" 1 "Locked" 0 "Unlocked" ;
VAL_ 2566642942 EnableStatusOfDoor28 3 "Not available" 2 "Error" 1 "Door enabled" 0 "Door disabled" ;
VAL_ 2566642942 OpenStatusOfDoor28 3 "Not available" 2 "Error" 1 "Door opened" 0 "Door closed" ;
VAL_ 2566642942 LockStatusOfDoor28 3 "Not available" 2 "Error" 1 "Locked" 0 "Unlocked" ;
VAL_ 2566642942 EnableStatusOfDoor27 3 "Not available" 2 "Error" 1 "Door enabled" 0 "Door disabled" ;
VAL_ 2566642942 OpenStatusOfDoor27 3 "Not available" 2 "Error" 1 "Door opened" 0 "Door closed" ;
VAL_ 2566642942 LockStatusOfDoor27 3 "Not available" 2 "Error" 1 "Locked" 0 "Unlocked" ;
VAL_ 2566642942 EnableStatusOfDoor26 3 "Not available" 2 "Error" 1 "Door enabled" 0 "Door disabled" ;
VAL_ 2566642942 OpenStatusOfDoor26 3 "Not available" 2 "Error" 1 "Door opened" 0 "Door closed" ;
VAL_ 2566642942 LockStatusOfDoor26 3 "Not available" 2 "Error" 1 "Locked" 0 "Unlocked" ;
VAL_ 2566642942 EnableStatusOfDoor25 3 "Not available" 2 "Error" 1 "Door enabled" 0 "Door disabled" ;
VAL_ 2566642942 OpenStatusOfDoor25 3 "Not available" 2 "Error" 1 "Door opened" 0 "Door closed" ;
VAL_ 2566642942 LockStatusOfDoor25 3 "Not available" 2 "Error" 1 "Locked" 0 "Unlocked" ;
VAL_ 2566642942 EnableStatusOfDoor24 3 "Not available" 2 "Error" 1 "Door enabled" 0 "Door disabled" ;
VAL_ 2566642942 OpenStatusOfDoor24 3 "Not available" 2 "Error" 1 "Door opened" 0 "Door closed" ;
VAL_ 2566642942 LockStatusOfDoor24 3 "Not available" 2 "Error" 1 "Locked" 0 "Unlocked" ;
VAL_ 2566642942 EnableStatusOfDoor23 3 "Not available" 2 "Error" 1 "Door enabled" 0 "Door disabled" ;
VAL_ 2566642942 OpenStatusOfDoor23 3 "Not available" 2 "Error" 1 "Door opened" 0 "Door closed" ;
VAL_ 2566642942 LockStatusOfDoor23 3 "Not available" 2 "Error" 1 "Locked" 0 "Unlocked" ;
VAL_ 2566642942 EnableStatusOfDoor22 3 "Not available" 2 "Error" 1 "Door enabled" 0 "Door disabled" ;
VAL_ 2566642942 OpenStatusOfDoor22 3 "Not available" 2 "Error" 1 "Door opened" 0 "Door closed" ;
VAL_ 2566642942 LockStatusOfDoor22 3 "Not available" 2 "Error" 1 "Locked" 0 "Unlocked" ;
VAL_ 2566642942 EnableStatusOfDoor21 3 "Not available" 2 "Error" 1 "Door enabled" 0 "Door disabled" ;
VAL_ 2566642942 OpenStatusOfDoor21 3 "Not available" 2 "Error" 1 "Door opened" 0 "Door closed" ;
VAL_ 2566642942 LockStatusOfDoor21 3 "Not available" 2 "Error" 1 "Locked" 0 "Unlocked" ;
VAL_ 2633750526 PGNModifiedStatus 3 "Not Available" 2 "PGN뭩 transmit status could be modified as requested" 1 "PGN뭩 transmit status was not requested to be modified" 0 "PGN뭩 transmit status could not be modified" ;
VAL_ 2633750526 PGNPendingChangeStatus 3 "Not Available" 2 "No pending transmit change for the port identified in SPN 8599." 1 "Pending transmit change to enable for the port identified in SPN 8599." 0 "Pending transmit change to disable for the port identified in SPN 8599." ;
VAL_ 2633750526 PGNCurTransmitStatus 3 "Not Available" 2 "The PGN transmit capability cannot be modified" 1 "PGN is not currently configured for transmit on the port identified in SPN 8599." 0 "PGN is currently configured for transmit on the port identified in SPN 8599." ;
VAL_ 2633750526 PortCmdStatus 7 "Not Available" 6 "SAE Reserved" 5 "SAE Reserved" 4 "SAE Reserved" 3 "SAE Reserved" 2 "No Configurable PGNs exist for the port identified in SPN 8599." 1 "	Negative Acknowledgment" 0 "Positive Acknowledgment" ;
VAL_ 2633750526 PortPendingChangesStatus 1 "Transmit changes are pending for one or more supported PGNs on the port identified in SPN 8599." 0 "No pending changes to the transmit status for any supported PGNs for the port identified in SPN 8599." ;
VAL_ 2633750526 Port 15 "SAE Reserved" 14 "SAE Reserved" 13 "SAE Reserved" 12 "SAE Reserved" 11 "SAE Reserved" 10 "Port 10" 9 "Port 9" 8 "Port 8" 7 "Port 7" 6 "Port 6" 5 "Port 5" 4 "Port 4" 3 "Port 3" 2 "Port 2" 1 "Port 1" 0 "Current port" ;
VAL_ 2431719166 FluidEndVlvLeak 3 "Not Available" 2 "Error" 1 "Leak Detected" 0 "No Leak Detected" ;
VAL_ 2431719166 CavitationStatus 7 "Not Available" 6 "Error" 5 "Reserved" 4 "Reserved" 3 "High" 2 "Medium" 1 "Low" 0 "No Cavitation" ;
VAL_ 2364609534 PLDueToUndefinedReason 3 "Not Available" 2 "Error" 1 "Power limited for this reason" 0 "No power limit for this reason" ;
VAL_ 2364609534 PLDueToSLIBatTermTemp 3 "Not Available" 2 "Error" 1 "Power limited for this reason" 0 "No power limit for this reason" ;
VAL_ 2364609534 PLDueToSLIBatTermCur 3 "Not Available" 2 "Error" 1 "Power limited for this reason" 0 "No power limit for this reason" ;
VAL_ 2364609534 PLDueToSLIBatTermV 3 "Not Available" 2 "Error" 1 "Power limited for this reason" 0 "No power limit for this reason" ;
VAL_ 2364609534 PLDueToPwrETemp 3 "Not Available" 2 "Error" 1 "Power limited for this reason" 0 "No power limit for this reason" ;
VAL_ 2364609534 PLDueToElectronicFilterTemp 3 "Not available" 2 "Error" 1 "Power limited for this reason" 0 "No power limit for this reason" ;
VAL_ 2364609534 PLDueToCtrlTemp 3 "Not Available" 2 "Error" 1 "Power limited for this reason" 0 "No power limit for this reason" ;
VAL_ 2364609534 PLDueToLowSideVMax 3 "Not Available" 2 "Error" 1 "Power limited for this reason" 0 "No power limit for this reason" ;
VAL_ 2364609534 PLDueToLowSideVMin 3 "Not Available" 2 "Error" 1 "Power limited for this reason" 0 "No power limit for this reason" ;
VAL_ 2364609534 PLDueToHiSideVMax 3 "Not Available" 2 "Error" 1 "Power limited for this reason" 0 "No power limit for this reason" ;
VAL_ 2364609534 PLDueToHiSideVMin 3 "Not Available" 2 "Error" 1 "Power limited for this reason" 0 "No power limit for this reason" ;
VAL_ 2364609534 PLDueToLowSideCur 3 "Not Available" 2 "Error" 1 "Power limited for this reason" 0 "No power limit for this reason" ;
VAL_ 2364609534 PLDueToHiSideCur 3 "Not Available" 2 "Error" 1 "Power limited for this reason" 0 "No power limit for this reason" ;
VAL_ 2364609534 LoadshedReq 3 "Don't Care/Take No Action" 2 "Loadshed Requested,  Shutdown Imminent" 1 "Loadshed Requested" 0 "No Loadshed Requested" ;
VAL_ 2364609534 HVILStatus 3 "Not Available" 2 "Error" 1 "HVIL Open" 0 "HVIL Closed" ;
VAL_ 2364609534 OperationalStatus 15 "Not Available" 14 "Error" 13 "Manufacturer assignable state" 12 "Reserved" 11 "Reserved" 10 "Reserved" 9 "Reserved" 8 "Reserved" 7 "Reserved" 6 "Disabled due to malfunction or protection" 5 "Normal power down in process" 4 "Operational, Boost mode" 3 "Operational, Buck mode" 2 "Operational, Standby" 1 "Initialization in process" 0 "Disabled" ;
VAL_ 2364609278 OperationalCmd 15 "Don't care/ Take No Action" 13 "Reserved" 12 "Reserved" 11 "Reserved" 10 "Reserved" 9 "Reserved" 8 "Reserved" 7 "Reserved" 6 "Reserved" 5 "Reserved" 4 "Power down DC/DC Converter" 3 "Operate in boost mode" 2 "Operate in buck mode" 1 "Operate in standby mode" 0 "Disable" ;
VAL_ 2297499902 BrkPedalSw2 3 "Not Available" 2 "Error" 1 "Brake pedal depressed" 0 "Brake pedal released" ;
VAL_ 2364606974 TMSMode 15 "Not Available" 14 "Faulted" 4 "Drying" 3 "Heating" 2 "Cooling" 1 "Circulating" 0 "Off" ;
VAL_ 2364606974 TMSHtrStatus 3 "Not Available" 2 "Error" 1 "Heater On" 0 "Heater Off" ;
VAL_ 2364606718 Module16OperationalStatus 3 "Not Available" 2 "Error" 1 "Operational" 0 "Not Operational" ;
VAL_ 2364606718 Module15OperationalStatus 3 "Not Available" 2 "Error" 1 "Operational" 0 "Not Operational" ;
VAL_ 2364606718 Module14OperationalStatus 3 "Not Available" 2 "Error" 1 "Operational" 0 "Not Operational" ;
VAL_ 2364606718 Module13OperationalStatus 3 "Not Available" 2 "Error" 1 "Operational" 0 "Not Operational" ;
VAL_ 2364606718 Module12OperationalStatus 3 "Not Available" 2 "Error" 1 "Operational" 0 "Not Operational" ;
VAL_ 2364606718 Module11OperationalStatus 3 "Not Available" 2 "Error" 1 "Operational" 0 "Not Operational" ;
VAL_ 2364606718 Module10OperationalStatus 3 "Not Available" 2 "Error" 1 "Operational" 0 "Not Operational" ;
VAL_ 2364606718 Module9OperationalStatus 3 "Not Available" 2 "Error" 1 "Operational" 0 "Not Operational" ;
VAL_ 2364606718 Module8OperationalStatus 3 "Not Available" 2 "Error" 1 "Operational" 0 "Not Operational" ;
VAL_ 2364606718 Module7OperationalStatus 3 "Not Available" 2 "Error" 1 "Operational" 0 "Not Operational" ;
VAL_ 2364606718 Module6OperationalStatus 3 "Not Available" 2 "Error" 1 "Operational" 0 "Not Operational" ;
VAL_ 2364606718 Module5OperationalStatus 3 "Not Available" 2 "Error" 1 "Operational" 0 "Not Operational" ;
VAL_ 2364606718 Module4OperationalStatus 3 "Not Available" 2 "Error" 1 "Operational" 0 "Not Operational" ;
VAL_ 2364606718 Module3OperationalStatus 3 "Not Available" 2 "Error" 1 "Operational" 0 "Not Operational" ;
VAL_ 2364606718 Module2OperationalStatus 3 "Not Available" 2 "Error" 1 "Operational" 0 "Not Operational" ;
VAL_ 2364606718 Module1OperationalStatus 3 "Not Available" 2 "Error" 1 "Operational" 0 "Not Operational" ;
VAL_ 2364604926 PitchLmtSt 7 "Not available" 6 "Non recoverable fault" 5 "Reserved" 4 "Reserved" 3 "Limited Low" 2 "Limited High" 1 "Operator limited/controlled" 0 "Not limited" ;
VAL_ 2364604926 LmtSt 7 "Not available" 6 "Non recoverable fault" 5 "Reserved" 4 "Reserved" 3 "Limited Low" 2 "Limited High" 1 "Operator limited/controlled" 0 "Not limited" ;
VAL_ 2364604414 PitchLmtSt 7 "Not available" 6 "Non recoverable fault" 5 "Reserved" 4 "Reserved" 3 "Limited Low" 2 "Limited High" 1 "Operator limited/controlled" 0 "Not limited" ;
VAL_ 2364604414 LmtSt 7 "Not available" 6 "Non recoverable fault" 5 "Reserved" 4 "Reserved" 3 "Limited Low" 2 "Limited High" 1 "Operator limited/controlled" 0 "Not limited" ;
VAL_ 2565923838 HVILStatus 3 "Not Available" 2 "Error" 1 "HVIL Open" 0 "HVIL Closed" ;
VAL_ 2565923838 LoadshedReq 3 "Don't Care/Take No Action" 2 "Loadshed Requested,  Shutdown Imminent" 1 "Loadshed Requested" 0 "No Loadshed Requested" ;
VAL_ 2565923838 StatusFeedback 7 "Not Available" 6 "Error" 5 "Reserved" 4 "Normal Power Down in Process" 3 "Output Faulted Off" 2 "Output Faulted On" 1 "Output Enabled" 0 "Output Disabled" ;
VAL_ 2565923582 EnableCmd 3 "Not Available" 2 "Power down DC/AC Accessory Inverter Controller" 1 "Enable DC/AC Accessory Inverter Output" 0 "Disable DC/AC Accessory Inverter Output" ;
VAL_ 2565923582 Device2Status 7 "Not Available" 6 "Error" 5 "Reserved for SAE Assignment" 4 "Reserved for SAE Assignment" 3 "Faulted Off" 2 "Faulted On" 1 "Off" 0 "On" ;
VAL_ 2565923582 Device1Status 7 "Not Available" 6 "Error" 5 "Reserved for SAE Assignment" 4 "Reserved for SAE Assignment" 3 "Faulted Off" 2 "Faulted On" 1 "Off" 0 "On" ;
VAL_ 2565922814 HVILStatus 3 "Not Available" 2 "Error" 1 "HVIL Open" 0 "HVIL Closed" ;
VAL_ 2565922814 LoadshedReq 3 "Don't Care/Take No Action" 2 "Loadshed Requested,  Shutdown Imminent" 1 "Loadshed Requested" 0 "No Loadshed Requested" ;
VAL_ 2565922814 StatusFeedback 7 "Not Available" 6 "Error" 5 "Reserved" 4 "Normal Power Down in Process" 3 "Output Faulted Off" 2 "Output Faulted On" 1 "Output Enabled" 0 "Output Disabled" ;
VAL_ 2565922558 EnableCmd 3 "Not Available" 2 "Power down DC/AC Accessory Inverter Controller" 1 "Enable DC/AC Accessory Inverter Output" 0 "Disable DC/AC Accessory Inverter Output" ;
VAL_ 2565922558 Device2Status 7 "Not Available" 6 "Error" 5 "Reserved for SAE Assignment" 4 "Reserved for SAE Assignment" 3 "Faulted Off" 2 "Faulted On" 1 "Off" 0 "On" ;
VAL_ 2565922558 Device1Status 7 "Not Available" 6 "Error" 5 "Reserved for SAE Assignment" 4 "Reserved for SAE Assignment" 3 "Faulted Off" 2 "Faulted On" 1 "Off" 0 "On" ;
VAL_ 2565921790 HVILStatus 3 "Not Available" 2 "Error" 1 "HVIL Open" 0 "HVIL Closed" ;
VAL_ 2565921790 LoadshedReq 3 "Don't Care/Take No Action" 2 "Loadshed Requested,  Shutdown Imminent" 1 "Loadshed Requested" 0 "No Loadshed Requested" ;
VAL_ 2565921790 StatusFeedback 7 "Not Available" 6 "Error" 5 "Reserved" 4 "Normal Power Down in Process" 3 "Output Faulted Off" 2 "Output Faulted On" 1 "Output Enabled" 0 "Output Disabled" ;
VAL_ 2565921534 EnableCmd 3 "Not Available" 2 "Power down DC/AC Accessory Inverter Controller" 1 "Enable DC/AC Accessory Inverter Output" 0 "Disable DC/AC Accessory Inverter Output" ;
VAL_ 2565921534 Device2Status 7 "Not Available" 6 "Error" 5 "Reserved for SAE Assignment" 4 "Reserved for SAE Assignment" 3 "Faulted Off" 2 "Faulted On" 1 "Off" 0 "On" ;
VAL_ 2565921534 Device1Status 7 "Not Available" 6 "Error" 5 "Reserved for SAE Assignment" 4 "Reserved for SAE Assignment" 3 "Faulted Off" 2 "Faulted On" 1 "Off" 0 "On" ;
VAL_ 2565920766 HVILStatus 3 "Not Available" 2 "Error" 1 "HVIL Open" 0 "HVIL Closed" ;
VAL_ 2565920766 LoadshedReq 3 "Don't Care/Take No Action" 2 "Loadshed Requested,  Shutdown Imminent" 1 "Loadshed Requested" 0 "No Loadshed Requested" ;
VAL_ 2565920766 StatusFeedback 7 "Not Available" 6 "Error" 5 "Reserved" 4 "Normal Power Down in Process" 3 "Output Faulted Off" 2 "Output Faulted On" 1 "Output Enabled" 0 "Output Disabled" ;
VAL_ 2565920510 EnableCmd 3 "Not Available" 2 "Power down DC/AC Accessory Inverter Controller" 1 "Enable DC/AC Accessory Inverter Output" 0 "Disable DC/AC Accessory Inverter Output" ;
VAL_ 2565920510 Device2Status 7 "Not Available" 6 "Error" 5 "Reserved for SAE Assignment" 4 "Reserved for SAE Assignment" 3 "Faulted Off" 2 "Faulted On" 1 "Off" 0 "On" ;
VAL_ 2565920510 Device1Status 7 "Not Available" 6 "Error" 5 "Reserved for SAE Assignment" 4 "Reserved for SAE Assignment" 3 "Faulted Off" 2 "Faulted On" 1 "Off" 0 "On" ;
